VERSION ""

NS_ :

BS_:

BU_: EBOOST_HS CGM_HS BSM_HS HCP_B_HS AVM_HS PFAF_HS LVMPC_HS DCDC_HS TRCM_HS AMP_HS VICM2_HS FICM_HS ARS_HS MCP_B_HS MCP_A_HS ICCM_OBD_HS SAS_HS ACCM_HS VLBS_HS EBCM_OBD_HS HCP_T_HS EDI_HS HPCC_HS VITM_OBD_HS VICM_HS HCP_HS APPS_HS ICCM_HS EOCM_F_HS GPCM_HS VCM_HS HMIM_HS VES_HS Dummy_HS MCP_C_HS ONSTAR_HS EPS_HS TestTool_HS MCP_HS BCP_HS ALC_HS AHL_AFL_HS SADS_HS EPB_HS FCM_HS TCCM_HS RDCM_HS PTO_HS EBCM_HS ACC_HS BCM_HS TCM_HS ECM_HS

BO_ 2034 CCP_Data_Transmission_Object_HS: 8 PTO_HS
 SG_ DgnInf : 7|64@0+ (1,0) [0|1.84467440737096E+019] ""  TestTool_HS

BO_ 2032 CCP_Command_Receive_Object_HS: 8 TestTool_HS
 SG_ DgnInf : 7|64@0+ (1,0) [0|1.84467440737096E+019] ""  FCM_HS,PTO_HS

BO_ 563 Performance_Mode_Cust_Setings_HS: 5 EBCM_HS
 SG_ SPMCA_SusPrfMd6Avl : 32|1@0+ (1,0) [0|1] ""  BCM_HS
 SG_ SPMCA_SusPrfMd5Avl : 33|1@0+ (1,0) [0|1] ""  BCM_HS
 SG_ SPMCA_SusPrfMd4Avl : 34|1@0+ (1,0) [0|1] ""  BCM_HS
 SG_ SPMCA_SusPrfMd3Avl : 35|1@0+ (1,0) [0|1] ""  BCM_HS
 SG_ SPMCA_SusPrfMd2Avl : 36|1@0+ (1,0) [0|1] ""  BCM_HS
 SG_ SPMCA_SusPrfMd1Avl : 37|1@0+ (1,0) [0|1] ""  BCM_HS
 SG_ SPMCA_StrPrfMd6Avl : 24|1@0+ (1,0) [0|1] ""  BCM_HS
 SG_ SPMCA_StrPrfMd5Avl : 25|1@0+ (1,0) [0|1] ""  BCM_HS
 SG_ SPMCA_StrPrfMd4Avl : 26|1@0+ (1,0) [0|1] ""  BCM_HS
 SG_ SPMCA_StrPrfMd3Avl : 27|1@0+ (1,0) [0|1] ""  BCM_HS
 SG_ SPMCA_StrPrfMd2Avl : 28|1@0+ (1,0) [0|1] ""  BCM_HS
 SG_ SPMCA_StrPrfMd1Avl : 29|1@0+ (1,0) [0|1] ""  BCM_HS
 SG_ SPMCA_SndPrfMd6Avl : 16|1@0+ (1,0) [0|1] ""  BCM_HS
 SG_ SPMCA_SndPrfMd5Avl : 17|1@0+ (1,0) [0|1] ""  BCM_HS
 SG_ SPMCA_SndPrfMd4Avl : 18|1@0+ (1,0) [0|1] ""  BCM_HS
 SG_ SPMCA_SndPrfMd3Avl : 19|1@0+ (1,0) [0|1] ""  BCM_HS
 SG_ SPMCA_SndPrfMd2Avl : 20|1@0+ (1,0) [0|1] ""  BCM_HS
 SG_ SPMCA_SndPrfMd1Avl : 21|1@0+ (1,0) [0|1] ""  BCM_HS
 SG_ DPMCA_DispPrfMd6Avl : 8|1@0+ (1,0) [0|1] ""  BCM_HS
 SG_ DPMCA_DispPrfMd5Avl : 9|1@0+ (1,0) [0|1] ""  BCM_HS
 SG_ DPMCA_DispPrfMd4Avl : 10|1@0+ (1,0) [0|1] ""  BCM_HS
 SG_ DPMCA_DispPrfMd3Avl : 11|1@0+ (1,0) [0|1] ""  BCM_HS
 SG_ DPMCA_DispPrfMd2Avl : 12|1@0+ (1,0) [0|1] ""  BCM_HS
 SG_ DPMCA_DispPrfMd1Avl : 13|1@0+ (1,0) [0|1] ""  BCM_HS
 SG_ DPMCA_DrvlPrfMd6Avl : 0|1@0+ (1,0) [0|1] ""  BCM_HS
 SG_ DPMCA_DrvlPrfMd5Avl : 1|1@0+ (1,0) [0|1] ""  BCM_HS
 SG_ DPMCA_DrvlPrfMd4Avl : 2|1@0+ (1,0) [0|1] ""  BCM_HS
 SG_ DPMCA_DrvlPrfMd3Avl : 3|1@0+ (1,0) [0|1] ""  BCM_HS
 SG_ DPMCA_DrvlPrfMd2Avl : 4|1@0+ (1,0) [0|1] ""  BCM_HS
 SG_ DPMCA_DrvlPrfMd1Avl : 5|1@0+ (1,0) [0|1] ""  BCM_HS

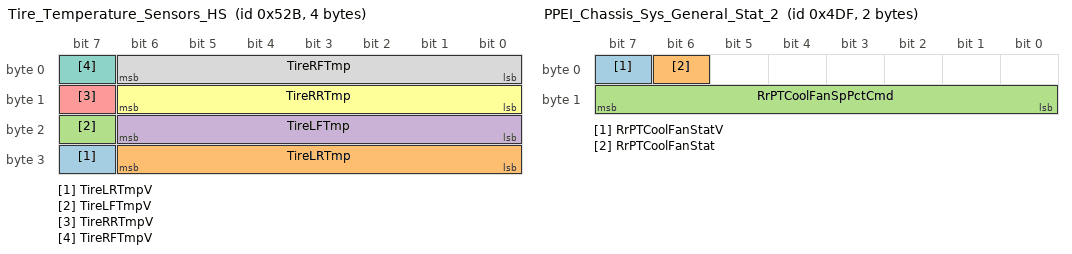
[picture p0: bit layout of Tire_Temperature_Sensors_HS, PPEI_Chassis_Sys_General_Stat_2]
BO_ 1323 Tire_Temperature_Sensors_HS: 4 BCM_HS
 SG_ TireLRTmpV : 31|1@0+ (1,0) [0|1] ""  CGM_HS,LVMPC_HS,EDI_HS,EBCM_OBD_HS,EBCM_HS,ICCM_OBD_HS,ICCM_HS,RDCM_HS
 SG_ TireLRTmp : 30|7@0+ (1,-20) [-20|107] "deg C"  CGM_HS,LVMPC_HS,EDI_HS,EBCM_OBD_HS,EBCM_HS,ICCM_OBD_HS,ICCM_HS,RDCM_HS
 SG_ TireLFTmpV : 23|1@0+ (1,0) [0|1] ""  CGM_HS,LVMPC_HS,EDI_HS,EBCM_OBD_HS,EBCM_HS,ICCM_OBD_HS,ICCM_HS,RDCM_HS
 SG_ TireLFTmp : 22|7@0+ (1,-20) [-20|107] "deg C"  CGM_HS,LVMPC_HS,EDI_HS,EBCM_OBD_HS,EBCM_HS,ICCM_OBD_HS,ICCM_HS,RDCM_HS
 SG_ TireRRTmpV : 15|1@0+ (1,0) [0|1] ""  CGM_HS,LVMPC_HS,EDI_HS,EBCM_OBD_HS,EBCM_HS,ICCM_OBD_HS,ICCM_HS,RDCM_HS
 SG_ TireRRTmp : 14|7@0+ (1,-20) [-20|107] "deg C"  CGM_HS,LVMPC_HS,EDI_HS,EBCM_OBD_HS,EBCM_HS,ICCM_OBD_HS,ICCM_HS,RDCM_HS
 SG_ TireRFTmpV : 7|1@0+ (1,0) [0|1] ""  CGM_HS,LVMPC_HS,EDI_HS,EBCM_OBD_HS,EBCM_HS,ICCM_OBD_HS,ICCM_HS,RDCM_HS
 SG_ TireRFTmp : 6|7@0+ (1,-20) [-20|107] "deg C"  CGM_HS,LVMPC_HS,EDI_HS,EBCM_OBD_HS,EBCM_HS,ICCM_OBD_HS,ICCM_HS,RDCM_HS

BO_ 1247 PPEI_Chassis_Sys_General_Stat_2: 2 ICCM_HS
 SG_ RrPTCoolFanStatV : 7|1@0+ (1,0) [0|1] ""  TCM_HS
 SG_ RrPTCoolFanStat : 6|1@0+ (1,0) [0|1] ""  TCM_HS
 SG_ RrPTCoolFanSpPctCmd : 15|8@0+ (0.392157,0) [0|100.000035] "%"  TCM_HS

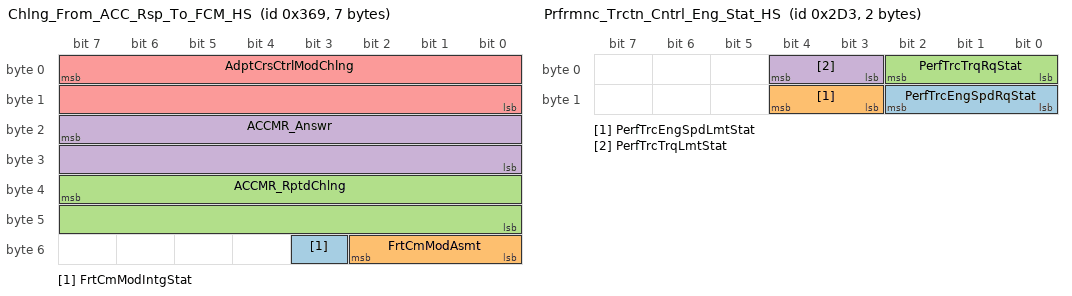
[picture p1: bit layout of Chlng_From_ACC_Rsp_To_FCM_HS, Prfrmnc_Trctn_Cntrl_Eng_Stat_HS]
BO_ 873 Chlng_From_ACC_Rsp_To_FCM_HS: 7 ACC_HS
 SG_ FrtCmModIntgStat : 51|1@0+ (1,0) [0|1] ""  FCM_HS
 SG_ FrtCmModAsmt : 50|3@0+ (1,0) [0|7] ""  FCM_HS
 SG_ ACCMR_RptdChlng : 39|16@0+ (1,0) [0|65535] ""  FCM_HS
 SG_ ACCMR_Answr : 23|16@0+ (1,0) [0|65535] ""  FCM_HS
 SG_ AdptCrsCtrlModChlng : 7|16@0+ (1,0) [0|65535] ""  FCM_HS

BO_ 306 Exhst_Heat_Recvry_Mngmnt_HS: 1 VICM2_HS
 SG_ ClntCrcFlwRtEst : 7|8@0+ (0.392157,0) [0|100.000035] "%"  BCM_HS

BO_ 723 Prfrmnc_Trctn_Cntrl_Eng_Stat_HS: 2 ECM_HS
 SG_ PerfTrcEngSpdRqStat : 10|3@0+ (1,0) [0|7] ""  EBCM_OBD_HS,EBCM_HS
 SG_ PerfTrcEngSpdLmtStat : 12|2@0+ (1,0) [0|3] ""  EBCM_OBD_HS,EBCM_HS
 SG_ PerfTrcTrqRqStat : 2|3@0+ (1,0) [0|7] ""  EBCM_OBD_HS,EBCM_HS
 SG_ PerfTrcTrqLmtStat : 4|2@0+ (1,0) [0|3] ""  EBCM_OBD_HS,EBCM_HS

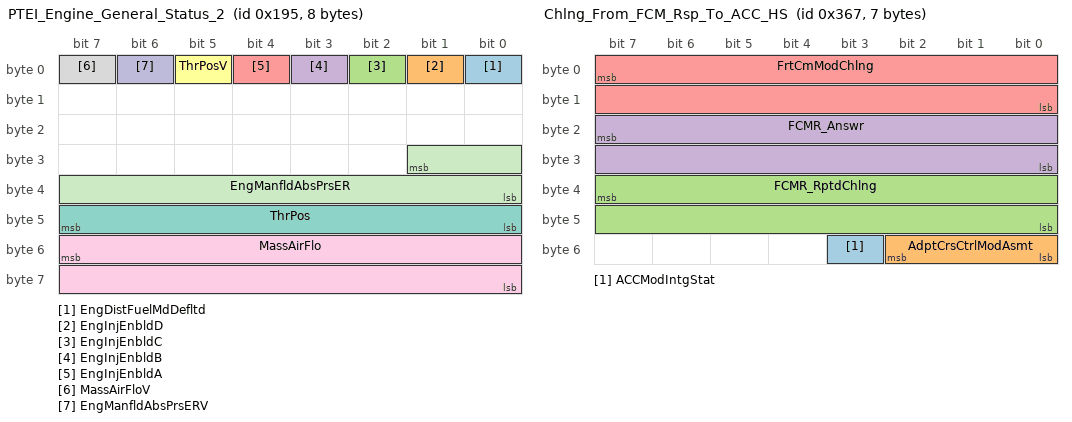
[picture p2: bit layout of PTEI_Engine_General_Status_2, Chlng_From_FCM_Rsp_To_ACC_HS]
BO_ 405 PTEI_Engine_General_Status_2: 8 ECM_HS
 SG_ EngDistFuelMdDefltd : 0|1@0+ (1,0) [0|1] ""  FICM_HS
 SG_ EngInjEnbldD : 1|1@0+ (1,0) [0|1] ""  FICM_HS
 SG_ EngInjEnbldC : 2|1@0+ (1,0) [0|1] ""  FICM_HS
 SG_ EngInjEnbldB : 3|1@0+ (1,0) [0|1] ""  FICM_HS
 SG_ EngInjEnbldA : 4|1@0+ (1,0) [0|1] ""  FICM_HS
 SG_ ThrPosV : 5|1@0+ (1,0) [0|1] ""  FICM_HS
 SG_ ThrPos : 47|8@0+ (0.392157,0) [0|100.000035] "%"  FICM_HS
 SG_ MassAirFloV : 7|1@0+ (1,0) [0|1] ""  VCM_HS,FICM_HS
 SG_ MassAirFlo : 55|16@0+ (0.01,0) [0|655.35] "grams/s"  VCM_HS,FICM_HS
 SG_ EngManfldAbsPrsERV : 6|1@0+ (1,0) [0|1] ""  FICM_HS
 SG_ EngManfldAbsPrsER : 25|10@0+ (0.5,0) [0|511.5] "kPa"  FICM_HS

BO_ 419 PTEI_Engine_Common_Use_1: 1 ECM_HS
 SG_ EngRunng : 7|1@0+ (1,0) [0|1] ""  HCP_B_HS,HCP_T_HS,BCM_HS,DCDC_HS,TCCM_HS,EBCM_OBD_HS,EBCM_HS,MCP_C_HS,MCP_B_HS,MCP_A_HS,FICM_HS,TCM_HS,HCP_HS,BCP_HS

BO_ 289 ADASIS_RawData_Multiplexed_HS: 8 HMIM_HS
 SG_ ARDM_RawData : 4|61@0+ (1,0) [0|2.30584300921369E+018] ""  Dummy_HS
 SG_ ARDM_MsgType : 7|3@0+ (1,0) [0|7] ""  Dummy_HS

BO_ 871 Chlng_From_FCM_Rsp_To_ACC_HS: 7 FCM_HS
 SG_ ACCModIntgStat : 51|1@0+ (1,0) [0|1] ""  ACC_HS
 SG_ AdptCrsCtrlModAsmt : 50|3@0+ (1,0) [0|7] ""  ACC_HS
 SG_ FCMR_RptdChlng : 39|16@0+ (1,0) [0|65535] ""  ACC_HS
 SG_ FCMR_Answr : 23|16@0+ (1,0) [0|65535] ""  ACC_HS
 SG_ FrtCmModChlng : 7|16@0+ (1,0) [0|65535] ""  ACC_HS

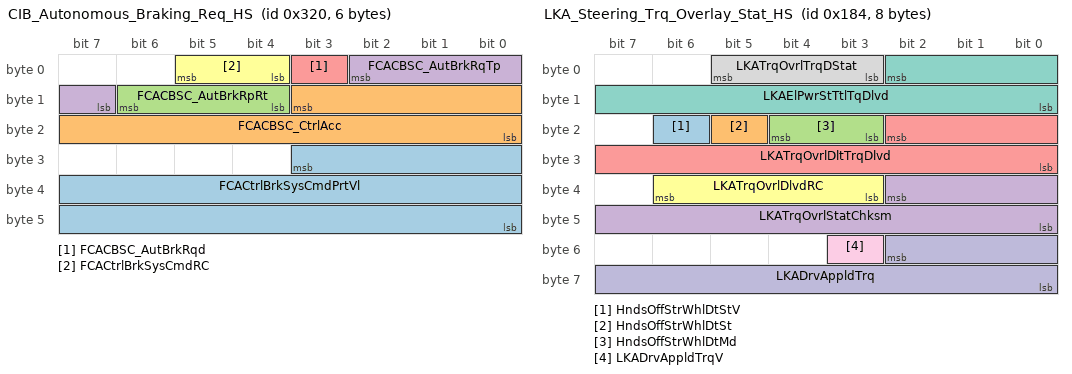
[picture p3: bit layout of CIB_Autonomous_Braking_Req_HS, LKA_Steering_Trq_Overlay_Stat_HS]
BO_ 800 CIB_Autonomous_Braking_Req_HS: 6 FCM_HS
 SG_ FCACtrlBrkSysCmdPrtVl : 27|20@0+ (1,0) [0|1048575] ""  EBCM_OBD_HS,EBCM_HS
 SG_ FCACBSC_CtrlAcc : 11|12@0- (0.01,0) [-20.48|20.47] "m/s^2"  EBCM_OBD_HS,EBCM_HS
 SG_ FCACBSC_AutBrkRpRt : 14|3@0+ (1,0) [0|7] ""  EBCM_OBD_HS,EBCM_HS
 SG_ FCACBSC_AutBrkRqTp : 2|4@0+ (1,0) [0|15] ""  EBCM_OBD_HS,EBCM_HS
 SG_ FCACBSC_AutBrkRqd : 3|1@0+ (1,0) [0|1] ""  EBCM_OBD_HS,EBCM_HS
 SG_ FCACtrlBrkSysCmdRC : 5|2@0+ (1,0) [0|3] ""  EBCM_OBD_HS,EBCM_HS

BO_ 388 LKA_Steering_Trq_Overlay_Stat_HS: 8 EPS_HS
 SG_ HndsOffStrWhlDtStV : 22|1@0+ (1,0) [0|1] ""  CGM_HS,EOCM_F_HS,FCM_HS
 SG_ HndsOffStrWhlDtSt : 21|1@0+ (1,0) [0|1] ""  CGM_HS,EOCM_F_HS,FCM_HS
 SG_ HndsOffStrWhlDtMd : 20|2@0+ (1,0) [0|3] ""  CGM_HS,EOCM_F_HS,FCM_HS
 SG_ LKATrqOvrlStatChksm : 34|11@0+ (1,0) [0|2047] ""  CGM_HS,EOCM_F_HS,FCM_HS
 SG_ LKATrqOvrlDltTrqDlvd : 18|11@0- (0.01,0) [-10.24|10.23] "Nm"  CGM_HS,EOCM_F_HS,FCM_HS
 SG_ LKATrqOvrlDlvdRC : 38|4@0+ (1,0) [0|15] ""  CGM_HS,EOCM_F_HS,FCM_HS
 SG_ LKAElPwrStTtlTqDlvd : 2|11@0- (0.01,0) [-10.24|10.23] "Nm"  CGM_HS,EOCM_F_HS,FCM_HS
 SG_ LKATrqOvrlTrqDStat : 5|3@0+ (1,0) [0|7] ""  CGM_HS,EOCM_F_HS,FCM_HS
 SG_ LKADrvAppldTrqV : 51|1@0+ (1,0) [0|1] ""  CGM_HS,EOCM_F_HS,FCM_HS
 SG_ LKADrvAppldTrq : 50|11@0- (0.01,0) [-10.24|10.23] "Nm"  CGM_HS,EOCM_F_HS,FCM_HS

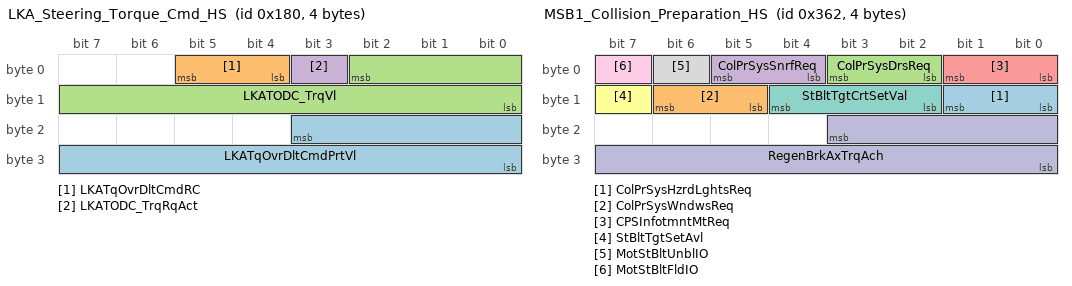
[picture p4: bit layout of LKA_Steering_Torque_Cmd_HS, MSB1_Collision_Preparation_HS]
BO_ 384 LKA_Steering_Torque_Cmd_HS: 4 FCM_HS
 SG_ LKATqOvrDltCmdPrtVl : 19|12@0+ (1,0) [0|4095] ""  EPS_HS
 SG_ LKATqOvrDltCmdRC : 5|2@0+ (1,0) [0|3] ""  EPS_HS
 SG_ LKATODC_TrqVl : 2|11@0- (0.01,0) [-10.24|10.23] "Nm"  BCM_HS,EPS_HS
 SG_ LKATODC_TrqRqAct : 3|1@0+ (1,0) [0|1] ""  BCM_HS,EPS_HS

BO_ 866 MSB1_Collision_Preparation_HS: 4 EBCM_HS
 SG_ ColPrSysHzrdLghtsReq : 9|2@0+ (1,0) [0|3] ""  BCM_HS
 SG_ ColPrSysWndwsReq : 14|2@0+ (1,0) [0|3] ""  BCM_HS
 SG_ ColPrSysDrsReq : 3|2@0+ (1,0) [0|3] ""  BCM_HS
 SG_ ColPrSysSnrfReq : 5|2@0+ (1,0) [0|3] ""  BCM_HS
 SG_ CPSInfotmntMtReq : 1|2@0+ (1,0) [0|3] ""  BCM_HS
 SG_ StBltTgtSetAvl : 15|1@0+ (1,0) [0|1] ""  BCM_HS
 SG_ StBltTgtCrtSetVal : 12|3@0+ (1,0) [0|7] ""  BCM_HS
 SG_ MotStBltUnblIO : 6|1@0+ (1,0) [0|1] ""  BCM_HS
 SG_ MotStBltFldIO : 7|1@0+ (1,0) [0|1] ""  BCM_HS
 SG_ RegenBrkAxTrqAch : 19|12@0+ (2,0) [0|8190] "Nm"  BSM_HS,VICM_HS

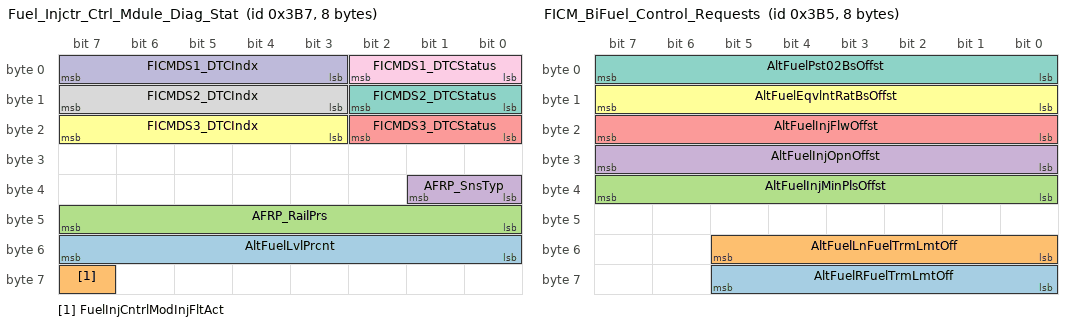
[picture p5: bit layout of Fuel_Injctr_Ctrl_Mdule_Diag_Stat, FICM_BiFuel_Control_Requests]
BO_ 951 Fuel_Injctr_Ctrl_Mdule_Diag_Stat: 8 FICM_HS
 SG_ AltFuelLvlPrcnt : 55|8@0+ (0.392157,0) [0|100.000035] "%"  ECM_HS
 SG_ FuelInjCntrlModInjFltAct : 63|1@0+ (1,0) [0|1] ""  ECM_HS
 SG_ AFRP_RailPrs : 47|8@0+ (3,0) [0|765] "kPa"  ECM_HS
 SG_ AFRP_SnsTyp : 33|2@0+ (1,0) [0|3] ""  ECM_HS
 SG_ FICMDS3_DTCStatus : 18|3@0+ (1,0) [0|7] ""  ECM_HS
 SG_ FICMDS3_DTCIndx : 23|5@0+ (1,0) [0|31] ""  ECM_HS
 SG_ FICMDS2_DTCStatus : 10|3@0+ (1,0) [0|7] ""  ECM_HS
 SG_ FICMDS2_DTCIndx : 15|5@0+ (1,0) [0|31] ""  ECM_HS
 SG_ FICMDS1_DTCStatus : 2|3@0+ (1,0) [0|7] ""  ECM_HS
 SG_ FICMDS1_DTCIndx : 7|5@0+ (1,0) [0|31] ""  ECM_HS

BO_ 949 FICM_BiFuel_Control_Requests: 8 FICM_HS
 SG_ AltFuelRFuelTrmLmtOff : 61|6@0- (0.01,0) [-0.32|0.31] ""  ECM_HS
 SG_ AltFuelLnFuelTrmLmtOff : 53|6@0- (0.01,0) [-0.32|0.31] ""  ECM_HS
 SG_ AltFuelInjMinPlsOffst : 39|8@0- (0.0313725,0) [-4.01568|3.9843075] "grams/s"  ECM_HS
 SG_ AltFuelInjOpnOffst : 31|8@0- (0.0313725,0) [-4.01568|3.9843075] "grams/s"  ECM_HS
 SG_ AltFuelInjFlwOffst : 23|8@0- (0.0313725,0) [-4.01568|3.9843075] "grams/s"  ECM_HS
 SG_ AltFuelEqvlntRatBsOffst : 15|8@0- (0.000392157,0) [-0.050196096|0.049803939] ""  ECM_HS
 SG_ AltFuelPst02BsOffst : 7|8@0- (4,0) [-512|508] "mVolts"  ECM_HS

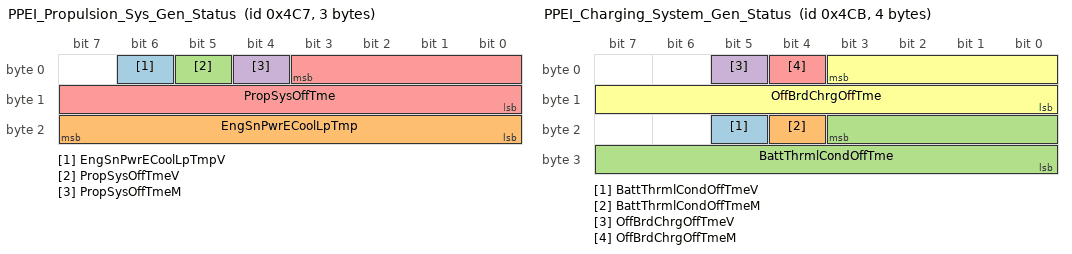
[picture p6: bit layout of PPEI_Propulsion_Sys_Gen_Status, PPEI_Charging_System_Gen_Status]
BO_ 1223 PPEI_Propulsion_Sys_Gen_Status: 3 ECM_HS
 SG_ EngSnPwrECoolLpTmpV : 6|1@0+ (1,0) [0|1] ""  BSM_HS,VICM_HS
 SG_ EngSnPwrECoolLpTmp : 23|8@0+ (1,-40) [-40|215] "deg C"  BSM_HS,VICM_HS
 SG_ PropSysOffTmeV : 5|1@0+ (1,0) [0|1] ""  HCP_B_HS,HCP_T_HS,VICM2_HS,EBCM_OBD_HS,EBCM_HS,MCP_C_HS,TCM_HS,HCP_HS,BCP_HS,MCP_B_HS,MCP_A_HS,BSM_HS,VICM_HS
 SG_ PropSysOffTmeM : 4|1@0+ (1,0) [0|1] ""  HCP_B_HS,BSM_HS,HCP_T_HS,VICM2_HS,EBCM_OBD_HS,EBCM_HS,MCP_C_HS,TCM_HS,HCP_HS,BCP_HS,MCP_B_HS,MCP_A_HS,VICM_HS
 SG_ PropSysOffTme : 3|12@0+ (0.5,0) [0|2047.5] "min"  HCP_B_HS,BSM_HS,HCP_T_HS,VICM2_HS,EBCM_OBD_HS,EBCM_HS,MCP_C_HS,TCM_HS,HCP_HS,BCP_HS,MCP_B_HS,MCP_A_HS,VICM_HS

BO_ 1227 PPEI_Charging_System_Gen_Status: 4 VICM_HS
 SG_ BattThrmlCondOffTmeV : 21|1@0+ (1,0) [0|1] ""  HCP_T_HS,MCP_C_HS,TCM_HS,HCP_HS,MCP_B_HS,MCP_A_HS,ECM_HS
 SG_ BattThrmlCondOffTmeM : 20|1@0+ (1,0) [0|1] ""  HCP_T_HS,MCP_C_HS,TCM_HS,HCP_HS,MCP_B_HS,MCP_A_HS,ECM_HS
 SG_ BattThrmlCondOffTme : 19|12@0+ (0.5,0) [0|2047.5] "min"  HCP_T_HS,MCP_C_HS,TCM_HS,HCP_HS,MCP_B_HS,MCP_A_HS,ECM_HS
 SG_ OffBrdChrgOffTmeV : 5|1@0+ (1,0) [0|1] ""  HCP_T_HS,MCP_C_HS,TCM_HS,HCP_HS,MCP_B_HS,MCP_A_HS,ECM_HS
 SG_ OffBrdChrgOffTmeM : 4|1@0+ (1,0) [0|1] ""  HCP_T_HS,MCP_C_HS,TCM_HS,HCP_HS,MCP_B_HS,MCP_A_HS,ECM_HS
 SG_ OffBrdChrgOffTme : 3|12@0+ (0.5,0) [0|2047.5] "min"  HCP_T_HS,MCP_C_HS,TCM_HS,HCP_HS,MCP_B_HS,MCP_A_HS,ECM_HS

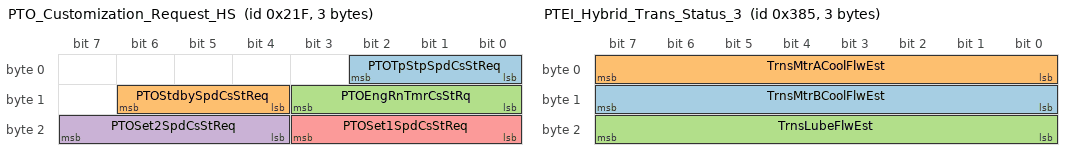
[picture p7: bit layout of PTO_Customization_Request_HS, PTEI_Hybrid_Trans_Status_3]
BO_ 543 PTO_Customization_Request_HS: 3 BCM_HS
 SG_ PTOTpStpSpdCsStReq : 2|3@0+ (1,0) [0|7] ""  PTO_HS
 SG_ PTOStdbySpdCsStReq : 14|3@0+ (1,0) [0|7] ""  PTO_HS
 SG_ PTOEngRnTmrCsStRq : 11|4@0+ (1,0) [0|15] ""  PTO_HS
 SG_ PTOSet2SpdCsStReq : 23|4@0+ (1,0) [0|15] ""  PTO_HS
 SG_ PTOSet1SpdCsStReq : 19|4@0+ (1,0) [0|15] ""  PTO_HS

BO_ 544 PTO_Status_HS: 5 PTO_HS
 SG_ PTOMobModTrnsInGrIO : 31|1@0+ (1,0) [0|1] ""  BCM_HS
 SG_ PTOManTransInGrIO : 21|1@0+ (1,0) [0|1] ""  BCM_HS
 SG_ PTOServIndOn : 20|1@0+ (1,0) [0|1] ""  BCM_HS
 SG_ PTOEngUpnBrkRelIO : 23|1@0+ (1,0) [0|1] ""  BCM_HS
 SG_ PTOAccelUpnBrkRelIO : 22|1@0+ (1,0) [0|1] ""  BCM_HS
 SG_ PTOAudExtAlertReq : 19|1@0+ (1,0) [0|1] ""  BCM_HS
 SG_ PTOTransInGearIO : 13|1@0+ (1,0) [0|1] ""  BCM_HS
 SG_ PTOTpStpSpdCsStAvl : 10|1@0+ (1,0) [0|1] ""  BCM_HS
 SG_ PTOTpStSpdCsCrStVal : 26|3@0+ (1,0) [0|7] ""  BCM_HS
 SG_ PTOStdbySpdCsStAvl : 12|1@0+ (1,0) [0|1] ""  BCM_HS
 SG_ PTOStdbSpdCsCrStVal : 18|3@0+ (1,0) [0|7] ""  BCM_HS
 SG_ PTOSetPrkBrkIO : 14|1@0+ (1,0) [0|1] ""  BCM_HS
 SG_ PTOSet2SpdCsStAvl : 9|1@0+ (1,0) [0|1] ""  BCM_HS
 SG_ PTOSet2SpdCsCrStVal : 39|4@0+ (1,0) [0|15] ""  BCM_HS
 SG_ PTOSet1SpdCsStAvl : 8|1@0+ (1,0) [0|1] ""  BCM_HS
 SG_ PTOSet1SpdCsCrStVal : 35|4@0+ (1,0) [0|15] ""  BCM_HS
 SG_ PTORelCltPedIO : 15|1@0+ (1,0) [0|1] ""  BCM_HS
 SG_ PTORelBrkPedIO : 0|1@0+ (1,0) [0|1] ""  BCM_HS
 SG_ PTORelAccPedIO : 1|1@0+ (1,0) [0|1] ""  BCM_HS
 SG_ PTORedEngSpdIO : 2|1@0+ (1,0) [0|1] ""  BCM_HS
 SG_ PTOPrsRelCltPedIO : 3|1@0+ (1,0) [0|1] ""  BCM_HS
 SG_ PTOPrsRelBrkPedIO : 4|1@0+ (1,0) [0|1] ""  BCM_HS
 SG_ PTOEngRnTmrCsStAvl : 11|1@0+ (1,0) [0|1] ""  BCM_HS
 SG_ PTOEnRnTmCsCrStVal : 30|4@0+ (1,0) [0|15] ""  BCM_HS
 SG_ PTOEngmntStatInd : 6|2@0+ (1,0) [0|3] ""  BCM_HS
 SG_ PTODisengCrsCntlIO : 7|1@0+ (1,0) [0|1] ""  BCM_HS

BO_ 901 PTEI_Hybrid_Trans_Status_3: 3 TCM_HS
 SG_ TrnsMtrBCoolFlwEst : 15|8@0+ (0.05,0) [0|12.75] "l/min"  HCP_HS
 SG_ TrnsMtrACoolFlwEst : 7|8@0+ (0.05,0) [0|12.75] "l/min"  HCP_HS
 SG_ TrnsLubeFlwEst : 23|8@0+ (0.0625,0) [0|15.9375] "l/min"  HCP_HS

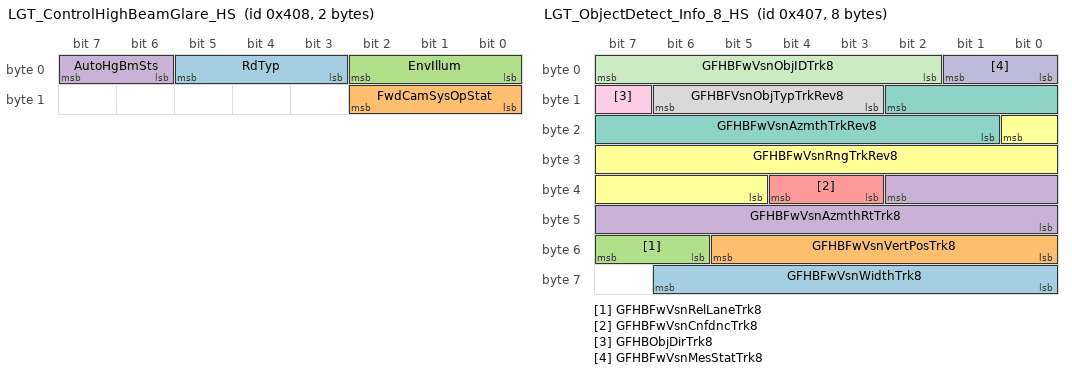
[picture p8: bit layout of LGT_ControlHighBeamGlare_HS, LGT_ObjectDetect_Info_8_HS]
BO_ 1032 LGT_ControlHighBeamGlare_HS: 2 FCM_HS
 SG_ RdTyp : 5|3@0+ (1,0) [0|7] ""  AHL_AFL_HS
 SG_ FwdCamSysOpStat : 10|3@0+ (1,0) [0|7] ""  AHL_AFL_HS
 SG_ EnvIllum : 2|3@0+ (1,0) [0|7] ""  AHL_AFL_HS
 SG_ AutoHgBmSts : 7|2@0+ (1,0) [0|3] ""  AHL_AFL_HS

BO_ 1031 LGT_ObjectDetect_Info_8_HS: 8 EOCM_F_HS
 SG_ GFHBFwVsnWidthTrk8 : 62|7@0+ (0.1,0) [0|12.7] "deg"  AHL_AFL_HS
 SG_ GFHBFwVsnVertPosTrk8 : 53|6@0+ (0.25,-3) [-3|12.75] "deg"  AHL_AFL_HS
 SG_ GFHBFwVsnRelLaneTrk8 : 55|2@0+ (1,0) [0|3] ""  AHL_AFL_HS
 SG_ GFHBFwVsnAzmthRtTrk8 : 34|11@0- (0.125,0) [-128|127.875] "deg/s"  AHL_AFL_HS
 SG_ GFHBFwVsnCnfdncTrk8 : 36|2@0+ (1,0) [0|3] ""  AHL_AFL_HS
 SG_ GFHBFwVsnRngTrkRev8 : 16|12@0+ (0.2,0) [0|819] "m"  AHL_AFL_HS
 SG_ GFHBFwVsnAzmthTrkRev8 : 10|10@0- (0.05,0) [-25.6|25.55] "deg"  AHL_AFL_HS
 SG_ GFHBFVsnObjTypTrkRev8 : 14|4@0+ (1,0) [0|15] ""  AHL_AFL_HS
 SG_ GFHBObjDirTrk8 : 15|1@0+ (1,0) [0|1] ""  AHL_AFL_HS
 SG_ GFHBFwVsnMesStatTrk8 : 1|2@0+ (1,0) [0|3] ""  AHL_AFL_HS
 SG_ GFHBFwVsnObjIDTrk8 : 7|6@0+ (1,0) [0|63] ""  AHL_AFL_HS

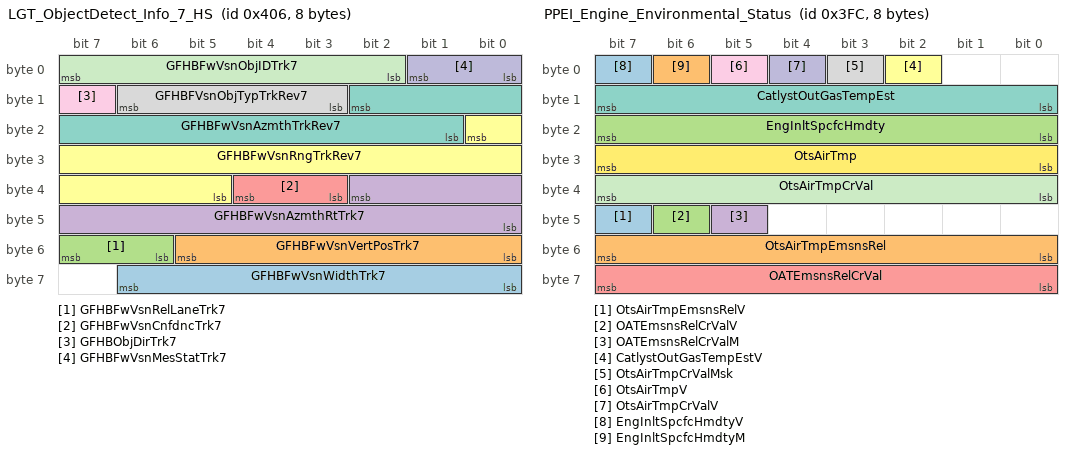
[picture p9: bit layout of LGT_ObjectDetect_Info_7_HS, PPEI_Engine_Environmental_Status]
BO_ 1030 LGT_ObjectDetect_Info_7_HS: 8 EOCM_F_HS
 SG_ GFHBFwVsnWidthTrk7 : 62|7@0+ (0.1,0) [0|12.7] "deg"  AHL_AFL_HS
 SG_ GFHBFwVsnVertPosTrk7 : 53|6@0+ (0.25,-3) [-3|12.75] "deg"  AHL_AFL_HS
 SG_ GFHBFwVsnRelLaneTrk7 : 55|2@0+ (1,0) [0|3] ""  AHL_AFL_HS
 SG_ GFHBFwVsnAzmthRtTrk7 : 34|11@0- (0.125,0) [-128|127.875] "deg/s"  AHL_AFL_HS
 SG_ GFHBFwVsnCnfdncTrk7 : 36|2@0+ (1,0) [0|3] ""  AHL_AFL_HS
 SG_ GFHBFwVsnRngTrkRev7 : 16|12@0+ (0.2,0) [0|819] "m"  AHL_AFL_HS
 SG_ GFHBFwVsnAzmthTrkRev7 : 10|10@0- (0.05,0) [-25.6|25.55] "deg"  AHL_AFL_HS
 SG_ GFHBFVsnObjTypTrkRev7 : 14|4@0+ (1,0) [0|15] ""  AHL_AFL_HS
 SG_ GFHBObjDirTrk7 : 15|1@0+ (1,0) [0|1] ""  AHL_AFL_HS
 SG_ GFHBFwVsnMesStatTrk7 : 1|2@0+ (1,0) [0|3] ""  AHL_AFL_HS
 SG_ GFHBFwVsnObjIDTrk7 : 7|6@0+ (1,0) [0|63] ""  AHL_AFL_HS

BO_ 479 PPEI_Propulsion_Gen_Stat_1_HS: 4 HCP_HS
 SG_ EngAutoStpNotProb : 2|1@0+ (1,0) [0|1] ""  CGM_HS,TCM_HS,ECM_HS,BCM_HS
 SG_ EASSI_UnsdRsrvd2 : 8|1@0+ (1,0) [0|1] ""  CGM_HS,TCM_HS,ECM_HS,BCM_HS,EBCM_OBD_HS,EBCM_HS
 SG_ EASSI_StlDetd : 10|1@0+ (1,0) [0|1] ""  CGM_HS,TCM_HS,ECM_HS,BCM_HS,EBCM_OBD_HS,EBCM_HS
 SG_ EASSI_TrqDetd : 11|1@0+ (1,0) [0|1] ""  CGM_HS,TCM_HS,ECM_HS,BCM_HS,EBCM_OBD_HS,EBCM_HS
 SG_ EASSI_FuelReqOn : 12|1@0+ (1,0) [0|1] ""  CGM_HS,TCM_HS,ECM_HS,BCM_HS,EBCM_OBD_HS,EBCM_HS
 SG_ EASSI_StrtTyp : 15|3@0+ (1,0) [0|7] ""  CGM_HS,TCM_HS,ECM_HS,BCM_HS,EBCM_OBD_HS,EBCM_HS
 SG_ EASSI_StrtStpSt : 1|2@0+ (1,0) [0|3] ""  CGM_HS,TCM_HS,ECM_HS,BCM_HS,EBCM_OBD_HS,EBCM_HS
 SG_ EASSI_TorqDetdIndet : 9|1@0+ (1,0) [0|1] ""  CGM_HS,TCM_HS,ECM_HS,BCM_HS,EBCM_OBD_HS,EBCM_HS
 SG_ ASIRI_Indication08 : 16|1@0+ (1,0) [0|1] ""  CGM_HS,BCM_HS
 SG_ ASIRI_Indication07 : 17|1@0+ (1,0) [0|1] ""  CGM_HS,BCM_HS
 SG_ ASIRI_Indication06 : 18|1@0+ (1,0) [0|1] ""  CGM_HS,BCM_HS
 SG_ ASIRI_Indication05 : 19|1@0+ (1,0) [0|1] ""  CGM_HS,BCM_HS
 SG_ ASIRI_Indication04 : 20|1@0+ (1,0) [0|1] ""  CGM_HS,BCM_HS
 SG_ ASIRI_Indication03 : 21|1@0+ (1,0) [0|1] ""  CGM_HS,BCM_HS
 SG_ ASIRI_Indication02 : 22|1@0+ (1,0) [0|1] ""  CGM_HS,BCM_HS
 SG_ ASIRI_Indication01 : 23|1@0+ (1,0) [0|1] ""  CGM_HS,BCM_HS
 SG_ PTWrmgWtToShftIO : 5|1@0+ (1,0) [0|1] ""  CGM_HS,BCM_HS
 SG_ PrplsnSysAtv : 7|1@0+ (1,0) [0|1] ""  EBOOST_HS,CGM_HS,HCP_T_HS,EPB_HS,TCM_HS,ECM_HS,TCCM_HS,BSM_HS,VICM_HS,ICCM_OBD_HS,ICCM_HS,EBCM_OBD_HS,EBCM_HS,VICM2_HS,VITM_OBD_HS
 SG_ PTShftLvrLckRqd : 6|1@0+ (1,0) [0|1] ""  CGM_HS,BCM_HS

BO_ 211 PPEI_Hybrid_General_Status_3_HS: 2 HCP_HS
 SG_ ActAxleTrqV : 7|1@0+ (1,0) [0|1] ""  CGM_HS,HCP_T_HS,FCM_HS,SADS_HS,ICCM_OBD_HS,ICCM_HS,TCM_HS,ECM_HS,EPS_HS,EBCM_OBD_HS,EBCM_HS,BCP_HS,BSM_HS,VICM_HS,TCCM_HS,ACC_HS
 SG_ ActAxleTrq : 6|15@0+ (2,-22534) [-22534|43000] "Nm"  CGM_HS,HCP_T_HS,FCM_HS,SADS_HS,ICCM_OBD_HS,ICCM_HS,EBCM_OBD_HS,EBCM_HS,TCM_HS,ECM_HS,BCP_HS,EPS_HS,TCCM_HS,BSM_HS,VICM_HS,ACC_HS

BO_ 1020 PPEI_Engine_Environmental_Status: 8 ECM_HS
 SG_ OtsAirTmpEmsnsRelV : 47|1@0+ (1,0) [0|1] ""  CGM_HS,BSM_HS,VICM_HS,HCP_B_HS
 SG_ OtsAirTmpEmsnsRel : 55|8@0+ (0.5,-40) [-40|87.5] "deg C"  CGM_HS,BSM_HS,VICM_HS,HCP_B_HS
 SG_ OATEmsnsRelCrValV : 46|1@0+ (1,0) [0|1] ""  CGM_HS,BSM_HS,VICM_HS,HCP_B_HS
 SG_ OATEmsnsRelCrValM : 45|1@0+ (1,0) [0|1] ""  CGM_HS,BSM_HS,VICM_HS,HCP_B_HS
 SG_ OATEmsnsRelCrVal : 63|8@0+ (0.5,-40) [-40|87.5] "deg C"  CGM_HS,BSM_HS,VICM_HS,HCP_B_HS
 SG_ CatlystOutGasTempEstV : 2|1@0+ (1,0) [0|1] ""  CGM_HS,BSM_HS,VICM_HS
 SG_ CatlystOutGasTempEst : 15|8@0+ (5,-40) [-40|1235] "deg C"  CGM_HS,BSM_HS,VICM_HS
 SG_ OtsAirTmpCrValMsk : 3|1@0+ (1,0) [0|1] ""  TCM_HS,CGM_HS,EPB_HS,BSM_HS,VICM_HS,BCM_HS
 SG_ OtsAirTmpV : 5|1@0+ (1,0) [0|1] ""  CGM_HS,EPB_HS,BSM_HS,VICM_HS,PFAF_HS,BCM_HS
 SG_ OtsAirTmpCrValV : 4|1@0+ (1,0) [0|1] ""  TCM_HS,CGM_HS,EPB_HS,BSM_HS,VICM_HS,BCM_HS
 SG_ OtsAirTmpCrVal : 39|8@0+ (0.5,-40) [-40|87.5] "deg C"  TCM_HS,CGM_HS,EPB_HS,BSM_HS,VICM_HS,BCM_HS
 SG_ OtsAirTmp : 31|8@0+ (0.5,-40) [-40|87.5] "deg C"  CGM_HS,EPB_HS,BSM_HS,VICM_HS,PFAF_HS,BCM_HS
 SG_ EngInltSpcfcHmdtyV : 7|1@0+ (1,0) [0|1] ""  CGM_HS,BSM_HS,VICM_HS,BCM_HS,EBCM_OBD_HS,EBCM_HS
 SG_ EngInltSpcfcHmdtyM : 6|1@0+ (1,0) [0|1] ""  CGM_HS,BSM_HS,VICM_HS,BCM_HS,EBCM_OBD_HS,EBCM_HS
 SG_ EngInltSpcfcHmdty : 23|8@0+ (0.0196078,0) [0|4.999989] "% water"  CGM_HS,BSM_HS,VICM_HS,BCM_HS,EBCM_OBD_HS,EBCM_HS

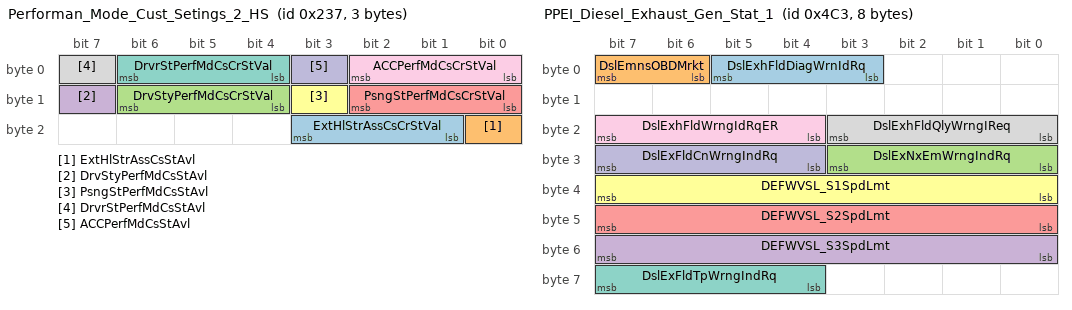
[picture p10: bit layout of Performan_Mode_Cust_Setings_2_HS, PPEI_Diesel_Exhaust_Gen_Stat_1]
BO_ 567 Performan_Mode_Cust_Setings_2_HS: 3 EBCM_HS
 SG_ ExtHlStrAssCsCrStVal : 19|3@0+ (1,0) [0|7] ""  BCM_HS
 SG_ ExtHlStrAssCsStAvl : 16|1@0+ (1,0) [0|1] ""  BCM_HS
 SG_ DrvStyPerfMdCsCrStVal : 14|3@0+ (1,0) [0|7] ""  BCM_HS
 SG_ DrvStyPerfMdCsStAvl : 15|1@0+ (1,0) [0|1] ""  BCM_HS
 SG_ PsngStPerfMdCsCrStVal : 10|3@0+ (1,0) [0|7] ""  BCM_HS
 SG_ PsngStPerfMdCsStAvl : 11|1@0+ (1,0) [0|1] ""  BCM_HS
 SG_ DrvrStPerfMdCsCrStVal : 6|3@0+ (1,0) [0|7] ""  BCM_HS
 SG_ DrvrStPerfMdCsStAvl : 7|1@0+ (1,0) [0|1] ""  BCM_HS
 SG_ ACCPerfMdCsCrStVal : 2|3@0+ (1,0) [0|7] ""  BCM_HS
 SG_ ACCPerfMdCsStAvl : 3|1@0+ (1,0) [0|1] ""  BCM_HS

BO_ 1219 PPEI_Diesel_Exhaust_Gen_Stat_1: 8 ECM_HS
 SG_ DslExhFldDiagWrnIdRq : 5|3@0+ (1,0) [0|7] ""  CGM_HS,BCM_HS
 SG_ DslEmnsOBDMrkt : 7|2@0+ (1,0) [0|3] ""  CGM_HS,BCM_HS
 SG_ DslExNxEmWrngIndRq : 27|4@0+ (1,0) [0|15] ""  CGM_HS,BCM_HS
 SG_ DEFWVSL_S3SpdLmt : 55|8@0+ (1,0) [0|255] "km / h"  CGM_HS,BCM_HS
 SG_ DEFWVSL_S2SpdLmt : 47|8@0+ (1,0) [0|255] "km / h"  CGM_HS,BCM_HS
 SG_ DEFWVSL_S1SpdLmt : 39|8@0+ (1,0) [0|255] "km / h"  CGM_HS,BCM_HS
 SG_ DslExFldTpWrngIndRq : 63|4@0+ (1,0) [0|15] ""  CGM_HS,BCM_HS
 SG_ DslExhFldQlyWrngIReq : 19|4@0+ (1,0) [0|15] ""  CGM_HS,BCM_HS
 SG_ DslExhFldWrngIdRqER : 23|4@0+ (1,0) [0|15] ""  CGM_HS,BCM_HS,ONSTAR_HS
 SG_ DslExFldCnWrngIndRq : 31|4@0+ (1,0) [0|15] ""  CGM_HS,BCM_HS

BO_ 372 Active_Rear_Steer_Fail_Indctn_HS: 1 ARS_HS
 SG_ ARSFlrIO : 0|1@0+ (1,0) [0|1] ""  BCM_HS

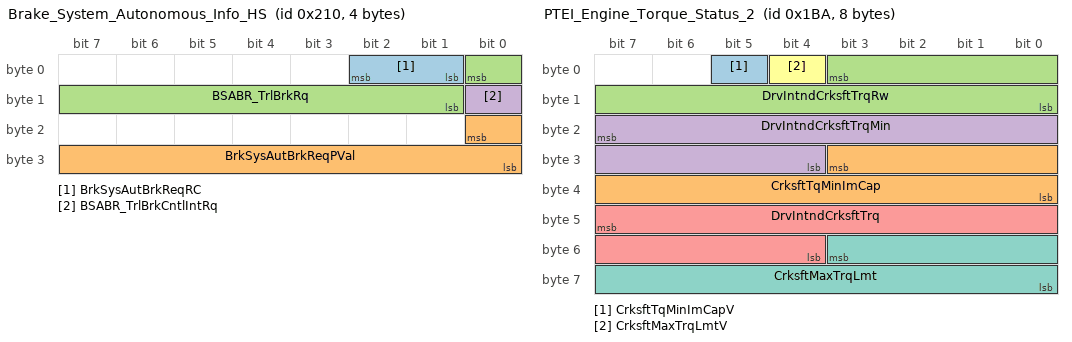
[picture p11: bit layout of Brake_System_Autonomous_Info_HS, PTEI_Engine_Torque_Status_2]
BO_ 528 Brake_System_Autonomous_Info_HS: 4 EBCM_HS
 SG_ BrkSysAutBrkReqRC : 2|2@0+ (1,0) [0|3] ""  ICCM_OBD_HS,ICCM_HS
 SG_ BrkSysAutBrkReqPVal : 16|9@0+ (1,0) [0|511] ""  ICCM_OBD_HS,ICCM_HS
 SG_ BSABR_TrlBrkRq : 0|8@0+ (0.392157,0) [0|100.000035] "%"  ICCM_OBD_HS,ICCM_HS
 SG_ BSABR_TrlBrkCntlIntRq : 8|1@0+ (1,0) [0|1] ""  ICCM_OBD_HS,ICCM_HS

BO_ 442 PTEI_Engine_Torque_Status_2: 8 ECM_HS
 SG_ CrksftTqMinImCapV : 5|1@0+ (1,0) [0|1] ""  TCM_HS
 SG_ CrksftTqMinImCap : 27|12@0+ (0.5,-848) [-848|1199.5] "Nm"  TCM_HS
 SG_ DrvIntndCrksftTrqRw : 3|12@0+ (0.5,-848) [-848|1199.5] "Nm"  TCM_HS
 SG_ DrvIntndCrksftTrqMin : 23|12@0+ (0.5,-848) [-848|1199.5] "Nm"  TCM_HS
 SG_ DrvIntndCrksftTrq : 47|12@0+ (0.5,-848) [-848|1199.5] "Nm"  TCM_HS
 SG_ CrksftMaxTrqLmtV : 4|1@0+ (1,0) [0|1] ""  TCM_HS
 SG_ CrksftMaxTrqLmt : 51|12@0+ (0.5,-848) [-848|1199.5] "Nm"  TCM_HS

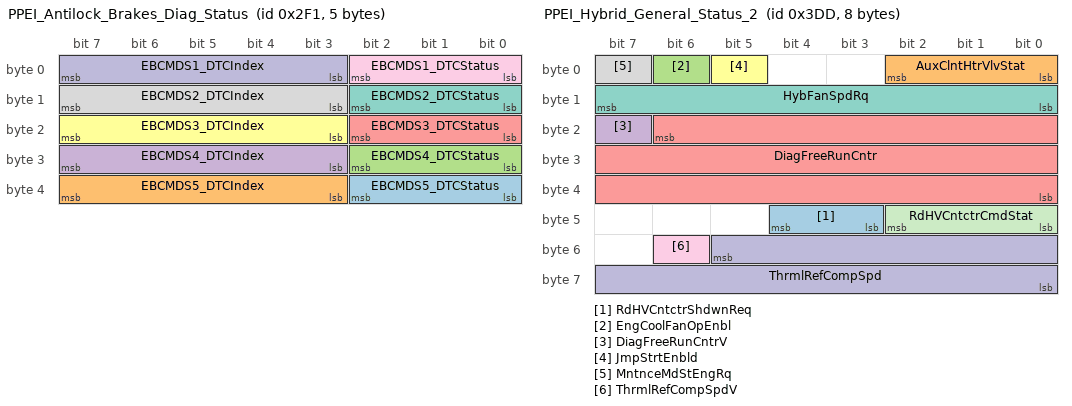
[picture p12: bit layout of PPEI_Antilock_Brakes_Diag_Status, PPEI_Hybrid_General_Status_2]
BO_ 753 PPEI_Antilock_Brakes_Diag_Status: 5 EBCM_HS
 SG_ EBCMDS5_DTCStatus : 34|3@0+ (1,0) [0|7] ""  ECM_HS
 SG_ EBCMDS5_DTCIndex : 39|5@0+ (1,0) [0|31] ""  ECM_HS
 SG_ EBCMDS4_DTCStatus : 26|3@0+ (1,0) [0|7] ""  ECM_HS
 SG_ EBCMDS4_DTCIndex : 31|5@0+ (1,0) [0|31] ""  ECM_HS
 SG_ EBCMDS3_DTCStatus : 18|3@0+ (1,0) [0|7] ""  ECM_HS
 SG_ EBCMDS3_DTCIndex : 23|5@0+ (1,0) [0|31] ""  ECM_HS
 SG_ EBCMDS2_DTCStatus : 10|3@0+ (1,0) [0|7] ""  ECM_HS
 SG_ EBCMDS2_DTCIndex : 15|5@0+ (1,0) [0|31] ""  ECM_HS
 SG_ EBCMDS1_DTCStatus : 2|3@0+ (1,0) [0|7] ""  ECM_HS
 SG_ EBCMDS1_DTCIndex : 7|5@0+ (1,0) [0|31] ""  ECM_HS

BO_ 989 PPEI_Hybrid_General_Status_2: 8 VICM_HS
 SG_ RdHVCntctrShdwnReq : 44|2@0+ (1,0) [0|3] ""  HCP_T_HS,HCP_HS,HCP_B_HS
 SG_ AuxClntHtrVlvStat : 2|3@0+ (1,0) [0|7] ""  ECM_HS
 SG_ EngCoolFanOpEnbl : 6|1@0+ (1,0) [0|1] ""  ECM_HS
 SG_ DiagFreeRunCntrV : 23|1@0+ (1,0) [0|1] ""  ECM_HS
 SG_ DiagFreeRunCntr : 22|23@0+ (1,0) [0|8388607] "min"  ECM_HS
 SG_ JmpStrtEnbld : 5|1@0+ (1,0) [0|1] ""  HCP_B_HS
 SG_ HybFanSpdRq : 15|8@0+ (0.392157,0) [0|100.000035] "%"  ECM_HS
 SG_ MntnceMdStEngRq : 7|1@0+ (1,0) [0|1] ""  ECM_HS
 SG_ ThrmlRefCompSpdV : 54|1@0+ (1,0) [0|1] ""  ECM_HS
 SG_ ThrmlRefCompSpd : 53|14@0+ (1,0) [0|16383] "rpm"  ECM_HS
 SG_ RdHVCntctrCmdStat : 42|3@0+ (1,0) [0|7] ""  HCP_T_HS,HCP_HS,HCP_B_HS

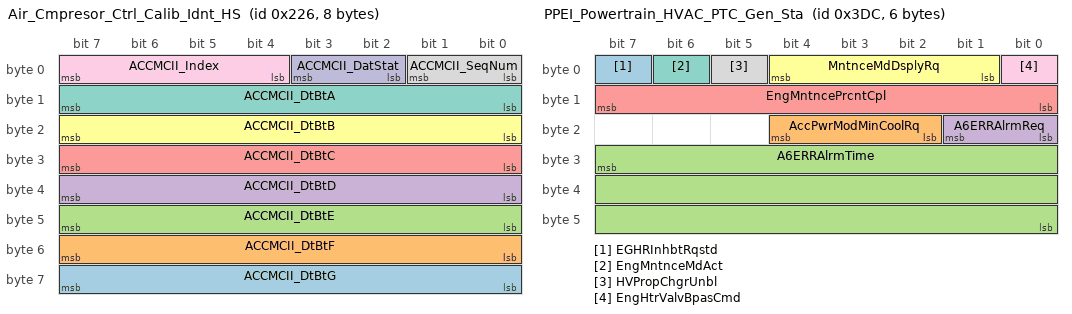
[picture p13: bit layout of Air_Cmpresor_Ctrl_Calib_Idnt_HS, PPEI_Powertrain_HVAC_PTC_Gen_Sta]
BO_ 550 Air_Cmpresor_Ctrl_Calib_Idnt_HS: 8 ACCM_HS
 SG_ ACCMCII_DtBtG : 63|8@0+ (1,0) [0|0] ""  BSM_HS,VICM_HS
 SG_ ACCMCII_DtBtF : 55|8@0+ (1,0) [0|0] ""  BSM_HS,VICM_HS
 SG_ ACCMCII_DtBtE : 47|8@0+ (1,0) [0|0] ""  BSM_HS,VICM_HS
 SG_ ACCMCII_DtBtD : 39|8@0+ (1,0) [0|0] ""  BSM_HS,VICM_HS
 SG_ ACCMCII_DtBtC : 31|8@0+ (1,0) [0|0] ""  BSM_HS,VICM_HS
 SG_ ACCMCII_DtBtB : 23|8@0+ (1,0) [0|0] ""  BSM_HS,VICM_HS
 SG_ ACCMCII_DtBtA : 15|8@0+ (1,0) [0|0] ""  BSM_HS,VICM_HS
 SG_ ACCMCII_SeqNum : 1|2@0+ (1,0) [0|3] ""  BSM_HS,VICM_HS
 SG_ ACCMCII_Index : 7|4@0+ (1,0) [0|15] ""  BSM_HS,VICM_HS
 SG_ ACCMCII_DatStat : 3|2@0+ (1,0) [0|3] ""  BSM_HS,VICM_HS

BO_ 988 PPEI_Powertrain_HVAC_PTC_Gen_Sta: 6 ECM_HS
 SG_ EGHRInhbtRqstd : 7|1@0+ (1,0) [0|1] ""  BSM_HS
 SG_ AccPwrModMinCoolRq : 20|3@0+ (1,0) [0|7] ""  BSM_HS,VICM_HS
 SG_ A6ERRAlrmTime : 31|24@0+ (1,0) [0|16777215] "min"  BSM_HS,VICM_HS
 SG_ A6ERRAlrmReq : 17|2@0+ (1,0) [0|3] ""  BSM_HS,VICM_HS
 SG_ EngMntncePrcntCpl : 15|8@0+ (0.392157,0) [0|100.000035] "%"  VICM_HS
 SG_ MntnceMdDsplyRq : 4|4@0+ (1,0) [0|15] ""  VICM_HS
 SG_ EngMntnceMdAct : 6|1@0+ (1,0) [0|1] ""  VICM_HS
 SG_ HVPropChgrUnbl : 5|1@0+ (1,0) [0|1] ""  HCP_T_HS,HCP_HS,BSM_HS,VICM_HS
 SG_ EngHtrValvBpasCmd : 0|1@0+ (1,0) [0|1] ""  VICM_HS

BO_TX_BU_ 2034 : FCM_HS,PTO_HS;
BO_TX_BU_ 563 : EBCM_OBD_HS,EBCM_HS;
BO_TX_BU_ 1247 : ICCM_OBD_HS,ICCM_HS;
BO_TX_BU_ 800 : CGM_HS,FCM_HS;
BO_TX_BU_ 384 : CGM_HS,EOCM_F_HS,FCM_HS;
BO_TX_BU_ 866 : EBCM_OBD_HS,EBCM_HS;
BO_TX_BU_ 951 : VCM_HS,FICM_HS;
BO_TX_BU_ 1227 : BSM_HS,VICM_HS;
BO_TX_BU_ 1032 : EOCM_F_HS,FCM_HS;
BO_TX_BU_ 1031 : FCM_HS,EOCM_F_HS;
BO_TX_BU_ 1030 : FCM_HS,EOCM_F_HS;
BO_TX_BU_ 479 : HCP_T_HS,HCP_B_HS,BCP_HS,ECM_HS,HCP_HS;
BO_TX_BU_ 211 : HCP_T_HS,HCP_HS,ECM_HS;
BO_TX_BU_ 567 : EBCM_OBD_HS,EBCM_HS;
BO_TX_BU_ 372 : ARS_HS,EBCM_OBD_HS,EBCM_HS;
BO_TX_BU_ 528 : EBCM_OBD_HS,EBCM_HS;
BO_TX_BU_ 753 : EBCM_OBD_HS,EBCM_HS;
BO_TX_BU_ 989 : BSM_HS,VICM_HS;
CM_ SG_ 949 AltFuelEqvlntRatBsOffst "Units = Equivalence Ratio";
CM_ SG_ 544 PTORelBrkPedIO "Power Take Off Release Brake Pedal To Engage Indication On";
BA_DEF_ SG_  "VNSigSLHS_VNReq" ENUM  "No","Yes";
BA_DEF_ SG_  "VNSigSLHSSharedDiagnostic" ENUM  "No","Yes";
BA_DEF_ SG_  "SignalType" STRING ;
BA_DEF_ SG_  "PacketOrder" INT 0 65535;
BA_DEF_ SG_  "SignalLongName" STRING ;
BA_DEF_ SG_  "GenSigStartValue" INT 0 65535;
BA_DEF_ SG_  "VNSigAllNodes" ENUM  "No","Yes";
BA_DEF_ SG_  "GenSigDeltaValue" INT 0 0;
BA_DEF_ SG_  "GenSigSendType" ENUM  "not used","not used","not used","not used","not used","not used","not used","NoSigSendType","not used","not used","OnAnyChange","OnChangeIfActive","OnDelta";
BA_DEF_ SG_  "GenSigSendOnInit" ENUM  "Not Initialized","Application","Handler";
BA_DEF_ BO_  "AppGenMsgCycleTime" INT 0 0;
BA_DEF_ BO_  "TpTxIndex" INT 0 99;
BA_DEF_ BO_  "GenMsgILSupport" ENUM  "No","Yes";
BA_DEF_ BO_  "TpApplType" STRING ;
BA_DEF_ BO_  "Prio" INT 0 7;
BA_DEF_ BO_  "MessageSubnet" ENUM  "LS","MS","HS","CE","PE","HV","FO","S1","HE","LE","HE2";
BA_DEF_ BO_  "DiagState" ENUM  "No","Yes";
BA_DEF_ BO_  "GenMsgStartDelayTime" INT 0 100000;
BA_DEF_ BO_  "GenMsgDelayTime" INT 0 100000;
BA_DEF_ BO_  "GenMsgCycleTime" INT 0 100000;
BA_DEF_ BO_  "GenMsgSendType" ENUM  "cyclicX","spontanX","cyclicIfActiveX","spontanWithDelay","cyclicAndSpontanX","cyclicAndSpontanWithDelay","spontanWithRepitition","cyclicIfActiveAndSpontanWD";
BA_DEF_ BO_  "DiagResponse" ENUM  "No","Yes";
BA_DEF_ BO_  "DiagRequest" ENUM  "No","Yes";
BA_DEF_ BO_  "NmMessage" ENUM  "No","Yes";
BA_DEF_REL_ BU_SG_REL_  "GenSigSuprvRespComment" STRING ;
BA_DEF_REL_ BU_SG_REL_  "GenSigVBitResp" ENUM  "No","Yes";
BA_DEF_REL_ BU_SG_REL_  "GenSigVBitRespComment" STRING ;
BA_DEF_REL_ BU_SG_REL_  "GenSigVDAFailComment" STRING ;
BA_DEF_REL_ BU_SG_REL_  "GenSigVDAFailResp" ENUM  "No","Yes";
BA_DEF_REL_ BU_SG_REL_  "GenSigRxStartValue" STRING ;
BA_DEF_REL_ BU_SG_REL_  "GenSigSuprvRespSubValue" INT 0 65535;
BA_DEF_REL_ BU_SG_REL_  "GenSigSuprvResp" ENUM  "None","Notify App","Substitute Default";
BA_DEF_REL_ BU_SG_REL_  "GenSigTimeoutMsg" HEX -2147483648 268435455;
BA_DEF_REL_ BU_SG_REL_  "GenSigTimeoutTime" INT 0 15000;
BA_DEF_DEF_  "VNSigSLHS_VNReq" "No";
BA_DEF_DEF_  "VNSigSLHSSharedDiagnostic" "No";
BA_DEF_DEF_  "SignalType" "";
BA_DEF_DEF_  "PacketOrder" 0;
BA_DEF_DEF_  "SignalLongName" "";
BA_DEF_DEF_  "GenSigStartValue" 0;
BA_DEF_DEF_  "VNSigAllNodes" "No";
BA_DEF_DEF_  "GenSigDeltaValue" 0;
BA_DEF_DEF_  "GenSigSendType" "NoSigSendType";
BA_DEF_DEF_  "GenSigSendOnInit" "Not Initialized";
BA_DEF_DEF_  "AppGenMsgCycleTime" 0;
BA_DEF_DEF_  "TpTxIndex" 0;
BA_DEF_DEF_  "GenMsgILSupport" "Yes";
BA_DEF_DEF_  "TpApplType" "";
BA_DEF_DEF_  "Prio" 4;
BA_DEF_DEF_  "MessageSubnet" "FO";
BA_DEF_DEF_  "DiagState" "No";
BA_DEF_DEF_  "GenMsgStartDelayTime" 0;
BA_DEF_DEF_  "GenMsgDelayTime" 0;
BA_DEF_DEF_  "GenMsgCycleTime" 0;
BA_DEF_DEF_  "GenMsgSendType" "spontanX";
BA_DEF_DEF_  "DiagResponse" "No";
BA_DEF_DEF_  "DiagRequest" "No";
BA_DEF_DEF_  "NmMessage" "No";
BA_DEF_DEF_REL_ "GenSigSuprvRespComment" "";
BA_DEF_DEF_REL_ "GenSigVBitResp" "No";
BA_DEF_DEF_REL_ "GenSigVBitRespComment" "";
BA_DEF_DEF_REL_ "GenSigVDAFailComment" "";
BA_DEF_DEF_REL_ "GenSigVDAFailResp" "No";
BA_DEF_DEF_REL_ "GenSigRxStartValue" "";
BA_DEF_DEF_REL_ "GenSigSuprvRespSubValue" 0;
BA_DEF_DEF_REL_ "GenSigSuprvResp" "None";
BA_DEF_DEF_REL_ "GenSigTimeoutMsg" 0;
BA_DEF_DEF_REL_ "GenSigTimeoutTime" 0;
BA_ "Prio" BO_ 2034 0;
BA_ "MessageSubnet" BO_ 2034 2;
BA_ "DiagResponse" BO_ 2034 1;
BA_ "Prio" BO_ 2032 0;
BA_ "MessageSubnet" BO_ 2032 2;
BA_ "DiagRequest" BO_ 2032 1;
BA_ "Prio" BO_ 563 0;
BA_ "MessageSubnet" BO_ 563 2;
BA_ "GenMsgCycleTime" BO_ 563 2000;
BA_ "GenMsgSendType" BO_ 563 0;
BA_ "Prio" BO_ 1323 0;
BA_ "MessageSubnet" BO_ 1323 2;
BA_ "GenMsgStartDelayTime" BO_ 1323 50;
BA_ "GenMsgCycleTime" BO_ 1323 1000;
BA_ "GenMsgSendType" BO_ 1323 0;
BA_ "Prio" BO_ 1247 0;
BA_ "MessageSubnet" BO_ 1247 2;
BA_ "GenMsgCycleTime" BO_ 1247 500;
BA_ "GenMsgSendType" BO_ 1247 0;
BA_ "Prio" BO_ 873 0;
BA_ "MessageSubnet" BO_ 873 2;
BA_ "GenMsgCycleTime" BO_ 873 100;
BA_ "GenMsgSendType" BO_ 873 0;
BA_ "Prio" BO_ 306 0;
BA_ "MessageSubnet" BO_ 306 2;
BA_ "GenMsgCycleTime" BO_ 306 100;
BA_ "GenMsgSendType" BO_ 306 0;
BA_ "Prio" BO_ 723 0;
BA_ "MessageSubnet" BO_ 723 2;
BA_ "GenMsgCycleTime" BO_ 723 50;
BA_ "GenMsgSendType" BO_ 723 0;
BA_ "Prio" BO_ 405 0;
BA_ "MessageSubnet" BO_ 405 2;
BA_ "GenMsgCycleTime" BO_ 405 12;
BA_ "GenMsgSendType" BO_ 405 0;
BA_ "Prio" BO_ 419 0;
BA_ "MessageSubnet" BO_ 419 2;
BA_ "GenMsgCycleTime" BO_ 419 25;
BA_ "GenMsgSendType" BO_ 419 0;
BA_ "Prio" BO_ 289 0;
BA_ "MessageSubnet" BO_ 289 2;
BA_ "GenMsgCycleTime" BO_ 289 20;
BA_ "GenMsgSendType" BO_ 289 0;
BA_ "Prio" BO_ 871 0;
BA_ "MessageSubnet" BO_ 871 2;
BA_ "GenMsgCycleTime" BO_ 871 100;
BA_ "GenMsgSendType" BO_ 871 0;
BA_ "Prio" BO_ 800 0;
BA_ "MessageSubnet" BO_ 800 2;
BA_ "GenMsgDelayTime" BO_ 800 10;
BA_ "GenMsgCycleTime" BO_ 800 100;
BA_ "GenMsgSendType" BO_ 800 0;
BA_ "Prio" BO_ 388 0;
BA_ "MessageSubnet" BO_ 388 2;
BA_ "GenMsgCycleTime" BO_ 388 100;
BA_ "GenMsgSendType" BO_ 388 0;
BA_ "Prio" BO_ 384 0;
BA_ "MessageSubnet" BO_ 384 2;
BA_ "GenMsgDelayTime" BO_ 384 10;
BA_ "GenMsgCycleTime" BO_ 384 100;
BA_ "GenMsgSendType" BO_ 384 0;
BA_ "Prio" BO_ 866 0;
BA_ "MessageSubnet" BO_ 866 2;
BA_ "GenMsgCycleTime" BO_ 866 50;
BA_ "GenMsgSendType" BO_ 866 0;
BA_ "Prio" BO_ 951 0;
BA_ "MessageSubnet" BO_ 951 2;
BA_ "GenMsgCycleTime" BO_ 951 100;
BA_ "GenMsgSendType" BO_ 951 0;
BA_ "Prio" BO_ 949 0;
BA_ "MessageSubnet" BO_ 949 2;
BA_ "GenMsgCycleTime" BO_ 949 100;
BA_ "GenMsgSendType" BO_ 949 0;
BA_ "Prio" BO_ 1223 0;
BA_ "MessageSubnet" BO_ 1223 2;
BA_ "GenMsgCycleTime" BO_ 1223 500;
BA_ "GenMsgSendType" BO_ 1223 0;
BA_ "Prio" BO_ 1227 0;
BA_ "MessageSubnet" BO_ 1227 2;
BA_ "GenMsgCycleTime" BO_ 1227 500;
BA_ "GenMsgSendType" BO_ 1227 0;
BA_ "Prio" BO_ 543 0;
BA_ "MessageSubnet" BO_ 543 2;
BA_ "GenMsgStartDelayTime" BO_ 543 110;
BA_ "GenMsgCycleTime" BO_ 543 100;
BA_ "GenMsgSendType" BO_ 543 0;
BA_ "Prio" BO_ 544 0;
BA_ "MessageSubnet" BO_ 544 2;
BA_ "GenMsgCycleTime" BO_ 544 250;
BA_ "GenMsgSendType" BO_ 544 0;
BA_ "Prio" BO_ 901 0;
BA_ "MessageSubnet" BO_ 901 2;
BA_ "GenMsgCycleTime" BO_ 901 100;
BA_ "GenMsgSendType" BO_ 901 0;
BA_ "Prio" BO_ 1032 0;
BA_ "MessageSubnet" BO_ 1032 2;
BA_ "GenMsgCycleTime" BO_ 1032 100;
BA_ "GenMsgSendType" BO_ 1032 0;
BA_ "Prio" BO_ 1031 0;
BA_ "MessageSubnet" BO_ 1031 2;
BA_ "GenMsgCycleTime" BO_ 1031 100;
BA_ "GenMsgSendType" BO_ 1031 0;
BA_ "Prio" BO_ 1030 0;
BA_ "MessageSubnet" BO_ 1030 2;
BA_ "GenMsgCycleTime" BO_ 1030 100;
BA_ "GenMsgSendType" BO_ 1030 0;
BA_ "Prio" BO_ 479 0;
BA_ "MessageSubnet" BO_ 479 2;
BA_ "GenMsgCycleTime" BO_ 479 25;
BA_ "GenMsgSendType" BO_ 479 0;
BA_ "Prio" BO_ 211 0;
BA_ "MessageSubnet" BO_ 211 2;
BA_ "GenMsgCycleTime" BO_ 211 12;
BA_ "GenMsgSendType" BO_ 211 0;
BA_ "Prio" BO_ 1020 0;
BA_ "MessageSubnet" BO_ 1020 2;
BA_ "GenMsgCycleTime" BO_ 1020 250;
BA_ "GenMsgSendType" BO_ 1020 0;
BA_ "Prio" BO_ 567 0;
BA_ "MessageSubnet" BO_ 567 2;
BA_ "GenMsgCycleTime" BO_ 567 250;
BA_ "GenMsgSendType" BO_ 567 0;
BA_ "Prio" BO_ 1219 0;
BA_ "MessageSubnet" BO_ 1219 2;
BA_ "GenMsgCycleTime" BO_ 1219 1000;
BA_ "GenMsgSendType" BO_ 1219 0;
BA_ "Prio" BO_ 372 0;
BA_ "MessageSubnet" BO_ 372 2;
BA_ "GenMsgCycleTime" BO_ 372 100;
BA_ "GenMsgSendType" BO_ 372 0;
BA_ "Prio" BO_ 528 0;
BA_ "MessageSubnet" BO_ 528 2;
BA_ "GenMsgCycleTime" BO_ 528 50;
BA_ "GenMsgSendType" BO_ 528 0;
BA_ "Prio" BO_ 442 0;
BA_ "MessageSubnet" BO_ 442 2;
BA_ "GenMsgCycleTime" BO_ 442 25;
BA_ "GenMsgSendType" BO_ 442 0;
BA_ "Prio" BO_ 753 0;
BA_ "MessageSubnet" BO_ 753 2;
BA_ "GenMsgCycleTime" BO_ 753 100;
BA_ "GenMsgSendType" BO_ 753 0;
BA_ "Prio" BO_ 989 0;
BA_ "MessageSubnet" BO_ 989 2;
BA_ "GenMsgCycleTime" BO_ 989 100;
BA_ "GenMsgSendType" BO_ 989 0;
BA_ "Prio" BO_ 550 0;
BA_ "MessageSubnet" BO_ 550 2;
BA_ "GenMsgCycleTime" BO_ 550 500;
BA_ "GenMsgSendType" BO_ 550 0;
BA_ "Prio" BO_ 988 0;
BA_ "MessageSubnet" BO_ 988 2;
BA_ "GenMsgCycleTime" BO_ 988 100;
BA_ "GenMsgSendType" BO_ 988 0;
BA_ "VNSigSLHSSharedDiagnostic" SG_ 2034 DgnInf 1;
BA_ "SignalType" SG_ 2034 DgnInf "UNM";
BA_ "SignalLongName" SG_ 2034 DgnInf "Diagnostic Information";
BA_ "VNSigAllNodes" SG_ 2034 DgnInf 1;
BA_ "VNSigSLHSSharedDiagnostic" SG_ 2032 DgnInf 1;
BA_ "SignalType" SG_ 2032 DgnInf "UNM";
BA_ "SignalLongName" SG_ 2032 DgnInf "Diagnostic Information";
BA_ "VNSigAllNodes" SG_ 2032 DgnInf 1;
BA_ "SignalType" SG_ 563 SPMCA_SusPrfMd6Avl "BLN";
BA_ "PacketOrder" SG_ 563 SPMCA_SusPrfMd6Avl 6;
BA_ "SignalLongName" SG_ 563 SPMCA_SusPrfMd6Avl "Suspension Performance Mode Customization Available : Suspension Performance Mode 6 Available";
BA_ "VNSigAllNodes" SG_ 563 SPMCA_SusPrfMd6Avl 1;
BA_ "SignalType" SG_ 563 SPMCA_SusPrfMd5Avl "BLN";
BA_ "PacketOrder" SG_ 563 SPMCA_SusPrfMd5Avl 5;
BA_ "SignalLongName" SG_ 563 SPMCA_SusPrfMd5Avl "Suspension Performance Mode Customization Available : Suspension Performance Mode 5 Available";
BA_ "VNSigAllNodes" SG_ 563 SPMCA_SusPrfMd5Avl 1;
BA_ "SignalType" SG_ 563 SPMCA_SusPrfMd4Avl "BLN";
BA_ "PacketOrder" SG_ 563 SPMCA_SusPrfMd4Avl 4;
BA_ "SignalLongName" SG_ 563 SPMCA_SusPrfMd4Avl "Suspension Performance Mode Customization Available : Suspension Performance Mode 4 Available";
BA_ "VNSigAllNodes" SG_ 563 SPMCA_SusPrfMd4Avl 1;
BA_ "SignalType" SG_ 563 SPMCA_SusPrfMd3Avl "BLN";
BA_ "PacketOrder" SG_ 563 SPMCA_SusPrfMd3Avl 3;
BA_ "SignalLongName" SG_ 563 SPMCA_SusPrfMd3Avl "Suspension Performance Mode Customization Available : Suspension Performance Mode 3 Available";
BA_ "VNSigAllNodes" SG_ 563 SPMCA_SusPrfMd3Avl 1;
BA_ "SignalType" SG_ 563 SPMCA_SusPrfMd2Avl "BLN";
BA_ "PacketOrder" SG_ 563 SPMCA_SusPrfMd2Avl 2;
BA_ "SignalLongName" SG_ 563 SPMCA_SusPrfMd2Avl "Suspension Performance Mode Customization Available : Suspension Performance Mode 2 Available";
BA_ "VNSigAllNodes" SG_ 563 SPMCA_SusPrfMd2Avl 1;
BA_ "SignalType" SG_ 563 SPMCA_SusPrfMd1Avl "BLN";
BA_ "PacketOrder" SG_ 563 SPMCA_SusPrfMd1Avl 1;
BA_ "SignalLongName" SG_ 563 SPMCA_SusPrfMd1Avl "Suspension Performance Mode Customization Available : Suspension Performance Mode 1 Available";
BA_ "VNSigAllNodes" SG_ 563 SPMCA_SusPrfMd1Avl 1;
BA_ "SignalType" SG_ 563 SPMCA_StrPrfMd6Avl "BLN";
BA_ "PacketOrder" SG_ 563 SPMCA_StrPrfMd6Avl 6;
BA_ "SignalLongName" SG_ 563 SPMCA_StrPrfMd6Avl "Steering Performance Mode Customization Available : Steering Performance Mode 6 Available";
BA_ "VNSigAllNodes" SG_ 563 SPMCA_StrPrfMd6Avl 1;
BA_ "SignalType" SG_ 563 SPMCA_StrPrfMd5Avl "BLN";
BA_ "PacketOrder" SG_ 563 SPMCA_StrPrfMd5Avl 5;
BA_ "SignalLongName" SG_ 563 SPMCA_StrPrfMd5Avl "Steering Performance Mode Customization Available : Steering Performance Mode 5 Available";
BA_ "VNSigAllNodes" SG_ 563 SPMCA_StrPrfMd5Avl 1;
BA_ "SignalType" SG_ 563 SPMCA_StrPrfMd4Avl "BLN";
BA_ "PacketOrder" SG_ 563 SPMCA_StrPrfMd4Avl 4;
BA_ "SignalLongName" SG_ 563 SPMCA_StrPrfMd4Avl "Steering Performance Mode Customization Available : Steering Performance Mode 4 Available";
BA_ "VNSigAllNodes" SG_ 563 SPMCA_StrPrfMd4Avl 1;
BA_ "SignalType" SG_ 563 SPMCA_StrPrfMd3Avl "BLN";
BA_ "PacketOrder" SG_ 563 SPMCA_StrPrfMd3Avl 3;
BA_ "SignalLongName" SG_ 563 SPMCA_StrPrfMd3Avl "Steering Performance Mode Customization Available : Steering Performance Mode 3 Available";
BA_ "VNSigAllNodes" SG_ 563 SPMCA_StrPrfMd3Avl 1;
BA_ "SignalType" SG_ 563 SPMCA_StrPrfMd2Avl "BLN";
BA_ "PacketOrder" SG_ 563 SPMCA_StrPrfMd2Avl 2;
BA_ "SignalLongName" SG_ 563 SPMCA_StrPrfMd2Avl "Steering Performance Mode Customization Available : Steering Performance Mode 2 Available";
BA_ "VNSigAllNodes" SG_ 563 SPMCA_StrPrfMd2Avl 1;
BA_ "SignalType" SG_ 563 SPMCA_StrPrfMd1Avl "BLN";
BA_ "PacketOrder" SG_ 563 SPMCA_StrPrfMd1Avl 1;
BA_ "SignalLongName" SG_ 563 SPMCA_StrPrfMd1Avl "Steering Performance Mode Customization Available : Steering Performance Mode 1 Available";
BA_ "VNSigAllNodes" SG_ 563 SPMCA_StrPrfMd1Avl 1;
BA_ "SignalType" SG_ 563 SPMCA_SndPrfMd6Avl "BLN";
BA_ "PacketOrder" SG_ 563 SPMCA_SndPrfMd6Avl 6;
BA_ "SignalLongName" SG_ 563 SPMCA_SndPrfMd6Avl "Sound Performance Mode Customization Available : Sound Performance Mode 6 Available";
BA_ "VNSigAllNodes" SG_ 563 SPMCA_SndPrfMd6Avl 1;
BA_ "SignalType" SG_ 563 SPMCA_SndPrfMd5Avl "BLN";
BA_ "PacketOrder" SG_ 563 SPMCA_SndPrfMd5Avl 5;
BA_ "SignalLongName" SG_ 563 SPMCA_SndPrfMd5Avl "Sound Performance Mode Customization Available : Sound Performance Mode 5 Available";
BA_ "VNSigAllNodes" SG_ 563 SPMCA_SndPrfMd5Avl 1;
BA_ "SignalType" SG_ 563 SPMCA_SndPrfMd4Avl "BLN";
BA_ "PacketOrder" SG_ 563 SPMCA_SndPrfMd4Avl 4;
BA_ "SignalLongName" SG_ 563 SPMCA_SndPrfMd4Avl "Sound Performance Mode Customization Available : Sound Performance Mode 4 Available";
BA_ "VNSigAllNodes" SG_ 563 SPMCA_SndPrfMd4Avl 1;
BA_ "SignalType" SG_ 563 SPMCA_SndPrfMd3Avl "BLN";
BA_ "PacketOrder" SG_ 563 SPMCA_SndPrfMd3Avl 3;
BA_ "SignalLongName" SG_ 563 SPMCA_SndPrfMd3Avl "Sound Performance Mode Customization Available : Sound Performance Mode 3 Available";
BA_ "VNSigAllNodes" SG_ 563 SPMCA_SndPrfMd3Avl 1;
BA_ "SignalType" SG_ 563 SPMCA_SndPrfMd2Avl "BLN";
BA_ "PacketOrder" SG_ 563 SPMCA_SndPrfMd2Avl 2;
BA_ "SignalLongName" SG_ 563 SPMCA_SndPrfMd2Avl "Sound Performance Mode Customization Available : Sound Performance Mode 2 Available";
BA_ "VNSigAllNodes" SG_ 563 SPMCA_SndPrfMd2Avl 1;
BA_ "SignalType" SG_ 563 SPMCA_SndPrfMd1Avl "BLN";
BA_ "PacketOrder" SG_ 563 SPMCA_SndPrfMd1Avl 1;
BA_ "SignalLongName" SG_ 563 SPMCA_SndPrfMd1Avl "Sound Performance Mode Customization Available : Sound Performance Mode 1 Available";
BA_ "VNSigAllNodes" SG_ 563 SPMCA_SndPrfMd1Avl 1;
BA_ "SignalType" SG_ 563 DPMCA_DispPrfMd6Avl "BLN";
BA_ "PacketOrder" SG_ 563 DPMCA_DispPrfMd6Avl 6;
BA_ "SignalLongName" SG_ 563 DPMCA_DispPrfMd6Avl "Display Performance Mode Customization Available : Display Performance Mode 6 Available";
BA_ "VNSigAllNodes" SG_ 563 DPMCA_DispPrfMd6Avl 1;
BA_ "SignalType" SG_ 563 DPMCA_DispPrfMd5Avl "BLN";
BA_ "PacketOrder" SG_ 563 DPMCA_DispPrfMd5Avl 5;
BA_ "SignalLongName" SG_ 563 DPMCA_DispPrfMd5Avl "Display Performance Mode Customization Available : Display Performance Mode 5 Available";
BA_ "VNSigAllNodes" SG_ 563 DPMCA_DispPrfMd5Avl 1;
BA_ "SignalType" SG_ 563 DPMCA_DispPrfMd4Avl "BLN";
BA_ "PacketOrder" SG_ 563 DPMCA_DispPrfMd4Avl 4;
BA_ "SignalLongName" SG_ 563 DPMCA_DispPrfMd4Avl "Display Performance Mode Customization Available : Display Performance Mode 4 Available";
BA_ "VNSigAllNodes" SG_ 563 DPMCA_DispPrfMd4Avl 1;
BA_ "SignalType" SG_ 563 DPMCA_DispPrfMd3Avl "BLN";
BA_ "PacketOrder" SG_ 563 DPMCA_DispPrfMd3Avl 3;
BA_ "SignalLongName" SG_ 563 DPMCA_DispPrfMd3Avl "Display Performance Mode Customization Available : Display Performance Mode 3 Available";
BA_ "VNSigAllNodes" SG_ 563 DPMCA_DispPrfMd3Avl 1;
BA_ "SignalType" SG_ 563 DPMCA_DispPrfMd2Avl "BLN";
BA_ "PacketOrder" SG_ 563 DPMCA_DispPrfMd2Avl 2;
BA_ "SignalLongName" SG_ 563 DPMCA_DispPrfMd2Avl "Display Performance Mode Customization Available : Display Performance Mode 2 Available";
BA_ "VNSigAllNodes" SG_ 563 DPMCA_DispPrfMd2Avl 1;
BA_ "SignalType" SG_ 563 DPMCA_DispPrfMd1Avl "BLN";
BA_ "PacketOrder" SG_ 563 DPMCA_DispPrfMd1Avl 1;
BA_ "SignalLongName" SG_ 563 DPMCA_DispPrfMd1Avl "Display Performance Mode Customization Available : Display Performance Mode 1 Available";
BA_ "VNSigAllNodes" SG_ 563 DPMCA_DispPrfMd1Avl 1;
BA_ "SignalType" SG_ 563 DPMCA_DrvlPrfMd6Avl "BLN";
BA_ "PacketOrder" SG_ 563 DPMCA_DrvlPrfMd6Avl 6;
BA_ "SignalLongName" SG_ 563 DPMCA_DrvlPrfMd6Avl "Driveline Performance Mode Customization Available : Driveline Performance Mode 6 Available";
BA_ "VNSigAllNodes" SG_ 563 DPMCA_DrvlPrfMd6Avl 1;
BA_ "SignalType" SG_ 563 DPMCA_DrvlPrfMd5Avl "BLN";
BA_ "PacketOrder" SG_ 563 DPMCA_DrvlPrfMd5Avl 5;
BA_ "SignalLongName" SG_ 563 DPMCA_DrvlPrfMd5Avl "Driveline Performance Mode Customization Available : Driveline Performance Mode 5 Available";
BA_ "VNSigAllNodes" SG_ 563 DPMCA_DrvlPrfMd5Avl 1;
BA_ "SignalType" SG_ 563 DPMCA_DrvlPrfMd4Avl "BLN";
BA_ "PacketOrder" SG_ 563 DPMCA_DrvlPrfMd4Avl 4;
BA_ "SignalLongName" SG_ 563 DPMCA_DrvlPrfMd4Avl "Driveline Performance Mode Customization Available : Driveline Performance Mode 4 Available";
BA_ "VNSigAllNodes" SG_ 563 DPMCA_DrvlPrfMd4Avl 1;
BA_ "SignalType" SG_ 563 DPMCA_DrvlPrfMd3Avl "BLN";
BA_ "PacketOrder" SG_ 563 DPMCA_DrvlPrfMd3Avl 3;
BA_ "SignalLongName" SG_ 563 DPMCA_DrvlPrfMd3Avl "Driveline Performance Mode Customization Available : Driveline Performance Mode 3 Available";
BA_ "VNSigAllNodes" SG_ 563 DPMCA_DrvlPrfMd3Avl 1;
BA_ "SignalType" SG_ 563 DPMCA_DrvlPrfMd2Avl "BLN";
BA_ "PacketOrder" SG_ 563 DPMCA_DrvlPrfMd2Avl 2;
BA_ "SignalLongName" SG_ 563 DPMCA_DrvlPrfMd2Avl "Driveline Performance Mode Customization Available : Driveline Performance Mode 2 Available";
BA_ "VNSigAllNodes" SG_ 563 DPMCA_DrvlPrfMd2Avl 1;
BA_ "SignalType" SG_ 563 DPMCA_DrvlPrfMd1Avl "BLN";
BA_ "PacketOrder" SG_ 563 DPMCA_DrvlPrfMd1Avl 1;
BA_ "SignalLongName" SG_ 563 DPMCA_DrvlPrfMd1Avl "Driveline Performance Mode Customization Available : Driveline Performance Mode 1 Available";
BA_ "VNSigAllNodes" SG_ 563 DPMCA_DrvlPrfMd1Avl 1;
BA_ "SignalType" SG_ 1323 TireLRTmpV "ENM";
BA_ "SignalLongName" SG_ 1323 TireLRTmpV "Tire Left Rear Temperature Validity";
BA_ "VNSigAllNodes" SG_ 1323 TireLRTmpV 1;
BA_ "SignalType" SG_ 1323 TireLRTmp "UNM";
BA_ "SignalLongName" SG_ 1323 TireLRTmp "Tire Left Rear Temperature";
BA_ "VNSigAllNodes" SG_ 1323 TireLRTmp 1;
BA_ "SignalType" SG_ 1323 TireLFTmpV "ENM";
BA_ "SignalLongName" SG_ 1323 TireLFTmpV "Tire Left Front Temperature Validity";
BA_ "VNSigAllNodes" SG_ 1323 TireLFTmpV 1;
BA_ "SignalType" SG_ 1323 TireLFTmp "UNM";
BA_ "SignalLongName" SG_ 1323 TireLFTmp "Tire Left Front Temperature";
BA_ "VNSigAllNodes" SG_ 1323 TireLFTmp 1;
BA_ "SignalType" SG_ 1323 TireRRTmpV "ENM";
BA_ "SignalLongName" SG_ 1323 TireRRTmpV "Tire Right Rear Temperature Validity";
BA_ "VNSigAllNodes" SG_ 1323 TireRRTmpV 1;
BA_ "SignalType" SG_ 1323 TireRRTmp "UNM";
BA_ "SignalLongName" SG_ 1323 TireRRTmp "Tire Right Rear Temperature";
BA_ "VNSigAllNodes" SG_ 1323 TireRRTmp 1;
BA_ "SignalType" SG_ 1323 TireRFTmpV "ENM";
BA_ "SignalLongName" SG_ 1323 TireRFTmpV "Tire Right Front Temperature Validity";
BA_ "VNSigAllNodes" SG_ 1323 TireRFTmpV 1;
BA_ "SignalType" SG_ 1323 TireRFTmp "UNM";
BA_ "SignalLongName" SG_ 1323 TireRFTmp "Tire Right Front Temperature";
BA_ "VNSigAllNodes" SG_ 1323 TireRFTmp 1;
BA_ "SignalType" SG_ 1247 RrPTCoolFanStatV "ENM";
BA_ "SignalLongName" SG_ 1247 RrPTCoolFanStatV "Rear Powertrain Cooling Fan Status Validity";
BA_ "VNSigAllNodes" SG_ 1247 RrPTCoolFanStatV 1;
BA_ "SignalType" SG_ 1247 RrPTCoolFanStat "ENM";
BA_ "SignalLongName" SG_ 1247 RrPTCoolFanStat "Rear Powertrain Cooling Fan Status";
BA_ "VNSigAllNodes" SG_ 1247 RrPTCoolFanStat 1;
BA_ "SignalType" SG_ 1247 RrPTCoolFanSpPctCmd "UNM";
BA_ "SignalLongName" SG_ 1247 RrPTCoolFanSpPctCmd "Rear Powertrain Cooling Fan Speed Percent Commanded";
BA_ "VNSigAllNodes" SG_ 1247 RrPTCoolFanSpPctCmd 1;
BA_ "SignalType" SG_ 873 FrtCmModIntgStat "ENM";
BA_ "SignalLongName" SG_ 873 FrtCmModIntgStat "Front Camera Module Integrity Status";
BA_ "VNSigAllNodes" SG_ 873 FrtCmModIntgStat 1;
BA_ "SignalType" SG_ 873 FrtCmModAsmt "ENM";
BA_ "SignalLongName" SG_ 873 FrtCmModAsmt "Front Camera Module Assessment";
BA_ "VNSigAllNodes" SG_ 873 FrtCmModAsmt 1;
BA_ "SignalType" SG_ 873 ACCMR_RptdChlng "UNM";
BA_ "PacketOrder" SG_ 873 ACCMR_RptdChlng 2;
BA_ "SignalLongName" SG_ 873 ACCMR_RptdChlng "Adaptive Cruise Control Module Response : Repeated Challenge";
BA_ "VNSigAllNodes" SG_ 873 ACCMR_RptdChlng 1;
BA_ "SignalType" SG_ 873 ACCMR_Answr "UNM";
BA_ "PacketOrder" SG_ 873 ACCMR_Answr 1;
BA_ "SignalLongName" SG_ 873 ACCMR_Answr "Adaptive Cruise Control Module Response : Answer";
BA_ "VNSigAllNodes" SG_ 873 ACCMR_Answr 1;
BA_ "SignalType" SG_ 873 AdptCrsCtrlModChlng "UNM";
BA_ "SignalLongName" SG_ 873 AdptCrsCtrlModChlng "Adaptive Cruise Control Module Challenge";
BA_ "VNSigAllNodes" SG_ 873 AdptCrsCtrlModChlng 1;
BA_ "SignalType" SG_ 306 ClntCrcFlwRtEst "UNM";
BA_ "SignalLongName" SG_ 306 ClntCrcFlwRtEst "Coolant Circulation Flow Rate Estimated";
BA_ "VNSigAllNodes" SG_ 306 ClntCrcFlwRtEst 1;
BA_ "SignalType" SG_ 723 PerfTrcEngSpdRqStat "ENM";
BA_ "SignalLongName" SG_ 723 PerfTrcEngSpdRqStat "Performance Traction Engine Speed Request Status";
BA_ "VNSigAllNodes" SG_ 723 PerfTrcEngSpdRqStat 1;
BA_ "SignalType" SG_ 723 PerfTrcEngSpdLmtStat "ENM";
BA_ "SignalLongName" SG_ 723 PerfTrcEngSpdLmtStat "Performance Traction Engine Speed Limiting Status";
BA_ "VNSigAllNodes" SG_ 723 PerfTrcEngSpdLmtStat 1;
BA_ "SignalType" SG_ 723 PerfTrcTrqRqStat "ENM";
BA_ "SignalLongName" SG_ 723 PerfTrcTrqRqStat "Performance Traction Torque Request Status";
BA_ "VNSigAllNodes" SG_ 723 PerfTrcTrqRqStat 1;
BA_ "SignalType" SG_ 723 PerfTrcTrqLmtStat "ENM";
BA_ "SignalLongName" SG_ 723 PerfTrcTrqLmtStat "Performance Traction Torque Limiting Status";
BA_ "VNSigAllNodes" SG_ 723 PerfTrcTrqLmtStat 1;
BA_ "SignalType" SG_ 405 EngDistFuelMdDefltd "BLN";
BA_ "SignalLongName" SG_ 405 EngDistFuelMdDefltd "Engine Distributed Fuel Mode Defaulted";
BA_ "VNSigAllNodes" SG_ 405 EngDistFuelMdDefltd 1;
BA_ "SignalType" SG_ 405 EngInjEnbldD "BLN";
BA_ "SignalLongName" SG_ 405 EngInjEnbldD "Engine Injector Enabled D";
BA_ "VNSigAllNodes" SG_ 405 EngInjEnbldD 1;
BA_ "SignalType" SG_ 405 EngInjEnbldC "BLN";
BA_ "SignalLongName" SG_ 405 EngInjEnbldC "Engine Injector Enabled C";
BA_ "VNSigAllNodes" SG_ 405 EngInjEnbldC 1;
BA_ "SignalType" SG_ 405 EngInjEnbldB "BLN";
BA_ "SignalLongName" SG_ 405 EngInjEnbldB "Engine Injector Enabled B";
BA_ "VNSigAllNodes" SG_ 405 EngInjEnbldB 1;
BA_ "SignalType" SG_ 405 EngInjEnbldA "BLN";
BA_ "SignalLongName" SG_ 405 EngInjEnbldA "Engine Injector Enabled A";
BA_ "VNSigAllNodes" SG_ 405 EngInjEnbldA 1;
BA_ "SignalType" SG_ 405 ThrPosV "ENM";
BA_ "SignalLongName" SG_ 405 ThrPosV "Throttle Position Validity";
BA_ "VNSigAllNodes" SG_ 405 ThrPosV 1;
BA_ "SignalType" SG_ 405 ThrPos "UNM";
BA_ "SignalLongName" SG_ 405 ThrPos "Throttle Position";
BA_ "VNSigAllNodes" SG_ 405 ThrPos 1;
BA_ "SignalType" SG_ 405 MassAirFloV "ENM";
BA_ "SignalLongName" SG_ 405 MassAirFloV "Mass Air Flow Validity";
BA_ "VNSigAllNodes" SG_ 405 MassAirFloV 1;
BA_ "SignalType" SG_ 405 MassAirFlo "UNM";
BA_ "SignalLongName" SG_ 405 MassAirFlo "Mass Air Flow";
BA_ "VNSigAllNodes" SG_ 405 MassAirFlo 1;
BA_ "SignalType" SG_ 405 EngManfldAbsPrsERV "ENM";
BA_ "SignalLongName" SG_ 405 EngManfldAbsPrsERV "Engine Manifold Absolute Pressure Extended Range Validity";
BA_ "VNSigAllNodes" SG_ 405 EngManfldAbsPrsERV 1;
BA_ "SignalType" SG_ 405 EngManfldAbsPrsER "UNM";
BA_ "SignalLongName" SG_ 405 EngManfldAbsPrsER "Engine Manifold Absolute Pressure Extended Range";
BA_ "VNSigAllNodes" SG_ 405 EngManfldAbsPrsER 1;
BA_ "SignalType" SG_ 419 EngRunng "BLN";
BA_ "SignalLongName" SG_ 419 EngRunng "Engine Running";
BA_ "VNSigAllNodes" SG_ 419 EngRunng 1;
BA_ "SignalType" SG_ 289 ARDM_RawData "UNM";
BA_ "PacketOrder" SG_ 289 ARDM_RawData 2;
BA_ "SignalLongName" SG_ 289 ARDM_RawData "ADASIS Raw Data Multiplexed : Raw Data";
BA_ "VNSigAllNodes" SG_ 289 ARDM_RawData 1;
BA_ "SignalType" SG_ 289 ARDM_MsgType "ENM";
BA_ "PacketOrder" SG_ 289 ARDM_MsgType 1;
BA_ "SignalLongName" SG_ 289 ARDM_MsgType "ADASIS Raw Data Multiplexed : Message Type";
BA_ "VNSigAllNodes" SG_ 289 ARDM_MsgType 1;
BA_ "SignalType" SG_ 871 ACCModIntgStat "ENM";
BA_ "SignalLongName" SG_ 871 ACCModIntgStat "Adaptive Cruise Control Module Integrity Status";
BA_ "VNSigAllNodes" SG_ 871 ACCModIntgStat 1;
BA_ "SignalType" SG_ 871 AdptCrsCtrlModAsmt "ENM";
BA_ "SignalLongName" SG_ 871 AdptCrsCtrlModAsmt "Adaptive Cruise Control Module Assessment";
BA_ "VNSigAllNodes" SG_ 871 AdptCrsCtrlModAsmt 1;
BA_ "SignalType" SG_ 871 FCMR_RptdChlng "UNM";
BA_ "PacketOrder" SG_ 871 FCMR_RptdChlng 2;
BA_ "SignalLongName" SG_ 871 FCMR_RptdChlng "Front Camera Module Response : Repeated Challenge";
BA_ "VNSigAllNodes" SG_ 871 FCMR_RptdChlng 1;
BA_ "SignalType" SG_ 871 FCMR_Answr "UNM";
BA_ "PacketOrder" SG_ 871 FCMR_Answr 1;
BA_ "SignalLongName" SG_ 871 FCMR_Answr "Front Camera Module Response : Answer";
BA_ "VNSigAllNodes" SG_ 871 FCMR_Answr 1;
BA_ "SignalType" SG_ 871 FrtCmModChlng "UNM";
BA_ "SignalLongName" SG_ 871 FrtCmModChlng "Front Camera Module Challenge";
BA_ "VNSigAllNodes" SG_ 871 FrtCmModChlng 1;
BA_ "GenSigDeltaValue" SG_ 800 FCACtrlBrkSysCmdPrtVl 1;
BA_ "GenSigSendType" SG_ 800 FCACtrlBrkSysCmdPrtVl 12;
BA_ "SignalType" SG_ 800 FCACtrlBrkSysCmdPrtVl "UNM";
BA_ "SignalLongName" SG_ 800 FCACtrlBrkSysCmdPrtVl "Forward Collision Alert Control Brake System Command Protection Value";
BA_ "VNSigAllNodes" SG_ 800 FCACtrlBrkSysCmdPrtVl 1;
BA_ "GenSigDeltaValue" SG_ 800 FCACBSC_CtrlAcc 1;
BA_ "GenSigSendType" SG_ 800 FCACBSC_CtrlAcc 12;
BA_ "SignalType" SG_ 800 FCACBSC_CtrlAcc "SNM";
BA_ "PacketOrder" SG_ 800 FCACBSC_CtrlAcc 4;
BA_ "SignalLongName" SG_ 800 FCACBSC_CtrlAcc "Forward Collision Alert Control Brake System Command : Control Acceleration";
BA_ "VNSigAllNodes" SG_ 800 FCACBSC_CtrlAcc 1;
BA_ "GenSigSendType" SG_ 800 FCACBSC_AutBrkRpRt 10;
BA_ "SignalType" SG_ 800 FCACBSC_AutBrkRpRt "ENM";
BA_ "PacketOrder" SG_ 800 FCACBSC_AutBrkRpRt 3;
BA_ "SignalLongName" SG_ 800 FCACBSC_AutBrkRpRt "Forward Collision Alert Control Brake System Command : Automatic Braking Ramp Rate";
BA_ "VNSigAllNodes" SG_ 800 FCACBSC_AutBrkRpRt 1;
BA_ "GenSigSendType" SG_ 800 FCACBSC_AutBrkRqTp 10;
BA_ "SignalType" SG_ 800 FCACBSC_AutBrkRqTp "ENM";
BA_ "PacketOrder" SG_ 800 FCACBSC_AutBrkRqTp 2;
BA_ "SignalLongName" SG_ 800 FCACBSC_AutBrkRqTp "Forward Collision Alert Control Brake System Command : Automatic Braking Request Type";
BA_ "VNSigAllNodes" SG_ 800 FCACBSC_AutBrkRqTp 1;
BA_ "GenSigSendType" SG_ 800 FCACBSC_AutBrkRqd 10;
BA_ "SignalType" SG_ 800 FCACBSC_AutBrkRqd "BLN";
BA_ "PacketOrder" SG_ 800 FCACBSC_AutBrkRqd 1;
BA_ "SignalLongName" SG_ 800 FCACBSC_AutBrkRqd "Forward Collision Alert Control Brake System Command : Automatic Braking Requested";
BA_ "VNSigAllNodes" SG_ 800 FCACBSC_AutBrkRqd 1;
BA_ "GenSigDeltaValue" SG_ 800 FCACtrlBrkSysCmdRC 1;
BA_ "GenSigSendType" SG_ 800 FCACtrlBrkSysCmdRC 12;
BA_ "SignalType" SG_ 800 FCACtrlBrkSysCmdRC "UNM";
BA_ "SignalLongName" SG_ 800 FCACtrlBrkSysCmdRC "Forward Collision Alert Control Brake System Command Rolling Count";
BA_ "VNSigAllNodes" SG_ 800 FCACtrlBrkSysCmdRC 1;
BA_ "SignalType" SG_ 388 HndsOffStrWhlDtStV "ENM";
BA_ "SignalLongName" SG_ 388 HndsOffStrWhlDtStV "Hands Off Steering Wheel Detection State Validity";
BA_ "VNSigAllNodes" SG_ 388 HndsOffStrWhlDtStV 1;
BA_ "SignalType" SG_ 388 HndsOffStrWhlDtSt "ENM";
BA_ "SignalLongName" SG_ 388 HndsOffStrWhlDtSt "Hands Off Steering Wheel Detection State";
BA_ "VNSigAllNodes" SG_ 388 HndsOffStrWhlDtSt 1;
BA_ "SignalType" SG_ 388 HndsOffStrWhlDtMd "ENM";
BA_ "SignalLongName" SG_ 388 HndsOffStrWhlDtMd "Hands Off Steering Wheel Detection Mode";
BA_ "VNSigAllNodes" SG_ 388 HndsOffStrWhlDtMd 1;
BA_ "SignalType" SG_ 388 LKATrqOvrlStatChksm "UNM";
BA_ "SignalLongName" SG_ 388 LKATrqOvrlStatChksm "Lane Keeping Assist Torque Overlay Status Checksum";
BA_ "VNSigAllNodes" SG_ 388 LKATrqOvrlStatChksm 1;
BA_ "SignalType" SG_ 388 LKATrqOvrlDltTrqDlvd "SNM";
BA_ "SignalLongName" SG_ 388 LKATrqOvrlDltTrqDlvd "Lane Keeping Assist Torque Overlay Delta Torque Delivered";
BA_ "VNSigAllNodes" SG_ 388 LKATrqOvrlDltTrqDlvd 1;
BA_ "SignalType" SG_ 388 LKATrqOvrlDlvdRC "UNM";
BA_ "SignalLongName" SG_ 388 LKATrqOvrlDlvdRC "Lane Keeping Assist Torque Overlay Delivered Rolling Count";
BA_ "VNSigAllNodes" SG_ 388 LKATrqOvrlDlvdRC 1;
BA_ "SignalType" SG_ 388 LKAElPwrStTtlTqDlvd "SNM";
BA_ "SignalLongName" SG_ 388 LKAElPwrStTtlTqDlvd "Lane Keeping Assist Electrical Power Steering Total Torque Delivered";
BA_ "VNSigAllNodes" SG_ 388 LKAElPwrStTtlTqDlvd 1;
BA_ "SignalType" SG_ 388 LKATrqOvrlTrqDStat "ENM";
BA_ "SignalLongName" SG_ 388 LKATrqOvrlTrqDStat "Lane Keeping Assist Torque Overlay Torque Delivered Status";
BA_ "VNSigAllNodes" SG_ 388 LKATrqOvrlTrqDStat 1;
BA_ "SignalType" SG_ 388 LKADrvAppldTrqV "ENM";
BA_ "SignalLongName" SG_ 388 LKADrvAppldTrqV "Lane Keeping Assist Driver Applied Torque Validity";
BA_ "VNSigAllNodes" SG_ 388 LKADrvAppldTrqV 1;
BA_ "SignalType" SG_ 388 LKADrvAppldTrq "SNM";
BA_ "SignalLongName" SG_ 388 LKADrvAppldTrq "Lane Keeping Assist Driver Applied Torque";
BA_ "VNSigAllNodes" SG_ 388 LKADrvAppldTrq 1;
BA_ "GenSigDeltaValue" SG_ 384 LKATqOvrDltCmdPrtVl 1;
BA_ "GenSigSendType" SG_ 384 LKATqOvrDltCmdPrtVl 12;
BA_ "SignalType" SG_ 384 LKATqOvrDltCmdPrtVl "UNM";
BA_ "SignalLongName" SG_ 384 LKATqOvrDltCmdPrtVl "Lane Keeping Assist Torque Overlay Delta Command Protection Value";
BA_ "VNSigAllNodes" SG_ 384 LKATqOvrDltCmdPrtVl 1;
BA_ "GenSigDeltaValue" SG_ 384 LKATqOvrDltCmdRC 1;
BA_ "GenSigSendType" SG_ 384 LKATqOvrDltCmdRC 12;
BA_ "SignalType" SG_ 384 LKATqOvrDltCmdRC "UNM";
BA_ "SignalLongName" SG_ 384 LKATqOvrDltCmdRC "Lane Keeping Assist Torque Overlay Delta Command Rolling Count";
BA_ "VNSigAllNodes" SG_ 384 LKATqOvrDltCmdRC 1;
BA_ "GenSigDeltaValue" SG_ 384 LKATODC_TrqVl 1;
BA_ "GenSigSendType" SG_ 384 LKATODC_TrqVl 12;
BA_ "SignalType" SG_ 384 LKATODC_TrqVl "SNM";
BA_ "PacketOrder" SG_ 384 LKATODC_TrqVl 2;
BA_ "SignalLongName" SG_ 384 LKATODC_TrqVl "Lane Keeping Assist Torque Overlay Delta Command : Torque Value";
BA_ "VNSigAllNodes" SG_ 384 LKATODC_TrqVl 1;
BA_ "GenSigSendType" SG_ 384 LKATODC_TrqRqAct 10;
BA_ "SignalType" SG_ 384 LKATODC_TrqRqAct "BLN";
BA_ "PacketOrder" SG_ 384 LKATODC_TrqRqAct 1;
BA_ "SignalLongName" SG_ 384 LKATODC_TrqRqAct "Lane Keeping Assist Torque Overlay Delta Command : Torque Request Active";
BA_ "VNSigAllNodes" SG_ 384 LKATODC_TrqRqAct 1;
BA_ "SignalType" SG_ 866 ColPrSysHzrdLghtsReq "ENM";
BA_ "SignalLongName" SG_ 866 ColPrSysHzrdLghtsReq "Collision Preparation System Hazard Lights Request";
BA_ "VNSigAllNodes" SG_ 866 ColPrSysHzrdLghtsReq 1;
BA_ "SignalType" SG_ 866 ColPrSysWndwsReq "ENM";
BA_ "SignalLongName" SG_ 866 ColPrSysWndwsReq "Collision Preparation System Windows Request";
BA_ "VNSigAllNodes" SG_ 866 ColPrSysWndwsReq 1;
BA_ "SignalType" SG_ 866 ColPrSysDrsReq "ENM";
BA_ "SignalLongName" SG_ 866 ColPrSysDrsReq "Collision Preparation System Doors Request";
BA_ "VNSigAllNodes" SG_ 866 ColPrSysDrsReq 1;
BA_ "SignalType" SG_ 866 ColPrSysSnrfReq "ENM";
BA_ "SignalLongName" SG_ 866 ColPrSysSnrfReq "Collision Preparation System Sunroof Request";
BA_ "VNSigAllNodes" SG_ 866 ColPrSysSnrfReq 1;
BA_ "SignalType" SG_ 866 CPSInfotmntMtReq "ENM";
BA_ "SignalLongName" SG_ 866 CPSInfotmntMtReq "Collision Preparation System Infotainment Mute Request";
BA_ "VNSigAllNodes" SG_ 866 CPSInfotmntMtReq 1;
BA_ "SignalType" SG_ 866 StBltTgtSetAvl "BLN";
BA_ "SignalLongName" SG_ 866 StBltTgtSetAvl "Seat Belt Tightening Settings Available";
BA_ "VNSigAllNodes" SG_ 866 StBltTgtSetAvl 1;
BA_ "SignalType" SG_ 866 StBltTgtCrtSetVal "ENM";
BA_ "SignalLongName" SG_ 866 StBltTgtCrtSetVal "Seat Belt Tightening Current Setting Value";
BA_ "VNSigAllNodes" SG_ 866 StBltTgtCrtSetVal 1;
BA_ "SignalType" SG_ 866 MotStBltUnblIO "BLN";
BA_ "SignalLongName" SG_ 866 MotStBltUnblIO "Motorized Seat Belt Unavailable Indication On";
BA_ "VNSigAllNodes" SG_ 866 MotStBltUnblIO 1;
BA_ "SignalType" SG_ 866 MotStBltFldIO "BLN";
BA_ "SignalLongName" SG_ 866 MotStBltFldIO "Motorized Seat Belt Failed Indication On";
BA_ "VNSigAllNodes" SG_ 866 MotStBltFldIO 1;
BA_ "SignalType" SG_ 866 RegenBrkAxTrqAch "UNM";
BA_ "SignalLongName" SG_ 866 RegenBrkAxTrqAch "Regenerative Braking Axle Torque Achieved";
BA_ "VNSigAllNodes" SG_ 866 RegenBrkAxTrqAch 1;
BA_ "SignalType" SG_ 951 AltFuelLvlPrcnt "UNM";
BA_ "SignalLongName" SG_ 951 AltFuelLvlPrcnt "Alternative Fuel Level Percent";
BA_ "VNSigAllNodes" SG_ 951 AltFuelLvlPrcnt 1;
BA_ "SignalType" SG_ 951 FuelInjCntrlModInjFltAct "BLN";
BA_ "SignalLongName" SG_ 951 FuelInjCntrlModInjFltAct "Fuel Injector Control Module Injection Fault Active";
BA_ "VNSigAllNodes" SG_ 951 FuelInjCntrlModInjFltAct 1;
BA_ "SignalType" SG_ 951 AFRP_RailPrs "UNM";
BA_ "PacketOrder" SG_ 951 AFRP_RailPrs 2;
BA_ "SignalLongName" SG_ 951 AFRP_RailPrs "Alternative Fuel Rail Pressure : Rail Pressure";
BA_ "VNSigAllNodes" SG_ 951 AFRP_RailPrs 1;
BA_ "SignalType" SG_ 951 AFRP_SnsTyp "ENM";
BA_ "PacketOrder" SG_ 951 AFRP_SnsTyp 1;
BA_ "SignalLongName" SG_ 951 AFRP_SnsTyp "Alternative Fuel Rail Pressure : Sensor Type";
BA_ "VNSigAllNodes" SG_ 951 AFRP_SnsTyp 1;
BA_ "SignalType" SG_ 951 FICMDS3_DTCStatus "ENM";
BA_ "PacketOrder" SG_ 951 FICMDS3_DTCStatus 2;
BA_ "SignalLongName" SG_ 951 FICMDS3_DTCStatus "Fuel Injector Control Module Diagnostic Status 3 : Diagnostic Trouble Code Status";
BA_ "VNSigAllNodes" SG_ 951 FICMDS3_DTCStatus 1;
BA_ "SignalType" SG_ 951 FICMDS3_DTCIndx "UNM";
BA_ "PacketOrder" SG_ 951 FICMDS3_DTCIndx 1;
BA_ "SignalLongName" SG_ 951 FICMDS3_DTCIndx "Fuel Injector Control Module Diagnostic Status 3 : Diagnostic Trouble Code Index";
BA_ "VNSigAllNodes" SG_ 951 FICMDS3_DTCIndx 1;
BA_ "SignalType" SG_ 951 FICMDS2_DTCStatus "ENM";
BA_ "PacketOrder" SG_ 951 FICMDS2_DTCStatus 2;
BA_ "SignalLongName" SG_ 951 FICMDS2_DTCStatus "Fuel Injector Control Module Diagnostic Status 2 : Diagnostic Trouble Code Status";
BA_ "VNSigAllNodes" SG_ 951 FICMDS2_DTCStatus 1;
BA_ "SignalType" SG_ 951 FICMDS2_DTCIndx "UNM";
BA_ "PacketOrder" SG_ 951 FICMDS2_DTCIndx 1;
BA_ "SignalLongName" SG_ 951 FICMDS2_DTCIndx "Fuel Injector Control Module Diagnostic Status 2 : Diagnostic Trouble Code Index";
BA_ "VNSigAllNodes" SG_ 951 FICMDS2_DTCIndx 1;
BA_ "SignalType" SG_ 951 FICMDS1_DTCStatus "ENM";
BA_ "PacketOrder" SG_ 951 FICMDS1_DTCStatus 2;
BA_ "SignalLongName" SG_ 951 FICMDS1_DTCStatus "Fuel Injector Control Module Diagnostic Status 1 : Diagnostic Trouble Code Status";
BA_ "VNSigAllNodes" SG_ 951 FICMDS1_DTCStatus 1;
BA_ "SignalType" SG_ 951 FICMDS1_DTCIndx "UNM";
BA_ "PacketOrder" SG_ 951 FICMDS1_DTCIndx 1;
BA_ "SignalLongName" SG_ 951 FICMDS1_DTCIndx "Fuel Injector Control Module Diagnostic Status 1 : Diagnostic Trouble Code Index";
BA_ "VNSigAllNodes" SG_ 951 FICMDS1_DTCIndx 1;
BA_ "SignalType" SG_ 949 AltFuelRFuelTrmLmtOff "SNM";
BA_ "SignalLongName" SG_ 949 AltFuelRFuelTrmLmtOff "Alternative Fuel Rich Fuel Trim Limit Offset";
BA_ "VNSigAllNodes" SG_ 949 AltFuelRFuelTrmLmtOff 1;
BA_ "SignalType" SG_ 949 AltFuelLnFuelTrmLmtOff "SNM";
BA_ "SignalLongName" SG_ 949 AltFuelLnFuelTrmLmtOff "Alternative Fuel Lean Fuel Trim Limit Offset";
BA_ "VNSigAllNodes" SG_ 949 AltFuelLnFuelTrmLmtOff 1;
BA_ "SignalType" SG_ 949 AltFuelInjMinPlsOffst "SNM";
BA_ "SignalLongName" SG_ 949 AltFuelInjMinPlsOffst "Alternative Fuel Injector Min Pulse Offset";
BA_ "VNSigAllNodes" SG_ 949 AltFuelInjMinPlsOffst 1;
BA_ "SignalType" SG_ 949 AltFuelInjOpnOffst "SNM";
BA_ "SignalLongName" SG_ 949 AltFuelInjOpnOffst "Alternative Fuel Injector Opening Offset";
BA_ "VNSigAllNodes" SG_ 949 AltFuelInjOpnOffst 1;
BA_ "SignalType" SG_ 949 AltFuelInjFlwOffst "SNM";
BA_ "SignalLongName" SG_ 949 AltFuelInjFlwOffst "Alternative Fuel Injector Flow Offset";
BA_ "VNSigAllNodes" SG_ 949 AltFuelInjFlwOffst 1;
BA_ "SignalType" SG_ 949 AltFuelEqvlntRatBsOffst "SNM";
BA_ "SignalLongName" SG_ 949 AltFuelEqvlntRatBsOffst "Alternative Fuel Equivalence Ratio Bias Offset";
BA_ "VNSigAllNodes" SG_ 949 AltFuelEqvlntRatBsOffst 1;
BA_ "SignalType" SG_ 949 AltFuelPst02BsOffst "SNM";
BA_ "SignalLongName" SG_ 949 AltFuelPst02BsOffst "Alternative Fuel Post O2 Bias Offset";
BA_ "VNSigAllNodes" SG_ 949 AltFuelPst02BsOffst 1;
BA_ "SignalType" SG_ 1223 EngSnPwrECoolLpTmpV "ENM";
BA_ "SignalLongName" SG_ 1223 EngSnPwrECoolLpTmpV "Engine Sensed Power Electronics Cooling Loop Temperature Validity";
BA_ "VNSigAllNodes" SG_ 1223 EngSnPwrECoolLpTmpV 1;
BA_ "SignalType" SG_ 1223 EngSnPwrECoolLpTmp "UNM";
BA_ "SignalLongName" SG_ 1223 EngSnPwrECoolLpTmp "Engine Sensed Power Electronics Cooling Loop Temperature";
BA_ "VNSigAllNodes" SG_ 1223 EngSnPwrECoolLpTmp 1;
BA_ "SignalType" SG_ 1223 PropSysOffTmeV "ENM";
BA_ "SignalLongName" SG_ 1223 PropSysOffTmeV "Propulsion System Off Time Validity";
BA_ "VNSigAllNodes" SG_ 1223 PropSysOffTmeV 1;
BA_ "SignalType" SG_ 1223 PropSysOffTmeM "ENM";
BA_ "SignalLongName" SG_ 1223 PropSysOffTmeM "Propulsion System Off Time Mask";
BA_ "VNSigAllNodes" SG_ 1223 PropSysOffTmeM 1;
BA_ "SignalType" SG_ 1223 PropSysOffTme "UNM";
BA_ "SignalLongName" SG_ 1223 PropSysOffTme "Propulsion System Off Time";
BA_ "VNSigAllNodes" SG_ 1223 PropSysOffTme 1;
BA_ "SignalType" SG_ 1227 BattThrmlCondOffTmeV "ENM";
BA_ "SignalLongName" SG_ 1227 BattThrmlCondOffTmeV "Battery Thermal Conditioning Off Time Validity";
BA_ "VNSigAllNodes" SG_ 1227 BattThrmlCondOffTmeV 1;
BA_ "SignalType" SG_ 1227 BattThrmlCondOffTmeM "ENM";
BA_ "SignalLongName" SG_ 1227 BattThrmlCondOffTmeM "Battery Thermal Conditioning Off Time Mask";
BA_ "VNSigAllNodes" SG_ 1227 BattThrmlCondOffTmeM 1;
BA_ "SignalType" SG_ 1227 BattThrmlCondOffTme "UNM";
BA_ "SignalLongName" SG_ 1227 BattThrmlCondOffTme "Battery Thermal Conditioning Off Time";
BA_ "VNSigAllNodes" SG_ 1227 BattThrmlCondOffTme 1;
BA_ "SignalType" SG_ 1227 OffBrdChrgOffTmeV "ENM";
BA_ "SignalLongName" SG_ 1227 OffBrdChrgOffTmeV "Off Board Charging Off Time Validity";
BA_ "VNSigAllNodes" SG_ 1227 OffBrdChrgOffTmeV 1;
BA_ "SignalType" SG_ 1227 OffBrdChrgOffTmeM "ENM";
BA_ "SignalLongName" SG_ 1227 OffBrdChrgOffTmeM "Off Board Charging Off Time Mask";
BA_ "VNSigAllNodes" SG_ 1227 OffBrdChrgOffTmeM 1;
BA_ "SignalType" SG_ 1227 OffBrdChrgOffTme "UNM";
BA_ "SignalLongName" SG_ 1227 OffBrdChrgOffTme "Off Board Charging Off Time";
BA_ "VNSigAllNodes" SG_ 1227 OffBrdChrgOffTme 1;
BA_ "SignalType" SG_ 543 PTOTpStpSpdCsStReq "ENM";
BA_ "SignalLongName" SG_ 543 PTOTpStpSpdCsStReq "Power Take Off Tap Step Speed Customization Setting Request";
BA_ "VNSigAllNodes" SG_ 543 PTOTpStpSpdCsStReq 1;
BA_ "SignalType" SG_ 543 PTOStdbySpdCsStReq "ENM";
BA_ "SignalLongName" SG_ 543 PTOStdbySpdCsStReq "Power Take Off Standby Speed Customization Setting Request";
BA_ "VNSigAllNodes" SG_ 543 PTOStdbySpdCsStReq 1;
BA_ "SignalType" SG_ 543 PTOEngRnTmrCsStRq "ENM";
BA_ "SignalLongName" SG_ 543 PTOEngRnTmrCsStRq "Power Take Off Engine Run Timer Customization Setting Request";
BA_ "VNSigAllNodes" SG_ 543 PTOEngRnTmrCsStRq 1;
BA_ "SignalType" SG_ 543 PTOSet2SpdCsStReq "ENM";
BA_ "SignalLongName" SG_ 543 PTOSet2SpdCsStReq "Power Take Off Set 2 Speed Customization Setting Request";
BA_ "VNSigAllNodes" SG_ 543 PTOSet2SpdCsStReq 1;
BA_ "SignalType" SG_ 543 PTOSet1SpdCsStReq "ENM";
BA_ "SignalLongName" SG_ 543 PTOSet1SpdCsStReq "Power Take Off Set 1 Speed Customization Setting Request";
BA_ "VNSigAllNodes" SG_ 543 PTOSet1SpdCsStReq 1;
BA_ "SignalType" SG_ 544 PTOMobModTrnsInGrIO "BLN";
BA_ "SignalLongName" SG_ 544 PTOMobModTrnsInGrIO "Power Take Off Mobile Mode Transmission In Gear Indication On";
BA_ "VNSigAllNodes" SG_ 544 PTOMobModTrnsInGrIO 1;
BA_ "SignalType" SG_ 544 PTOManTransInGrIO "BLN";
BA_ "SignalLongName" SG_ 544 PTOManTransInGrIO "Power Take Off Manual Transmission In Gear Indication On";
BA_ "VNSigAllNodes" SG_ 544 PTOManTransInGrIO 1;
BA_ "SignalType" SG_ 544 PTOServIndOn "BLN";
BA_ "SignalLongName" SG_ 544 PTOServIndOn "Power Take Off Service Indication On";
BA_ "VNSigAllNodes" SG_ 544 PTOServIndOn 1;
BA_ "SignalType" SG_ 544 PTOEngUpnBrkRelIO "BLN";
BA_ "SignalLongName" SG_ 544 PTOEngUpnBrkRelIO "Power Take Off Engage Upon Brake Release Indication On";
BA_ "VNSigAllNodes" SG_ 544 PTOEngUpnBrkRelIO 1;
BA_ "SignalType" SG_ 544 PTOAccelUpnBrkRelIO "BLN";
BA_ "SignalLongName" SG_ 544 PTOAccelUpnBrkRelIO "Power Take Off Acceleration Upon Brake Release Indication On";
BA_ "VNSigAllNodes" SG_ 544 PTOAccelUpnBrkRelIO 1;
BA_ "SignalType" SG_ 544 PTOAudExtAlertReq "BLN";
BA_ "SignalLongName" SG_ 544 PTOAudExtAlertReq "Power Take Off Audible External Alert Request";
BA_ "VNSigAllNodes" SG_ 544 PTOAudExtAlertReq 1;
BA_ "SignalType" SG_ 544 PTOTransInGearIO "BLN";
BA_ "SignalLongName" SG_ 544 PTOTransInGearIO "Power Take Off Transmission In Gear Indication On";
BA_ "VNSigAllNodes" SG_ 544 PTOTransInGearIO 1;
BA_ "SignalType" SG_ 544 PTOTpStpSpdCsStAvl "BLN";
BA_ "SignalLongName" SG_ 544 PTOTpStpSpdCsStAvl "Power Take Off Tap Step Speed Customization Setting Available";
BA_ "VNSigAllNodes" SG_ 544 PTOTpStpSpdCsStAvl 1;
BA_ "SignalType" SG_ 544 PTOTpStSpdCsCrStVal "ENM";
BA_ "SignalLongName" SG_ 544 PTOTpStSpdCsCrStVal "Power Take Off Tap Step Speed Customization Current Setting Value";
BA_ "VNSigAllNodes" SG_ 544 PTOTpStSpdCsCrStVal 1;
BA_ "SignalType" SG_ 544 PTOStdbySpdCsStAvl "BLN";
BA_ "SignalLongName" SG_ 544 PTOStdbySpdCsStAvl "Power Take Off Standby Speed Customization Setting Available";
BA_ "VNSigAllNodes" SG_ 544 PTOStdbySpdCsStAvl 1;
BA_ "SignalType" SG_ 544 PTOStdbSpdCsCrStVal "ENM";
BA_ "SignalLongName" SG_ 544 PTOStdbSpdCsCrStVal "Power Take Off Standby Speed Customization Current Setting Value";
BA_ "VNSigAllNodes" SG_ 544 PTOStdbSpdCsCrStVal 1;
BA_ "SignalType" SG_ 544 PTOSetPrkBrkIO "BLN";
BA_ "SignalLongName" SG_ 544 PTOSetPrkBrkIO "Power Take Off Set Park Brake Indication On";
BA_ "VNSigAllNodes" SG_ 544 PTOSetPrkBrkIO 1;
BA_ "SignalType" SG_ 544 PTOSet2SpdCsStAvl "BLN";
BA_ "SignalLongName" SG_ 544 PTOSet2SpdCsStAvl "Power Take Off Set 2 Speed Customization Setting Available";
BA_ "VNSigAllNodes" SG_ 544 PTOSet2SpdCsStAvl 1;
BA_ "SignalType" SG_ 544 PTOSet2SpdCsCrStVal "ENM";
BA_ "SignalLongName" SG_ 544 PTOSet2SpdCsCrStVal "Power Take Off Set 2 Speed Customization Current Setting Value";
BA_ "VNSigAllNodes" SG_ 544 PTOSet2SpdCsCrStVal 1;
BA_ "SignalType" SG_ 544 PTOSet1SpdCsStAvl "BLN";
BA_ "SignalLongName" SG_ 544 PTOSet1SpdCsStAvl "Power Take Off Set 1 Speed Customization Setting Available";
BA_ "VNSigAllNodes" SG_ 544 PTOSet1SpdCsStAvl 1;
BA_ "SignalType" SG_ 544 PTOSet1SpdCsCrStVal "ENM";
BA_ "SignalLongName" SG_ 544 PTOSet1SpdCsCrStVal "Power Take Off Set 1 Speed Customization Current Setting Value";
BA_ "VNSigAllNodes" SG_ 544 PTOSet1SpdCsCrStVal 1;
BA_ "SignalType" SG_ 544 PTORelCltPedIO "BLN";
BA_ "SignalLongName" SG_ 544 PTORelCltPedIO "Power Take Off Release Clutch Pedal Indication On";
BA_ "VNSigAllNodes" SG_ 544 PTORelCltPedIO 1;
BA_ "SignalType" SG_ 544 PTORelBrkPedIO "BLN";
BA_ "SignalLongName" SG_ 544 PTORelBrkPedIO "Power Take Off Release Brake Pedal Indication On";
BA_ "VNSigAllNodes" SG_ 544 PTORelBrkPedIO 1;
BA_ "SignalType" SG_ 544 PTORelAccPedIO "BLN";
BA_ "SignalLongName" SG_ 544 PTORelAccPedIO "Power Take Off Release Accelerator Pedal Indication On";
BA_ "VNSigAllNodes" SG_ 544 PTORelAccPedIO 1;
BA_ "SignalType" SG_ 544 PTORedEngSpdIO "BLN";
BA_ "SignalLongName" SG_ 544 PTORedEngSpdIO "Power Take Off Reduce Engine Speed Indication On";
BA_ "VNSigAllNodes" SG_ 544 PTORedEngSpdIO 1;
BA_ "SignalType" SG_ 544 PTOPrsRelCltPedIO "BLN";
BA_ "SignalLongName" SG_ 544 PTOPrsRelCltPedIO "Power Take Off Press and Release Clutch Pedal Indication On";
BA_ "VNSigAllNodes" SG_ 544 PTOPrsRelCltPedIO 1;
BA_ "SignalType" SG_ 544 PTOPrsRelBrkPedIO "BLN";
BA_ "SignalLongName" SG_ 544 PTOPrsRelBrkPedIO "Power Take Off Press and Release Brake Pedal Indication On";
BA_ "VNSigAllNodes" SG_ 544 PTOPrsRelBrkPedIO 1;
BA_ "SignalType" SG_ 544 PTOEngRnTmrCsStAvl "BLN";
BA_ "SignalLongName" SG_ 544 PTOEngRnTmrCsStAvl "Power Take Off Engine Run Timer Customization Setting Available";
BA_ "VNSigAllNodes" SG_ 544 PTOEngRnTmrCsStAvl 1;
BA_ "SignalType" SG_ 544 PTOEnRnTmCsCrStVal "ENM";
BA_ "SignalLongName" SG_ 544 PTOEnRnTmCsCrStVal "Power Take Off Engine Run Timer Customization Current Setting Value";
BA_ "VNSigAllNodes" SG_ 544 PTOEnRnTmCsCrStVal 1;
BA_ "SignalType" SG_ 544 PTOEngmntStatInd "ENM";
BA_ "SignalLongName" SG_ 544 PTOEngmntStatInd "Power Take Off Engagement Status Indication";
BA_ "VNSigAllNodes" SG_ 544 PTOEngmntStatInd 1;
BA_ "SignalType" SG_ 544 PTODisengCrsCntlIO "BLN";
BA_ "SignalLongName" SG_ 544 PTODisengCrsCntlIO "Power Take Off Disengage Cruise Control Indication On";
BA_ "VNSigAllNodes" SG_ 544 PTODisengCrsCntlIO 1;
BA_ "SignalType" SG_ 901 TrnsMtrBCoolFlwEst "UNM";
BA_ "SignalLongName" SG_ 901 TrnsMtrBCoolFlwEst "Transmission Motor B Cooling Flow Estimated";
BA_ "VNSigAllNodes" SG_ 901 TrnsMtrBCoolFlwEst 1;
BA_ "SignalType" SG_ 901 TrnsMtrACoolFlwEst "UNM";
BA_ "SignalLongName" SG_ 901 TrnsMtrACoolFlwEst "Transmission Motor A Cooling Flow Estimated";
BA_ "VNSigAllNodes" SG_ 901 TrnsMtrACoolFlwEst 1;
BA_ "SignalType" SG_ 901 TrnsLubeFlwEst "UNM";
BA_ "SignalLongName" SG_ 901 TrnsLubeFlwEst "Transmission Lube Flow Estimated";
BA_ "VNSigAllNodes" SG_ 901 TrnsLubeFlwEst 1;
BA_ "SignalType" SG_ 1032 RdTyp "ENM";
BA_ "SignalLongName" SG_ 1032 RdTyp "Road Type";
BA_ "VNSigAllNodes" SG_ 1032 RdTyp 1;
BA_ "SignalType" SG_ 1032 FwdCamSysOpStat "ENM";
BA_ "SignalLongName" SG_ 1032 FwdCamSysOpStat "Forward Camera System Operating Status";
BA_ "VNSigAllNodes" SG_ 1032 FwdCamSysOpStat 1;
BA_ "SignalType" SG_ 1032 EnvIllum "ENM";
BA_ "SignalLongName" SG_ 1032 EnvIllum "Environment Illumination";
BA_ "VNSigAllNodes" SG_ 1032 EnvIllum 1;
BA_ "SignalType" SG_ 1032 AutoHgBmSts "ENM";
BA_ "SignalLongName" SG_ 1032 AutoHgBmSts "Automatic High Beam Status";
BA_ "VNSigAllNodes" SG_ 1032 AutoHgBmSts 1;
BA_ "SignalType" SG_ 1031 GFHBFwVsnWidthTrk8 "UNM";
BA_ "SignalLongName" SG_ 1031 GFHBFwVsnWidthTrk8 "GFHB Forward Vision Width Track 8";
BA_ "VNSigAllNodes" SG_ 1031 GFHBFwVsnWidthTrk8 1;
BA_ "SignalType" SG_ 1031 GFHBFwVsnVertPosTrk8 "UNM";
BA_ "SignalLongName" SG_ 1031 GFHBFwVsnVertPosTrk8 "GFHB Forward Vision Vertical Position Track 8";
BA_ "VNSigAllNodes" SG_ 1031 GFHBFwVsnVertPosTrk8 1;
BA_ "SignalType" SG_ 1031 GFHBFwVsnRelLaneTrk8 "ENM";
BA_ "SignalLongName" SG_ 1031 GFHBFwVsnRelLaneTrk8 "GFHB Forward Vision Relative Lane Track 8";
BA_ "VNSigAllNodes" SG_ 1031 GFHBFwVsnRelLaneTrk8 1;
BA_ "SignalType" SG_ 1031 GFHBFwVsnAzmthRtTrk8 "SNM";
BA_ "SignalLongName" SG_ 1031 GFHBFwVsnAzmthRtTrk8 "GFHB Forward Vision Azimuth Rate Track 8";
BA_ "VNSigAllNodes" SG_ 1031 GFHBFwVsnAzmthRtTrk8 1;
BA_ "SignalType" SG_ 1031 GFHBFwVsnCnfdncTrk8 "ENM";
BA_ "SignalLongName" SG_ 1031 GFHBFwVsnCnfdncTrk8 "GFHB Forward Vision Confidence Track 8";
BA_ "VNSigAllNodes" SG_ 1031 GFHBFwVsnCnfdncTrk8 1;
BA_ "SignalType" SG_ 1031 GFHBFwVsnRngTrkRev8 "UNM";
BA_ "SignalLongName" SG_ 1031 GFHBFwVsnRngTrkRev8 "GFHB Forward Vision Range Track Revised 8";
BA_ "VNSigAllNodes" SG_ 1031 GFHBFwVsnRngTrkRev8 1;
BA_ "SignalType" SG_ 1031 GFHBFwVsnAzmthTrkRev8 "SNM";
BA_ "SignalLongName" SG_ 1031 GFHBFwVsnAzmthTrkRev8 "GFHB Forward Vision Azimuth Track Revised 8";
BA_ "VNSigAllNodes" SG_ 1031 GFHBFwVsnAzmthTrkRev8 1;
BA_ "SignalType" SG_ 1031 GFHBFVsnObjTypTrkRev8 "ENM";
BA_ "SignalLongName" SG_ 1031 GFHBFVsnObjTypTrkRev8 "GFHB Forward Vision Object Type Track Revised 8";
BA_ "VNSigAllNodes" SG_ 1031 GFHBFVsnObjTypTrkRev8 1;
BA_ "SignalType" SG_ 1031 GFHBObjDirTrk8 "ENM";
BA_ "SignalLongName" SG_ 1031 GFHBObjDirTrk8 "GFHB Object Direction Track 8";
BA_ "VNSigAllNodes" SG_ 1031 GFHBObjDirTrk8 1;
BA_ "SignalType" SG_ 1031 GFHBFwVsnMesStatTrk8 "ENM";
BA_ "SignalLongName" SG_ 1031 GFHBFwVsnMesStatTrk8 "GFHB Forward Vision Measurement Status Track 8";
BA_ "VNSigAllNodes" SG_ 1031 GFHBFwVsnMesStatTrk8 1;
BA_ "SignalType" SG_ 1031 GFHBFwVsnObjIDTrk8 "UNM";
BA_ "SignalLongName" SG_ 1031 GFHBFwVsnObjIDTrk8 "GFHB Forward Vision Object ID Track 8";
BA_ "VNSigAllNodes" SG_ 1031 GFHBFwVsnObjIDTrk8 1;
BA_ "SignalType" SG_ 1030 GFHBFwVsnWidthTrk7 "UNM";
BA_ "SignalLongName" SG_ 1030 GFHBFwVsnWidthTrk7 "GFHB Forward Vision Width Track 7";
BA_ "VNSigAllNodes" SG_ 1030 GFHBFwVsnWidthTrk7 1;
BA_ "SignalType" SG_ 1030 GFHBFwVsnVertPosTrk7 "UNM";
BA_ "SignalLongName" SG_ 1030 GFHBFwVsnVertPosTrk7 "GFHB Forward Vision Vertical Position Track 7";
BA_ "VNSigAllNodes" SG_ 1030 GFHBFwVsnVertPosTrk7 1;
BA_ "SignalType" SG_ 1030 GFHBFwVsnRelLaneTrk7 "ENM";
BA_ "SignalLongName" SG_ 1030 GFHBFwVsnRelLaneTrk7 "GFHB Forward Vision Relative Lane Track 7";
BA_ "VNSigAllNodes" SG_ 1030 GFHBFwVsnRelLaneTrk7 1;
BA_ "SignalType" SG_ 1030 GFHBFwVsnAzmthRtTrk7 "SNM";
BA_ "SignalLongName" SG_ 1030 GFHBFwVsnAzmthRtTrk7 "GFHB Forward Vision Azimuth Rate Track 7";
BA_ "VNSigAllNodes" SG_ 1030 GFHBFwVsnAzmthRtTrk7 1;
BA_ "SignalType" SG_ 1030 GFHBFwVsnCnfdncTrk7 "ENM";
BA_ "SignalLongName" SG_ 1030 GFHBFwVsnCnfdncTrk7 "GFHB Forward Vision Confidence Track 7";
BA_ "VNSigAllNodes" SG_ 1030 GFHBFwVsnCnfdncTrk7 1;
BA_ "SignalType" SG_ 1030 GFHBFwVsnRngTrkRev7 "UNM";
BA_ "SignalLongName" SG_ 1030 GFHBFwVsnRngTrkRev7 "GFHB Forward Vision Range Track Revised 7";
BA_ "VNSigAllNodes" SG_ 1030 GFHBFwVsnRngTrkRev7 1;
BA_ "SignalType" SG_ 1030 GFHBFwVsnAzmthTrkRev7 "SNM";
BA_ "SignalLongName" SG_ 1030 GFHBFwVsnAzmthTrkRev7 "GFHB Forward Vision Azimuth Track Revised 7";
BA_ "VNSigAllNodes" SG_ 1030 GFHBFwVsnAzmthTrkRev7 1;
BA_ "SignalType" SG_ 1030 GFHBFVsnObjTypTrkRev7 "ENM";
BA_ "SignalLongName" SG_ 1030 GFHBFVsnObjTypTrkRev7 "GFHB Forward Vision Object Type Track Revised 7";
BA_ "VNSigAllNodes" SG_ 1030 GFHBFVsnObjTypTrkRev7 1;
BA_ "SignalType" SG_ 1030 GFHBObjDirTrk7 "ENM";
BA_ "SignalLongName" SG_ 1030 GFHBObjDirTrk7 "GFHB Object Direction Track 7";
BA_ "VNSigAllNodes" SG_ 1030 GFHBObjDirTrk7 1;
BA_ "SignalType" SG_ 1030 GFHBFwVsnMesStatTrk7 "ENM";
BA_ "SignalLongName" SG_ 1030 GFHBFwVsnMesStatTrk7 "GFHB Forward Vision Measurement Status Track 7";
BA_ "VNSigAllNodes" SG_ 1030 GFHBFwVsnMesStatTrk7 1;
BA_ "SignalType" SG_ 1030 GFHBFwVsnObjIDTrk7 "UNM";
BA_ "SignalLongName" SG_ 1030 GFHBFwVsnObjIDTrk7 "GFHB Forward Vision Object ID Track 7";
BA_ "VNSigAllNodes" SG_ 1030 GFHBFwVsnObjIDTrk7 1;
BA_ "SignalType" SG_ 479 EngAutoStpNotProb "BLN";
BA_ "SignalLongName" SG_ 479 EngAutoStpNotProb "Engine Auto Stop Not Probable";
BA_ "VNSigAllNodes" SG_ 479 EngAutoStpNotProb 1;
BA_ "SignalType" SG_ 479 EASSI_UnsdRsrvd2 "BLN";
BA_ "PacketOrder" SG_ 479 EASSI_UnsdRsrvd2 7;
BA_ "SignalLongName" SG_ 479 EASSI_UnsdRsrvd2 "Engine Auto Start Stop Information : Unused and Reserved 2";
BA_ "VNSigAllNodes" SG_ 479 EASSI_UnsdRsrvd2 1;
BA_ "SignalType" SG_ 479 EASSI_StlDetd "BLN";
BA_ "PacketOrder" SG_ 479 EASSI_StlDetd 5;
BA_ "SignalLongName" SG_ 479 EASSI_StlDetd "Engine Auto Start Stop Information : Stall Detected";
BA_ "VNSigAllNodes" SG_ 479 EASSI_StlDetd 1;
BA_ "SignalType" SG_ 479 EASSI_TrqDetd "BLN";
BA_ "PacketOrder" SG_ 479 EASSI_TrqDetd 4;
BA_ "SignalLongName" SG_ 479 EASSI_TrqDetd "Engine Auto Start Stop Information : Torque Detected";
BA_ "VNSigAllNodes" SG_ 479 EASSI_TrqDetd 1;
BA_ "SignalType" SG_ 479 EASSI_FuelReqOn "BLN";
BA_ "PacketOrder" SG_ 479 EASSI_FuelReqOn 3;
BA_ "SignalLongName" SG_ 479 EASSI_FuelReqOn "Engine Auto Start Stop Information : Fuel Requested On";
BA_ "VNSigAllNodes" SG_ 479 EASSI_FuelReqOn 1;
BA_ "SignalType" SG_ 479 EASSI_StrtTyp "ENM";
BA_ "PacketOrder" SG_ 479 EASSI_StrtTyp 2;
BA_ "SignalLongName" SG_ 479 EASSI_StrtTyp "Engine Auto Start Stop Information : Start Type";
BA_ "VNSigAllNodes" SG_ 479 EASSI_StrtTyp 1;
BA_ "SignalType" SG_ 479 EASSI_StrtStpSt "ENM";
BA_ "PacketOrder" SG_ 479 EASSI_StrtStpSt 1;
BA_ "SignalLongName" SG_ 479 EASSI_StrtStpSt "Engine Auto Start Stop Information : Start Stop State";
BA_ "VNSigAllNodes" SG_ 479 EASSI_StrtStpSt 1;
BA_ "SignalType" SG_ 479 EASSI_TorqDetdIndet "BLN";
BA_ "PacketOrder" SG_ 479 EASSI_TorqDetdIndet 6;
BA_ "SignalLongName" SG_ 479 EASSI_TorqDetdIndet "Engine Auto Start Stop Information : Torque Detected Indeterminate";
BA_ "VNSigAllNodes" SG_ 479 EASSI_TorqDetdIndet 1;
BA_ "SignalType" SG_ 479 ASIRI_Indication08 "BLN";
BA_ "PacketOrder" SG_ 479 ASIRI_Indication08 8;
BA_ "SignalLongName" SG_ 479 ASIRI_Indication08 "Auto Stop Inhibit Reason Indication : Indication 8";
BA_ "VNSigAllNodes" SG_ 479 ASIRI_Indication08 1;
BA_ "SignalType" SG_ 479 ASIRI_Indication07 "BLN";
BA_ "PacketOrder" SG_ 479 ASIRI_Indication07 7;
BA_ "SignalLongName" SG_ 479 ASIRI_Indication07 "Auto Stop Inhibit Reason Indication : Indication 7";
BA_ "VNSigAllNodes" SG_ 479 ASIRI_Indication07 1;
BA_ "SignalType" SG_ 479 ASIRI_Indication06 "BLN";
BA_ "PacketOrder" SG_ 479 ASIRI_Indication06 6;
BA_ "SignalLongName" SG_ 479 ASIRI_Indication06 "Auto Stop Inhibit Reason Indication : Indication 6";
BA_ "VNSigAllNodes" SG_ 479 ASIRI_Indication06 1;
BA_ "SignalType" SG_ 479 ASIRI_Indication05 "BLN";
BA_ "PacketOrder" SG_ 479 ASIRI_Indication05 5;
BA_ "SignalLongName" SG_ 479 ASIRI_Indication05 "Auto Stop Inhibit Reason Indication : Indication 5";
BA_ "VNSigAllNodes" SG_ 479 ASIRI_Indication05 1;
BA_ "SignalType" SG_ 479 ASIRI_Indication04 "BLN";
BA_ "PacketOrder" SG_ 479 ASIRI_Indication04 4;
BA_ "SignalLongName" SG_ 479 ASIRI_Indication04 "Auto Stop Inhibit Reason Indication : Indication 4";
BA_ "VNSigAllNodes" SG_ 479 ASIRI_Indication04 1;
BA_ "SignalType" SG_ 479 ASIRI_Indication03 "BLN";
BA_ "PacketOrder" SG_ 479 ASIRI_Indication03 3;
BA_ "SignalLongName" SG_ 479 ASIRI_Indication03 "Auto Stop Inhibit Reason Indication : Indication 3";
BA_ "VNSigAllNodes" SG_ 479 ASIRI_Indication03 1;
BA_ "SignalType" SG_ 479 ASIRI_Indication02 "BLN";
BA_ "PacketOrder" SG_ 479 ASIRI_Indication02 2;
BA_ "SignalLongName" SG_ 479 ASIRI_Indication02 "Auto Stop Inhibit Reason Indication : Indication 2";
BA_ "VNSigAllNodes" SG_ 479 ASIRI_Indication02 1;
BA_ "SignalType" SG_ 479 ASIRI_Indication01 "BLN";
BA_ "PacketOrder" SG_ 479 ASIRI_Indication01 1;
BA_ "SignalLongName" SG_ 479 ASIRI_Indication01 "Auto Stop Inhibit Reason Indication : Indication 1";
BA_ "VNSigAllNodes" SG_ 479 ASIRI_Indication01 1;
BA_ "SignalType" SG_ 479 PTWrmgWtToShftIO "BLN";
BA_ "SignalLongName" SG_ 479 PTWrmgWtToShftIO "Powertrain Warming Wait To Shift Indication On";
BA_ "VNSigAllNodes" SG_ 479 PTWrmgWtToShftIO 1;
BA_ "SignalType" SG_ 479 PrplsnSysAtv "BLN";
BA_ "SignalLongName" SG_ 479 PrplsnSysAtv "Propulsion System Active";
BA_ "VNSigAllNodes" SG_ 479 PrplsnSysAtv 1;
BA_ "SignalType" SG_ 479 PTShftLvrLckRqd "BLN";
BA_ "SignalLongName" SG_ 479 PTShftLvrLckRqd "Powertrain Shift Lever Lock Requested";
BA_ "VNSigAllNodes" SG_ 479 PTShftLvrLckRqd 1;
BA_ "SignalType" SG_ 211 ActAxleTrqV "ENM";
BA_ "SignalLongName" SG_ 211 ActAxleTrqV "Actual Axle Torque Validity";
BA_ "VNSigAllNodes" SG_ 211 ActAxleTrqV 1;
BA_ "SignalType" SG_ 211 ActAxleTrq "UNM";
BA_ "SignalLongName" SG_ 211 ActAxleTrq "Actual Axle Torque";
BA_ "VNSigAllNodes" SG_ 211 ActAxleTrq 1;
BA_ "SignalType" SG_ 1020 OtsAirTmpEmsnsRelV "ENM";
BA_ "SignalLongName" SG_ 1020 OtsAirTmpEmsnsRelV "Outside Air Temperature Emissions Related Validity";
BA_ "VNSigAllNodes" SG_ 1020 OtsAirTmpEmsnsRelV 1;
BA_ "SignalType" SG_ 1020 OtsAirTmpEmsnsRel "UNM";
BA_ "SignalLongName" SG_ 1020 OtsAirTmpEmsnsRel "Outside Air Temperature Emissions Related";
BA_ "VNSigAllNodes" SG_ 1020 OtsAirTmpEmsnsRel 1;
BA_ "SignalType" SG_ 1020 OATEmsnsRelCrValV "ENM";
BA_ "SignalLongName" SG_ 1020 OATEmsnsRelCrValV "Outside Air Temperature Emissions Related Corrected Value Validity";
BA_ "VNSigAllNodes" SG_ 1020 OATEmsnsRelCrValV 1;
BA_ "SignalType" SG_ 1020 OATEmsnsRelCrValM "ENM";
BA_ "SignalLongName" SG_ 1020 OATEmsnsRelCrValM "Outside Air Temperature Emissions Related Corrected Value Mask";
BA_ "VNSigAllNodes" SG_ 1020 OATEmsnsRelCrValM 1;
BA_ "SignalType" SG_ 1020 OATEmsnsRelCrVal "UNM";
BA_ "SignalLongName" SG_ 1020 OATEmsnsRelCrVal "Outside Air Temperature Emissions Related Corrected Value";
BA_ "VNSigAllNodes" SG_ 1020 OATEmsnsRelCrVal 1;
BA_ "SignalType" SG_ 1020 CatlystOutGasTempEstV "ENM";
BA_ "SignalLongName" SG_ 1020 CatlystOutGasTempEstV "Catalyst Outlet Gas Temperature Estimate Validity";
BA_ "VNSigAllNodes" SG_ 1020 CatlystOutGasTempEstV 1;
BA_ "SignalType" SG_ 1020 CatlystOutGasTempEst "UNM";
BA_ "SignalLongName" SG_ 1020 CatlystOutGasTempEst "Catalyst Outlet Gas Temperature Estimate";
BA_ "VNSigAllNodes" SG_ 1020 CatlystOutGasTempEst 1;
BA_ "SignalType" SG_ 1020 OtsAirTmpCrValMsk "ENM";
BA_ "SignalLongName" SG_ 1020 OtsAirTmpCrValMsk "Outside Air Temperature Corrected Value Mask";
BA_ "VNSigAllNodes" SG_ 1020 OtsAirTmpCrValMsk 1;
BA_ "SignalType" SG_ 1020 OtsAirTmpV "ENM";
BA_ "SignalLongName" SG_ 1020 OtsAirTmpV "Outside Air Temperature Validity";
BA_ "VNSigAllNodes" SG_ 1020 OtsAirTmpV 1;
BA_ "SignalType" SG_ 1020 OtsAirTmpCrValV "ENM";
BA_ "SignalLongName" SG_ 1020 OtsAirTmpCrValV "Outside Air Temperature Corrected Value Validity";
BA_ "VNSigAllNodes" SG_ 1020 OtsAirTmpCrValV 1;
BA_ "SignalType" SG_ 1020 OtsAirTmpCrVal "UNM";
BA_ "SignalLongName" SG_ 1020 OtsAirTmpCrVal "Outside Air Temperature Corrected Value";
BA_ "VNSigAllNodes" SG_ 1020 OtsAirTmpCrVal 1;
BA_ "SignalType" SG_ 1020 OtsAirTmp "UNM";
BA_ "SignalLongName" SG_ 1020 OtsAirTmp "Outside Air Temperature";
BA_ "VNSigAllNodes" SG_ 1020 OtsAirTmp 1;
BA_ "SignalType" SG_ 1020 EngInltSpcfcHmdtyV "ENM";
BA_ "SignalLongName" SG_ 1020 EngInltSpcfcHmdtyV "Engine Inlet Specific Humidity Validity";
BA_ "VNSigAllNodes" SG_ 1020 EngInltSpcfcHmdtyV 1;
BA_ "SignalType" SG_ 1020 EngInltSpcfcHmdtyM "ENM";
BA_ "SignalLongName" SG_ 1020 EngInltSpcfcHmdtyM "Engine Inlet Specific Humidity Mask";
BA_ "VNSigAllNodes" SG_ 1020 EngInltSpcfcHmdtyM 1;
BA_ "SignalType" SG_ 1020 EngInltSpcfcHmdty "UNM";
BA_ "SignalLongName" SG_ 1020 EngInltSpcfcHmdty "Engine Inlet Specific Humidity";
BA_ "VNSigAllNodes" SG_ 1020 EngInltSpcfcHmdty 1;
BA_ "SignalType" SG_ 567 ExtHlStrAssCsCrStVal "ENM";
BA_ "SignalLongName" SG_ 567 ExtHlStrAssCsCrStVal "Extended Hill Start Assist Customization Current Setting Value";
BA_ "VNSigAllNodes" SG_ 567 ExtHlStrAssCsCrStVal 1;
BA_ "SignalType" SG_ 567 ExtHlStrAssCsStAvl "BLN";
BA_ "SignalLongName" SG_ 567 ExtHlStrAssCsStAvl "Extended Hill Start Assist Customization Setting Available";
BA_ "VNSigAllNodes" SG_ 567 ExtHlStrAssCsStAvl 1;
BA_ "SignalType" SG_ 567 DrvStyPerfMdCsCrStVal "ENM";
BA_ "SignalLongName" SG_ 567 DrvStyPerfMdCsCrStVal "Driving Style Performance Mode Customization Current Setting Value";
BA_ "VNSigAllNodes" SG_ 567 DrvStyPerfMdCsCrStVal 1;
BA_ "SignalType" SG_ 567 DrvStyPerfMdCsStAvl "BLN";
BA_ "SignalLongName" SG_ 567 DrvStyPerfMdCsStAvl "Driving Style Performance Mode Customization Setting Available";
BA_ "VNSigAllNodes" SG_ 567 DrvStyPerfMdCsStAvl 1;
BA_ "SignalType" SG_ 567 PsngStPerfMdCsCrStVal "ENM";
BA_ "SignalLongName" SG_ 567 PsngStPerfMdCsCrStVal "Passenger Seat Performance Mode Customization Current Setting Value";
BA_ "VNSigAllNodes" SG_ 567 PsngStPerfMdCsCrStVal 1;
BA_ "SignalType" SG_ 567 PsngStPerfMdCsStAvl "BLN";
BA_ "SignalLongName" SG_ 567 PsngStPerfMdCsStAvl "Passenger Seat Performance Mode Customization Setting Available";
BA_ "VNSigAllNodes" SG_ 567 PsngStPerfMdCsStAvl 1;
BA_ "SignalType" SG_ 567 DrvrStPerfMdCsCrStVal "ENM";
BA_ "SignalLongName" SG_ 567 DrvrStPerfMdCsCrStVal "Driver Seat Performance Mode Customization Current Setting Value";
BA_ "VNSigAllNodes" SG_ 567 DrvrStPerfMdCsCrStVal 1;
BA_ "SignalType" SG_ 567 DrvrStPerfMdCsStAvl "BLN";
BA_ "SignalLongName" SG_ 567 DrvrStPerfMdCsStAvl "Driver Seat Performance Mode Customization Setting Available";
BA_ "VNSigAllNodes" SG_ 567 DrvrStPerfMdCsStAvl 1;
BA_ "SignalType" SG_ 567 ACCPerfMdCsCrStVal "ENM";
BA_ "SignalLongName" SG_ 567 ACCPerfMdCsCrStVal "Adaptive Cruise Control Performance Mode Customization Current Setting Value";
BA_ "VNSigAllNodes" SG_ 567 ACCPerfMdCsCrStVal 1;
BA_ "SignalType" SG_ 567 ACCPerfMdCsStAvl "BLN";
BA_ "SignalLongName" SG_ 567 ACCPerfMdCsStAvl "Adaptive Cruise Control Performance Mode Customization Setting Available";
BA_ "VNSigAllNodes" SG_ 567 ACCPerfMdCsStAvl 1;
BA_ "SignalType" SG_ 1219 DslExhFldDiagWrnIdRq "ENM";
BA_ "SignalLongName" SG_ 1219 DslExhFldDiagWrnIdRq "Diesel Exhaust Fluid System Diagnostic Warning Indication Request";
BA_ "VNSigAllNodes" SG_ 1219 DslExhFldDiagWrnIdRq 1;
BA_ "SignalType" SG_ 1219 DslEmnsOBDMrkt "ENM";
BA_ "SignalLongName" SG_ 1219 DslEmnsOBDMrkt "Diesel Emissions OBD Market";
BA_ "VNSigAllNodes" SG_ 1219 DslEmnsOBDMrkt 1;
BA_ "SignalType" SG_ 1219 DslExNxEmWrngIndRq "ENM";
BA_ "SignalLongName" SG_ 1219 DslExNxEmWrngIndRq "Diesel Exhaust NOx Emissions Too High Warning Indication Request";
BA_ "VNSigAllNodes" SG_ 1219 DslExNxEmWrngIndRq 1;
BA_ "SignalType" SG_ 1219 DEFWVSL_S3SpdLmt "UNM";
BA_ "PacketOrder" SG_ 1219 DEFWVSL_S3SpdLmt 3;
BA_ "SignalLongName" SG_ 1219 DEFWVSL_S3SpdLmt "Diesel Exhaust Fluid Warning Vehicle Speed Limit : Stage 3 Vehicle Speed Limit";
BA_ "VNSigAllNodes" SG_ 1219 DEFWVSL_S3SpdLmt 1;
BA_ "SignalType" SG_ 1219 DEFWVSL_S2SpdLmt "UNM";
BA_ "PacketOrder" SG_ 1219 DEFWVSL_S2SpdLmt 2;
BA_ "SignalLongName" SG_ 1219 DEFWVSL_S2SpdLmt "Diesel Exhaust Fluid Warning Vehicle Speed Limit : Stage 2 Vehicle Speed Limit";
BA_ "VNSigAllNodes" SG_ 1219 DEFWVSL_S2SpdLmt 1;
BA_ "SignalType" SG_ 1219 DEFWVSL_S1SpdLmt "UNM";
BA_ "PacketOrder" SG_ 1219 DEFWVSL_S1SpdLmt 1;
BA_ "SignalLongName" SG_ 1219 DEFWVSL_S1SpdLmt "Diesel Exhaust Fluid Warning Vehicle Speed Limit : Stage 1 Vehicle Speed Limit";
BA_ "VNSigAllNodes" SG_ 1219 DEFWVSL_S1SpdLmt 1;
BA_ "SignalType" SG_ 1219 DslExFldTpWrngIndRq "ENM";
BA_ "SignalLongName" SG_ 1219 DslExFldTpWrngIndRq "Diesel Exhaust Fluid Tampering Warning Indication Request";
BA_ "VNSigAllNodes" SG_ 1219 DslExFldTpWrngIndRq 1;
BA_ "SignalType" SG_ 1219 DslExhFldQlyWrngIReq "ENM";
BA_ "SignalLongName" SG_ 1219 DslExhFldQlyWrngIReq "Diesel Exhaust Fluid Quality Warning Indication Request";
BA_ "VNSigAllNodes" SG_ 1219 DslExhFldQlyWrngIReq 1;
BA_ "SignalType" SG_ 1219 DslExhFldWrngIdRqER "ENM";
BA_ "SignalLongName" SG_ 1219 DslExhFldWrngIdRqER "Diesel Exhaust Fluid Level Warning Indication Request Extended Range";
BA_ "VNSigAllNodes" SG_ 1219 DslExhFldWrngIdRqER 1;
BA_ "SignalType" SG_ 1219 DslExFldCnWrngIndRq "ENM";
BA_ "SignalLongName" SG_ 1219 DslExFldCnWrngIndRq "Diesel Exhaust Fluid Consumption Monitoring Warning Indication Request";
BA_ "VNSigAllNodes" SG_ 1219 DslExFldCnWrngIndRq 1;
BA_ "SignalType" SG_ 372 ARSFlrIO "BLN";
BA_ "SignalLongName" SG_ 372 ARSFlrIO "Active Rear Steer Failure Indication On";
BA_ "VNSigAllNodes" SG_ 372 ARSFlrIO 1;
BA_ "SignalType" SG_ 528 BrkSysAutBrkReqRC "UNM";
BA_ "SignalLongName" SG_ 528 BrkSysAutBrkReqRC "Brake System Autonomous Braking Request Rolling Count";
BA_ "VNSigAllNodes" SG_ 528 BrkSysAutBrkReqRC 1;
BA_ "SignalType" SG_ 528 BrkSysAutBrkReqPVal "UNM";
BA_ "SignalLongName" SG_ 528 BrkSysAutBrkReqPVal "Brake System Autonomous Braking Request Protection Value";
BA_ "VNSigAllNodes" SG_ 528 BrkSysAutBrkReqPVal 1;
BA_ "SignalType" SG_ 528 BSABR_TrlBrkRq "UNM";
BA_ "PacketOrder" SG_ 528 BSABR_TrlBrkRq 1;
BA_ "SignalLongName" SG_ 528 BSABR_TrlBrkRq "Brake System Autonomous Braking Request : Trailer Brake Request";
BA_ "VNSigAllNodes" SG_ 528 BSABR_TrlBrkRq 1;
BA_ "SignalType" SG_ 528 BSABR_TrlBrkCntlIntRq "BLN";
BA_ "PacketOrder" SG_ 528 BSABR_TrlBrkCntlIntRq 2;
BA_ "SignalLongName" SG_ 528 BSABR_TrlBrkCntlIntRq "Brake System Autonomous Braking Request : Trailer Brake Control Interactive Request";
BA_ "VNSigAllNodes" SG_ 528 BSABR_TrlBrkCntlIntRq 1;
BA_ "SignalType" SG_ 442 CrksftTqMinImCapV "ENM";
BA_ "SignalLongName" SG_ 442 CrksftTqMinImCapV "Crankshaft Torque Minimum Immediate Capacity Validity";
BA_ "VNSigAllNodes" SG_ 442 CrksftTqMinImCapV 1;
BA_ "SignalType" SG_ 442 CrksftTqMinImCap "UNM";
BA_ "SignalLongName" SG_ 442 CrksftTqMinImCap "Crankshaft Torque Minimum Immediate Capacity";
BA_ "VNSigAllNodes" SG_ 442 CrksftTqMinImCap 1;
BA_ "SignalType" SG_ 442 DrvIntndCrksftTrqRw "UNM";
BA_ "SignalLongName" SG_ 442 DrvIntndCrksftTrqRw "Driver Intended Crankshaft Torque Raw";
BA_ "VNSigAllNodes" SG_ 442 DrvIntndCrksftTrqRw 1;
BA_ "SignalType" SG_ 442 DrvIntndCrksftTrqMin "UNM";
BA_ "SignalLongName" SG_ 442 DrvIntndCrksftTrqMin "Driver Intended Crankshaft Torque Minimum";
BA_ "VNSigAllNodes" SG_ 442 DrvIntndCrksftTrqMin 1;
BA_ "SignalType" SG_ 442 DrvIntndCrksftTrq "UNM";
BA_ "SignalLongName" SG_ 442 DrvIntndCrksftTrq "Driver Intended Crankshaft Torque";
BA_ "VNSigAllNodes" SG_ 442 DrvIntndCrksftTrq 1;
BA_ "SignalType" SG_ 442 CrksftMaxTrqLmtV "ENM";
BA_ "SignalLongName" SG_ 442 CrksftMaxTrqLmtV "Crankshaft Maximum Torque Limit Validity";
BA_ "VNSigAllNodes" SG_ 442 CrksftMaxTrqLmtV 1;
BA_ "SignalType" SG_ 442 CrksftMaxTrqLmt "UNM";
BA_ "SignalLongName" SG_ 442 CrksftMaxTrqLmt "Crankshaft Maximum Torque Limit";
BA_ "VNSigAllNodes" SG_ 442 CrksftMaxTrqLmt 1;
BA_ "SignalType" SG_ 753 EBCMDS5_DTCStatus "ENM";
BA_ "PacketOrder" SG_ 753 EBCMDS5_DTCStatus 2;
BA_ "SignalLongName" SG_ 753 EBCMDS5_DTCStatus "Electronic Brake Control Module Diagnostic Status 5 : Diagnostic Trouble Code Status";
BA_ "VNSigAllNodes" SG_ 753 EBCMDS5_DTCStatus 1;
BA_ "SignalType" SG_ 753 EBCMDS5_DTCIndex "UNM";
BA_ "PacketOrder" SG_ 753 EBCMDS5_DTCIndex 1;
BA_ "SignalLongName" SG_ 753 EBCMDS5_DTCIndex "Electronic Brake Control Module Diagnostic Status 5 : Diagnostic Trouble Code Index";
BA_ "VNSigAllNodes" SG_ 753 EBCMDS5_DTCIndex 1;
BA_ "SignalType" SG_ 753 EBCMDS4_DTCStatus "ENM";
BA_ "PacketOrder" SG_ 753 EBCMDS4_DTCStatus 2;
BA_ "SignalLongName" SG_ 753 EBCMDS4_DTCStatus "Electronic Brake Control Module Diagnostic Status 4 : Diagnostic Trouble Code Status";
BA_ "VNSigAllNodes" SG_ 753 EBCMDS4_DTCStatus 1;
BA_ "SignalType" SG_ 753 EBCMDS4_DTCIndex "UNM";
BA_ "PacketOrder" SG_ 753 EBCMDS4_DTCIndex 1;
BA_ "SignalLongName" SG_ 753 EBCMDS4_DTCIndex "Electronic Brake Control Module Diagnostic Status 4 : Diagnostic Trouble Code Index";
BA_ "VNSigAllNodes" SG_ 753 EBCMDS4_DTCIndex 1;
BA_ "SignalType" SG_ 753 EBCMDS3_DTCStatus "ENM";
BA_ "PacketOrder" SG_ 753 EBCMDS3_DTCStatus 2;
BA_ "SignalLongName" SG_ 753 EBCMDS3_DTCStatus "Electronic Brake Control Module Diagnostic Status 3 : Diagnostic Trouble Code Status";
BA_ "VNSigAllNodes" SG_ 753 EBCMDS3_DTCStatus 1;
BA_ "SignalType" SG_ 753 EBCMDS3_DTCIndex "UNM";
BA_ "PacketOrder" SG_ 753 EBCMDS3_DTCIndex 1;
BA_ "SignalLongName" SG_ 753 EBCMDS3_DTCIndex "Electronic Brake Control Module Diagnostic Status 3 : Diagnostic Trouble Code Index";
BA_ "VNSigAllNodes" SG_ 753 EBCMDS3_DTCIndex 1;
BA_ "SignalType" SG_ 753 EBCMDS2_DTCStatus "ENM";
BA_ "PacketOrder" SG_ 753 EBCMDS2_DTCStatus 2;
BA_ "SignalLongName" SG_ 753 EBCMDS2_DTCStatus "Electronic Brake Control Module Diagnostic Status 2 : Diagnostic Trouble Code Status";
BA_ "VNSigAllNodes" SG_ 753 EBCMDS2_DTCStatus 1;
BA_ "SignalType" SG_ 753 EBCMDS2_DTCIndex "UNM";
BA_ "PacketOrder" SG_ 753 EBCMDS2_DTCIndex 1;
BA_ "SignalLongName" SG_ 753 EBCMDS2_DTCIndex "Electronic Brake Control Module Diagnostic Status 2 : Diagnostic Trouble Code Index";
BA_ "VNSigAllNodes" SG_ 753 EBCMDS2_DTCIndex 1;
BA_ "SignalType" SG_ 753 EBCMDS1_DTCStatus "ENM";
BA_ "PacketOrder" SG_ 753 EBCMDS1_DTCStatus 2;
BA_ "SignalLongName" SG_ 753 EBCMDS1_DTCStatus "Electronic Brake Control Module Diagnostic Status 1 : Diagnostic Trouble Code Status";
BA_ "VNSigAllNodes" SG_ 753 EBCMDS1_DTCStatus 1;
BA_ "SignalType" SG_ 753 EBCMDS1_DTCIndex "UNM";
BA_ "PacketOrder" SG_ 753 EBCMDS1_DTCIndex 1;
BA_ "SignalLongName" SG_ 753 EBCMDS1_DTCIndex "Electronic Brake Control Module Diagnostic Status 1 : Diagnostic Trouble Code Index";
BA_ "VNSigAllNodes" SG_ 753 EBCMDS1_DTCIndex 1;
BA_ "SignalType" SG_ 989 RdHVCntctrShdwnReq "ENM";
BA_ "SignalLongName" SG_ 989 RdHVCntctrShdwnReq "Redundant High Voltage Contactor Shutdown Request";
BA_ "VNSigAllNodes" SG_ 989 RdHVCntctrShdwnReq 1;
BA_ "SignalType" SG_ 989 AuxClntHtrVlvStat "ENM";
BA_ "SignalLongName" SG_ 989 AuxClntHtrVlvStat "Auxiliary Coolant Heater Valve Status";
BA_ "VNSigAllNodes" SG_ 989 AuxClntHtrVlvStat 1;
BA_ "SignalType" SG_ 989 EngCoolFanOpEnbl "BLN";
BA_ "SignalLongName" SG_ 989 EngCoolFanOpEnbl "Engine Cooling Fan Operation Enable";
BA_ "VNSigAllNodes" SG_ 989 EngCoolFanOpEnbl 1;
BA_ "SignalType" SG_ 989 DiagFreeRunCntrV "ENM";
BA_ "SignalLongName" SG_ 989 DiagFreeRunCntrV "Diagnostic Free Running Counter Validity";
BA_ "VNSigAllNodes" SG_ 989 DiagFreeRunCntrV 1;
BA_ "SignalType" SG_ 989 DiagFreeRunCntr "UNM";
BA_ "SignalLongName" SG_ 989 DiagFreeRunCntr "Diagnostic Free Running Counter";
BA_ "VNSigAllNodes" SG_ 989 DiagFreeRunCntr 1;
BA_ "SignalType" SG_ 989 JmpStrtEnbld "BLN";
BA_ "SignalLongName" SG_ 989 JmpStrtEnbld "Jump Start Enabled";
BA_ "VNSigAllNodes" SG_ 989 JmpStrtEnbld 1;
BA_ "SignalType" SG_ 989 HybFanSpdRq "UNM";
BA_ "SignalLongName" SG_ 989 HybFanSpdRq "Hybrid Fan Speed Percent Request";
BA_ "VNSigAllNodes" SG_ 989 HybFanSpdRq 1;
BA_ "SignalType" SG_ 989 MntnceMdStEngRq "BLN";
BA_ "SignalLongName" SG_ 989 MntnceMdStEngRq "Maintenance Mode Start Engine Request";
BA_ "VNSigAllNodes" SG_ 989 MntnceMdStEngRq 1;
BA_ "SignalType" SG_ 989 ThrmlRefCompSpdV "ENM";
BA_ "SignalLongName" SG_ 989 ThrmlRefCompSpdV "Thermal Refrigerant Compressor Speed Validity";
BA_ "VNSigAllNodes" SG_ 989 ThrmlRefCompSpdV 1;
BA_ "SignalType" SG_ 989 ThrmlRefCompSpd "UNM";
BA_ "SignalLongName" SG_ 989 ThrmlRefCompSpd "Thermal Refrigerant Compressor Speed";
BA_ "VNSigAllNodes" SG_ 989 ThrmlRefCompSpd 1;
BA_ "SignalType" SG_ 989 RdHVCntctrCmdStat "ENM";
BA_ "SignalLongName" SG_ 989 RdHVCntctrCmdStat "Redundant High Voltage Contactor Command Status";
BA_ "VNSigAllNodes" SG_ 989 RdHVCntctrCmdStat 1;
BA_ "SignalType" SG_ 550 ACCMCII_DtBtG "ASC";
BA_ "PacketOrder" SG_ 550 ACCMCII_DtBtG 10;
BA_ "SignalLongName" SG_ 550 ACCMCII_DtBtG "Air Compressor Control Module Calibration Identification : Data Byte G";
BA_ "VNSigAllNodes" SG_ 550 ACCMCII_DtBtG 1;
BA_ "SignalType" SG_ 550 ACCMCII_DtBtF "ASC";
BA_ "PacketOrder" SG_ 550 ACCMCII_DtBtF 9;
BA_ "SignalLongName" SG_ 550 ACCMCII_DtBtF "Air Compressor Control Module Calibration Identification : Data Byte F";
BA_ "VNSigAllNodes" SG_ 550 ACCMCII_DtBtF 1;
BA_ "SignalType" SG_ 550 ACCMCII_DtBtE "ASC";
BA_ "PacketOrder" SG_ 550 ACCMCII_DtBtE 8;
BA_ "SignalLongName" SG_ 550 ACCMCII_DtBtE "Air Compressor Control Module Calibration Identification : Data Byte E";
BA_ "VNSigAllNodes" SG_ 550 ACCMCII_DtBtE 1;
BA_ "SignalType" SG_ 550 ACCMCII_DtBtD "ASC";
BA_ "PacketOrder" SG_ 550 ACCMCII_DtBtD 7;
BA_ "SignalLongName" SG_ 550 ACCMCII_DtBtD "Air Compressor Control Module Calibration Identification : Data Byte D";
BA_ "VNSigAllNodes" SG_ 550 ACCMCII_DtBtD 1;
BA_ "SignalType" SG_ 550 ACCMCII_DtBtC "ASC";
BA_ "PacketOrder" SG_ 550 ACCMCII_DtBtC 6;
BA_ "SignalLongName" SG_ 550 ACCMCII_DtBtC "Air Compressor Control Module Calibration Identification : Data Byte C";
BA_ "VNSigAllNodes" SG_ 550 ACCMCII_DtBtC 1;
BA_ "SignalType" SG_ 550 ACCMCII_DtBtB "ASC";
BA_ "PacketOrder" SG_ 550 ACCMCII_DtBtB 5;
BA_ "SignalLongName" SG_ 550 ACCMCII_DtBtB "Air Compressor Control Module Calibration Identification : Data Byte B";
BA_ "VNSigAllNodes" SG_ 550 ACCMCII_DtBtB 1;
BA_ "SignalType" SG_ 550 ACCMCII_DtBtA "ASC";
BA_ "PacketOrder" SG_ 550 ACCMCII_DtBtA 4;
BA_ "SignalLongName" SG_ 550 ACCMCII_DtBtA "Air Compressor Control Module Calibration Identification : Data Byte A";
BA_ "VNSigAllNodes" SG_ 550 ACCMCII_DtBtA 1;
BA_ "SignalType" SG_ 550 ACCMCII_SeqNum "UNM";
BA_ "PacketOrder" SG_ 550 ACCMCII_SeqNum 3;
BA_ "SignalLongName" SG_ 550 ACCMCII_SeqNum "Air Compressor Control Module Calibration Identification : Sequence Number";
BA_ "VNSigAllNodes" SG_ 550 ACCMCII_SeqNum 1;
BA_ "SignalType" SG_ 550 ACCMCII_Index "UNM";
BA_ "PacketOrder" SG_ 550 ACCMCII_Index 1;
BA_ "SignalLongName" SG_ 550 ACCMCII_Index "Air Compressor Control Module Calibration Identification : Index";
BA_ "VNSigAllNodes" SG_ 550 ACCMCII_Index 1;
BA_ "SignalType" SG_ 550 ACCMCII_DatStat "ENM";
BA_ "PacketOrder" SG_ 550 ACCMCII_DatStat 2;
BA_ "SignalLongName" SG_ 550 ACCMCII_DatStat "Air Compressor Control Module Calibration Identification : Data Status";
BA_ "VNSigAllNodes" SG_ 550 ACCMCII_DatStat 1;
BA_ "SignalType" SG_ 988 EGHRInhbtRqstd "BLN";
BA_ "SignalLongName" SG_ 988 EGHRInhbtRqstd "Exhaust Gas Heat Recovery Inhibit Requested";
BA_ "VNSigAllNodes" SG_ 988 EGHRInhbtRqstd 1;
BA_ "SignalType" SG_ 988 AccPwrModMinCoolRq "ENM";
BA_ "SignalLongName" SG_ 988 AccPwrModMinCoolRq "Accessory Power Module Minimum Cooling Request";
BA_ "VNSigAllNodes" SG_ 988 AccPwrModMinCoolRq 1;
BA_ "SignalType" SG_ 988 A6ERRAlrmTime "UNM";
BA_ "PacketOrder" SG_ 988 A6ERRAlrmTime 2;
BA_ "SignalLongName" SG_ 988 A6ERRAlrmTime "Alarm 6 Extended Range Request : Alarm Time";
BA_ "VNSigAllNodes" SG_ 988 A6ERRAlrmTime 1;
BA_ "SignalType" SG_ 988 A6ERRAlrmReq "ENM";
BA_ "PacketOrder" SG_ 988 A6ERRAlrmReq 1;
BA_ "SignalLongName" SG_ 988 A6ERRAlrmReq "Alarm 6 Extended Range Request : Alarm Request";
BA_ "VNSigAllNodes" SG_ 988 A6ERRAlrmReq 1;
BA_ "SignalType" SG_ 988 EngMntncePrcntCpl "UNM";
BA_ "SignalLongName" SG_ 988 EngMntncePrcntCpl "Engine Maintenance Percent Complete";
BA_ "VNSigAllNodes" SG_ 988 EngMntncePrcntCpl 1;
BA_ "SignalType" SG_ 988 MntnceMdDsplyRq "ENM";
BA_ "SignalLongName" SG_ 988 MntnceMdDsplyRq "Maintenance Mode Display Request";
BA_ "VNSigAllNodes" SG_ 988 MntnceMdDsplyRq 1;
BA_ "SignalType" SG_ 988 EngMntnceMdAct "BLN";
BA_ "SignalLongName" SG_ 988 EngMntnceMdAct "Engine Maintenance Mode Active";
BA_ "VNSigAllNodes" SG_ 988 EngMntnceMdAct 1;
BA_ "SignalType" SG_ 988 HVPropChgrUnbl "BLN";
BA_ "SignalLongName" SG_ 988 HVPropChgrUnbl "High Voltage Propulsion Charging Unavailable";
BA_ "VNSigAllNodes" SG_ 988 HVPropChgrUnbl 1;
BA_ "SignalType" SG_ 988 EngHtrValvBpasCmd "ENM";
BA_ "SignalLongName" SG_ 988 EngHtrValvBpasCmd "Engine Heater Valve Bypass Command";
BA_ "VNSigAllNodes" SG_ 988 EngHtrValvBpasCmd 1;
BA_REL_ "GenSigSuprvResp" BU_SG_REL_ BCM_HS SG_ 563 SPMCA_SusPrfMd6Avl 1;
BA_REL_ "GenSigTimeoutMsg" BU_SG_REL_ BCM_HS SG_ 563 SPMCA_SusPrfMd6Avl 563;
BA_REL_ "GenSigTimeoutTime" BU_SG_REL_ BCM_HS SG_ 563 SPMCA_SusPrfMd6Avl 5000;
BA_REL_ "GenSigSuprvResp" BU_SG_REL_ BCM_HS SG_ 563 SPMCA_SusPrfMd5Avl 1;
BA_REL_ "GenSigTimeoutMsg" BU_SG_REL_ BCM_HS SG_ 563 SPMCA_SusPrfMd5Avl 563;
BA_REL_ "GenSigTimeoutTime" BU_SG_REL_ BCM_HS SG_ 563 SPMCA_SusPrfMd5Avl 5000;
BA_REL_ "GenSigSuprvResp" BU_SG_REL_ BCM_HS SG_ 563 SPMCA_SusPrfMd4Avl 1;
BA_REL_ "GenSigTimeoutMsg" BU_SG_REL_ BCM_HS SG_ 563 SPMCA_SusPrfMd4Avl 563;
BA_REL_ "GenSigTimeoutTime" BU_SG_REL_ BCM_HS SG_ 563 SPMCA_SusPrfMd4Avl 5000;
BA_REL_ "GenSigSuprvResp" BU_SG_REL_ BCM_HS SG_ 563 SPMCA_SusPrfMd3Avl 1;
BA_REL_ "GenSigTimeoutMsg" BU_SG_REL_ BCM_HS SG_ 563 SPMCA_SusPrfMd3Avl 563;
BA_REL_ "GenSigTimeoutTime" BU_SG_REL_ BCM_HS SG_ 563 SPMCA_SusPrfMd3Avl 5000;
BA_REL_ "GenSigSuprvResp" BU_SG_REL_ BCM_HS SG_ 563 SPMCA_SusPrfMd2Avl 1;
BA_REL_ "GenSigTimeoutMsg" BU_SG_REL_ BCM_HS SG_ 563 SPMCA_SusPrfMd2Avl 563;
BA_REL_ "GenSigTimeoutTime" BU_SG_REL_ BCM_HS SG_ 563 SPMCA_SusPrfMd2Avl 5000;
BA_REL_ "GenSigSuprvResp" BU_SG_REL_ BCM_HS SG_ 563 SPMCA_SusPrfMd1Avl 1;
BA_REL_ "GenSigTimeoutMsg" BU_SG_REL_ BCM_HS SG_ 563 SPMCA_SusPrfMd1Avl 563;
BA_REL_ "GenSigTimeoutTime" BU_SG_REL_ BCM_HS SG_ 563 SPMCA_SusPrfMd1Avl 5000;
BA_REL_ "GenSigSuprvResp" BU_SG_REL_ BCM_HS SG_ 563 SPMCA_StrPrfMd6Avl 1;
BA_REL_ "GenSigTimeoutMsg" BU_SG_REL_ BCM_HS SG_ 563 SPMCA_StrPrfMd6Avl 563;
BA_REL_ "GenSigTimeoutTime" BU_SG_REL_ BCM_HS SG_ 563 SPMCA_StrPrfMd6Avl 5000;
BA_REL_ "GenSigSuprvResp" BU_SG_REL_ BCM_HS SG_ 563 SPMCA_StrPrfMd5Avl 1;
BA_REL_ "GenSigTimeoutMsg" BU_SG_REL_ BCM_HS SG_ 563 SPMCA_StrPrfMd5Avl 563;
BA_REL_ "GenSigTimeoutTime" BU_SG_REL_ BCM_HS SG_ 563 SPMCA_StrPrfMd5Avl 5000;
BA_REL_ "GenSigSuprvResp" BU_SG_REL_ BCM_HS SG_ 563 SPMCA_StrPrfMd4Avl 1;
BA_REL_ "GenSigTimeoutMsg" BU_SG_REL_ BCM_HS SG_ 563 SPMCA_StrPrfMd4Avl 563;
BA_REL_ "GenSigTimeoutTime" BU_SG_REL_ BCM_HS SG_ 563 SPMCA_StrPrfMd4Avl 5000;
BA_REL_ "GenSigSuprvResp" BU_SG_REL_ BCM_HS SG_ 563 SPMCA_StrPrfMd3Avl 1;
BA_REL_ "GenSigTimeoutMsg" BU_SG_REL_ BCM_HS SG_ 563 SPMCA_StrPrfMd3Avl 563;
BA_REL_ "GenSigTimeoutTime" BU_SG_REL_ BCM_HS SG_ 563 SPMCA_StrPrfMd3Avl 5000;
BA_REL_ "GenSigSuprvResp" BU_SG_REL_ BCM_HS SG_ 563 SPMCA_StrPrfMd2Avl 1;
BA_REL_ "GenSigTimeoutMsg" BU_SG_REL_ BCM_HS SG_ 563 SPMCA_StrPrfMd2Avl 563;
BA_REL_ "GenSigTimeoutTime" BU_SG_REL_ BCM_HS SG_ 563 SPMCA_StrPrfMd2Avl 5000;
BA_REL_ "GenSigSuprvResp" BU_SG_REL_ BCM_HS SG_ 563 SPMCA_StrPrfMd1Avl 1;
BA_REL_ "GenSigTimeoutMsg" BU_SG_REL_ BCM_HS SG_ 563 SPMCA_StrPrfMd1Avl 563;
BA_REL_ "GenSigTimeoutTime" BU_SG_REL_ BCM_HS SG_ 563 SPMCA_StrPrfMd1Avl 5000;
BA_REL_ "GenSigSuprvResp" BU_SG_REL_ BCM_HS SG_ 563 SPMCA_SndPrfMd6Avl 1;
BA_REL_ "GenSigTimeoutMsg" BU_SG_REL_ BCM_HS SG_ 563 SPMCA_SndPrfMd6Avl 563;
BA_REL_ "GenSigTimeoutTime" BU_SG_REL_ BCM_HS SG_ 563 SPMCA_SndPrfMd6Avl 5000;
BA_REL_ "GenSigSuprvResp" BU_SG_REL_ BCM_HS SG_ 563 SPMCA_SndPrfMd5Avl 1;
BA_REL_ "GenSigTimeoutMsg" BU_SG_REL_ BCM_HS SG_ 563 SPMCA_SndPrfMd5Avl 563;
BA_REL_ "GenSigTimeoutTime" BU_SG_REL_ BCM_HS SG_ 563 SPMCA_SndPrfMd5Avl 5000;
BA_REL_ "GenSigSuprvResp" BU_SG_REL_ BCM_HS SG_ 563 SPMCA_SndPrfMd4Avl 1;
BA_REL_ "GenSigTimeoutMsg" BU_SG_REL_ BCM_HS SG_ 563 SPMCA_SndPrfMd4Avl 563;
BA_REL_ "GenSigTimeoutTime" BU_SG_REL_ BCM_HS SG_ 563 SPMCA_SndPrfMd4Avl 5000;
BA_REL_ "GenSigSuprvResp" BU_SG_REL_ BCM_HS SG_ 563 SPMCA_SndPrfMd3Avl 1;
BA_REL_ "GenSigTimeoutMsg" BU_SG_REL_ BCM_HS SG_ 563 SPMCA_SndPrfMd3Avl 563;
BA_REL_ "GenSigTimeoutTime" BU_SG_REL_ BCM_HS SG_ 563 SPMCA_SndPrfMd3Avl 5000;
BA_REL_ "GenSigSuprvResp" BU_SG_REL_ BCM_HS SG_ 563 SPMCA_SndPrfMd2Avl 1;
BA_REL_ "GenSigTimeoutMsg" BU_SG_REL_ BCM_HS SG_ 563 SPMCA_SndPrfMd2Avl 563;
BA_REL_ "GenSigTimeoutTime" BU_SG_REL_ BCM_HS SG_ 563 SPMCA_SndPrfMd2Avl 5000;
BA_REL_ "GenSigSuprvResp" BU_SG_REL_ BCM_HS SG_ 563 SPMCA_SndPrfMd1Avl 1;
BA_REL_ "GenSigTimeoutMsg" BU_SG_REL_ BCM_HS SG_ 563 SPMCA_SndPrfMd1Avl 563;
BA_REL_ "GenSigTimeoutTime" BU_SG_REL_ BCM_HS SG_ 563 SPMCA_SndPrfMd1Avl 5000;
BA_REL_ "GenSigSuprvResp" BU_SG_REL_ BCM_HS SG_ 563 DPMCA_DispPrfMd6Avl 1;
BA_REL_ "GenSigTimeoutMsg" BU_SG_REL_ BCM_HS SG_ 563 DPMCA_DispPrfMd6Avl 563;
BA_REL_ "GenSigTimeoutTime" BU_SG_REL_ BCM_HS SG_ 563 DPMCA_DispPrfMd6Avl 5000;
BA_REL_ "GenSigSuprvResp" BU_SG_REL_ BCM_HS SG_ 563 DPMCA_DispPrfMd5Avl 1;
BA_REL_ "GenSigTimeoutMsg" BU_SG_REL_ BCM_HS SG_ 563 DPMCA_DispPrfMd5Avl 563;
BA_REL_ "GenSigTimeoutTime" BU_SG_REL_ BCM_HS SG_ 563 DPMCA_DispPrfMd5Avl 5000;
BA_REL_ "GenSigSuprvResp" BU_SG_REL_ BCM_HS SG_ 563 DPMCA_DispPrfMd4Avl 1;
BA_REL_ "GenSigTimeoutMsg" BU_SG_REL_ BCM_HS SG_ 563 DPMCA_DispPrfMd4Avl 563;
BA_REL_ "GenSigTimeoutTime" BU_SG_REL_ BCM_HS SG_ 563 DPMCA_DispPrfMd4Avl 5000;
BA_REL_ "GenSigSuprvResp" BU_SG_REL_ BCM_HS SG_ 563 DPMCA_DispPrfMd3Avl 1;
BA_REL_ "GenSigTimeoutMsg" BU_SG_REL_ BCM_HS SG_ 563 DPMCA_DispPrfMd3Avl 563;
BA_REL_ "GenSigTimeoutTime" BU_SG_REL_ BCM_HS SG_ 563 DPMCA_DispPrfMd3Avl 5000;
BA_REL_ "GenSigSuprvResp" BU_SG_REL_ BCM_HS SG_ 563 DPMCA_DispPrfMd2Avl 1;
BA_REL_ "GenSigTimeoutMsg" BU_SG_REL_ BCM_HS SG_ 563 DPMCA_DispPrfMd2Avl 563;
BA_REL_ "GenSigTimeoutTime" BU_SG_REL_ BCM_HS SG_ 563 DPMCA_DispPrfMd2Avl 5000;
BA_REL_ "GenSigSuprvResp" BU_SG_REL_ BCM_HS SG_ 563 DPMCA_DispPrfMd1Avl 1;
BA_REL_ "GenSigTimeoutMsg" BU_SG_REL_ BCM_HS SG_ 563 DPMCA_DispPrfMd1Avl 563;
BA_REL_ "GenSigTimeoutTime" BU_SG_REL_ BCM_HS SG_ 563 DPMCA_DispPrfMd1Avl 5000;
BA_REL_ "GenSigSuprvResp" BU_SG_REL_ BCM_HS SG_ 563 DPMCA_DrvlPrfMd6Avl 1;
BA_REL_ "GenSigTimeoutMsg" BU_SG_REL_ BCM_HS SG_ 563 DPMCA_DrvlPrfMd6Avl 563;
BA_REL_ "GenSigTimeoutTime" BU_SG_REL_ BCM_HS SG_ 563 DPMCA_DrvlPrfMd6Avl 5000;
BA_REL_ "GenSigSuprvResp" BU_SG_REL_ BCM_HS SG_ 563 DPMCA_DrvlPrfMd5Avl 1;
BA_REL_ "GenSigTimeoutMsg" BU_SG_REL_ BCM_HS SG_ 563 DPMCA_DrvlPrfMd5Avl 563;
BA_REL_ "GenSigTimeoutTime" BU_SG_REL_ BCM_HS SG_ 563 DPMCA_DrvlPrfMd5Avl 5000;
BA_REL_ "GenSigSuprvResp" BU_SG_REL_ BCM_HS SG_ 563 DPMCA_DrvlPrfMd4Avl 1;
BA_REL_ "GenSigTimeoutMsg" BU_SG_REL_ BCM_HS SG_ 563 DPMCA_DrvlPrfMd4Avl 563;
BA_REL_ "GenSigTimeoutTime" BU_SG_REL_ BCM_HS SG_ 563 DPMCA_DrvlPrfMd4Avl 5000;
BA_REL_ "GenSigSuprvResp" BU_SG_REL_ BCM_HS SG_ 563 DPMCA_DrvlPrfMd3Avl 1;
BA_REL_ "GenSigTimeoutMsg" BU_SG_REL_ BCM_HS SG_ 563 DPMCA_DrvlPrfMd3Avl 563;
BA_REL_ "GenSigTimeoutTime" BU_SG_REL_ BCM_HS SG_ 563 DPMCA_DrvlPrfMd3Avl 5000;
BA_REL_ "GenSigSuprvResp" BU_SG_REL_ BCM_HS SG_ 563 DPMCA_DrvlPrfMd2Avl 1;
BA_REL_ "GenSigTimeoutMsg" BU_SG_REL_ BCM_HS SG_ 563 DPMCA_DrvlPrfMd2Avl 563;
BA_REL_ "GenSigTimeoutTime" BU_SG_REL_ BCM_HS SG_ 563 DPMCA_DrvlPrfMd2Avl 5000;
BA_REL_ "GenSigSuprvResp" BU_SG_REL_ BCM_HS SG_ 563 DPMCA_DrvlPrfMd1Avl 1;
BA_REL_ "GenSigTimeoutMsg" BU_SG_REL_ BCM_HS SG_ 563 DPMCA_DrvlPrfMd1Avl 563;
BA_REL_ "GenSigTimeoutTime" BU_SG_REL_ BCM_HS SG_ 563 DPMCA_DrvlPrfMd1Avl 5000;
BA_REL_ "GenSigSuprvResp" BU_SG_REL_ EBCM_OBD_HS SG_ 1323 TireLRTmp 1;
BA_REL_ "GenSigTimeoutMsg" BU_SG_REL_ EBCM_OBD_HS SG_ 1323 TireLRTmp 1323;
BA_REL_ "GenSigTimeoutTime" BU_SG_REL_ EBCM_OBD_HS SG_ 1323 TireLRTmp 2500;
BA_REL_ "GenSigSuprvResp" BU_SG_REL_ EBCM_HS SG_ 1323 TireLRTmp 1;
BA_REL_ "GenSigTimeoutMsg" BU_SG_REL_ EBCM_HS SG_ 1323 TireLRTmp 1323;
BA_REL_ "GenSigTimeoutTime" BU_SG_REL_ EBCM_HS SG_ 1323 TireLRTmp 2500;
BA_REL_ "GenSigSuprvResp" BU_SG_REL_ ICCM_OBD_HS SG_ 1323 TireLRTmp 1;
BA_REL_ "GenSigTimeoutMsg" BU_SG_REL_ ICCM_OBD_HS SG_ 1323 TireLRTmp 1323;
BA_REL_ "GenSigTimeoutTime" BU_SG_REL_ ICCM_OBD_HS SG_ 1323 TireLRTmp 2500;
BA_REL_ "GenSigSuprvResp" BU_SG_REL_ ICCM_HS SG_ 1323 TireLRTmp 1;
BA_REL_ "GenSigTimeoutMsg" BU_SG_REL_ ICCM_HS SG_ 1323 TireLRTmp 1323;
BA_REL_ "GenSigTimeoutTime" BU_SG_REL_ ICCM_HS SG_ 1323 TireLRTmp 2500;
BA_REL_ "GenSigSuprvResp" BU_SG_REL_ RDCM_HS SG_ 1323 TireLRTmp 1;
BA_REL_ "GenSigTimeoutMsg" BU_SG_REL_ RDCM_HS SG_ 1323 TireLRTmp 1323;
BA_REL_ "GenSigTimeoutTime" BU_SG_REL_ RDCM_HS SG_ 1323 TireLRTmp 2500;
BA_REL_ "GenSigSuprvResp" BU_SG_REL_ EBCM_OBD_HS SG_ 1323 TireLFTmp 1;
BA_REL_ "GenSigTimeoutMsg" BU_SG_REL_ EBCM_OBD_HS SG_ 1323 TireLFTmp 1323;
BA_REL_ "GenSigTimeoutTime" BU_SG_REL_ EBCM_OBD_HS SG_ 1323 TireLFTmp 2500;
BA_REL_ "GenSigSuprvResp" BU_SG_REL_ EBCM_HS SG_ 1323 TireLFTmp 1;
BA_REL_ "GenSigTimeoutMsg" BU_SG_REL_ EBCM_HS SG_ 1323 TireLFTmp 1323;
BA_REL_ "GenSigTimeoutTime" BU_SG_REL_ EBCM_HS SG_ 1323 TireLFTmp 2500;
BA_REL_ "GenSigSuprvResp" BU_SG_REL_ ICCM_OBD_HS SG_ 1323 TireLFTmp 1;
BA_REL_ "GenSigTimeoutMsg" BU_SG_REL_ ICCM_OBD_HS SG_ 1323 TireLFTmp 1323;
BA_REL_ "GenSigTimeoutTime" BU_SG_REL_ ICCM_OBD_HS SG_ 1323 TireLFTmp 2500;
BA_REL_ "GenSigSuprvResp" BU_SG_REL_ ICCM_HS SG_ 1323 TireLFTmp 1;
BA_REL_ "GenSigTimeoutMsg" BU_SG_REL_ ICCM_HS SG_ 1323 TireLFTmp 1323;
BA_REL_ "GenSigTimeoutTime" BU_SG_REL_ ICCM_HS SG_ 1323 TireLFTmp 2500;
BA_REL_ "GenSigSuprvResp" BU_SG_REL_ RDCM_HS SG_ 1323 TireLFTmp 1;
BA_REL_ "GenSigTimeoutMsg" BU_SG_REL_ RDCM_HS SG_ 1323 TireLFTmp 1323;
BA_REL_ "GenSigTimeoutTime" BU_SG_REL_ RDCM_HS SG_ 1323 TireLFTmp 2500;
BA_REL_ "GenSigSuprvResp" BU_SG_REL_ EBCM_OBD_HS SG_ 1323 TireRRTmp 1;
BA_REL_ "GenSigTimeoutMsg" BU_SG_REL_ EBCM_OBD_HS SG_ 1323 TireRRTmp 1323;
BA_REL_ "GenSigTimeoutTime" BU_SG_REL_ EBCM_OBD_HS SG_ 1323 TireRRTmp 2500;
BA_REL_ "GenSigSuprvResp" BU_SG_REL_ EBCM_HS SG_ 1323 TireRRTmp 1;
BA_REL_ "GenSigTimeoutMsg" BU_SG_REL_ EBCM_HS SG_ 1323 TireRRTmp 1323;
BA_REL_ "GenSigTimeoutTime" BU_SG_REL_ EBCM_HS SG_ 1323 TireRRTmp 2500;
BA_REL_ "GenSigSuprvResp" BU_SG_REL_ ICCM_OBD_HS SG_ 1323 TireRRTmp 1;
BA_REL_ "GenSigTimeoutMsg" BU_SG_REL_ ICCM_OBD_HS SG_ 1323 TireRRTmp 1323;
BA_REL_ "GenSigTimeoutTime" BU_SG_REL_ ICCM_OBD_HS SG_ 1323 TireRRTmp 2500;
BA_REL_ "GenSigSuprvResp" BU_SG_REL_ ICCM_HS SG_ 1323 TireRRTmp 1;
BA_REL_ "GenSigTimeoutMsg" BU_SG_REL_ ICCM_HS SG_ 1323 TireRRTmp 1323;
BA_REL_ "GenSigTimeoutTime" BU_SG_REL_ ICCM_HS SG_ 1323 TireRRTmp 2500;
BA_REL_ "GenSigSuprvResp" BU_SG_REL_ RDCM_HS SG_ 1323 TireRRTmp 1;
BA_REL_ "GenSigTimeoutMsg" BU_SG_REL_ RDCM_HS SG_ 1323 TireRRTmp 1323;
BA_REL_ "GenSigTimeoutTime" BU_SG_REL_ RDCM_HS SG_ 1323 TireRRTmp 2500;
BA_REL_ "GenSigSuprvResp" BU_SG_REL_ EBCM_OBD_HS SG_ 1323 TireRFTmp 1;
BA_REL_ "GenSigTimeoutMsg" BU_SG_REL_ EBCM_OBD_HS SG_ 1323 TireRFTmp 1323;
BA_REL_ "GenSigTimeoutTime" BU_SG_REL_ EBCM_OBD_HS SG_ 1323 TireRFTmp 2500;
BA_REL_ "GenSigSuprvResp" BU_SG_REL_ EBCM_HS SG_ 1323 TireRFTmp 1;
BA_REL_ "GenSigTimeoutMsg" BU_SG_REL_ EBCM_HS SG_ 1323 TireRFTmp 1323;
BA_REL_ "GenSigTimeoutTime" BU_SG_REL_ EBCM_HS SG_ 1323 TireRFTmp 2500;
BA_REL_ "GenSigSuprvResp" BU_SG_REL_ ICCM_OBD_HS SG_ 1323 TireRFTmp 1;
BA_REL_ "GenSigTimeoutMsg" BU_SG_REL_ ICCM_OBD_HS SG_ 1323 TireRFTmp 1323;
BA_REL_ "GenSigTimeoutTime" BU_SG_REL_ ICCM_OBD_HS SG_ 1323 TireRFTmp 2500;
BA_REL_ "GenSigSuprvResp" BU_SG_REL_ ICCM_HS SG_ 1323 TireRFTmp 1;
BA_REL_ "GenSigTimeoutMsg" BU_SG_REL_ ICCM_HS SG_ 1323 TireRFTmp 1323;
BA_REL_ "GenSigTimeoutTime" BU_SG_REL_ ICCM_HS SG_ 1323 TireRFTmp 2500;
BA_REL_ "GenSigSuprvResp" BU_SG_REL_ RDCM_HS SG_ 1323 TireRFTmp 1;
BA_REL_ "GenSigTimeoutMsg" BU_SG_REL_ RDCM_HS SG_ 1323 TireRFTmp 1323;
BA_REL_ "GenSigTimeoutTime" BU_SG_REL_ RDCM_HS SG_ 1323 TireRFTmp 2500;
BA_REL_ "GenSigSuprvResp" BU_SG_REL_ TCM_HS SG_ 1247 RrPTCoolFanStat 1;
BA_REL_ "GenSigTimeoutMsg" BU_SG_REL_ TCM_HS SG_ 1247 RrPTCoolFanStat 1247;
BA_REL_ "GenSigTimeoutTime" BU_SG_REL_ TCM_HS SG_ 1247 RrPTCoolFanStat 1250;
BA_REL_ "GenSigSuprvResp" BU_SG_REL_ TCM_HS SG_ 1247 RrPTCoolFanSpPctCmd 1;
BA_REL_ "GenSigTimeoutMsg" BU_SG_REL_ TCM_HS SG_ 1247 RrPTCoolFanSpPctCmd 1247;
BA_REL_ "GenSigTimeoutTime" BU_SG_REL_ TCM_HS SG_ 1247 RrPTCoolFanSpPctCmd 1250;
BA_REL_ "GenSigSuprvResp" BU_SG_REL_ FCM_HS SG_ 873 FrtCmModIntgStat 1;
BA_REL_ "GenSigTimeoutMsg" BU_SG_REL_ FCM_HS SG_ 873 FrtCmModIntgStat 873;
BA_REL_ "GenSigTimeoutTime" BU_SG_REL_ FCM_HS SG_ 873 FrtCmModIntgStat 250;
BA_REL_ "GenSigSuprvResp" BU_SG_REL_ FCM_HS SG_ 873 FrtCmModAsmt 1;
BA_REL_ "GenSigTimeoutMsg" BU_SG_REL_ FCM_HS SG_ 873 FrtCmModAsmt 873;
BA_REL_ "GenSigTimeoutTime" BU_SG_REL_ FCM_HS SG_ 873 FrtCmModAsmt 250;
BA_REL_ "GenSigSuprvResp" BU_SG_REL_ FCM_HS SG_ 873 ACCMR_RptdChlng 1;
BA_REL_ "GenSigTimeoutMsg" BU_SG_REL_ FCM_HS SG_ 873 ACCMR_RptdChlng 873;
BA_REL_ "GenSigTimeoutTime" BU_SG_REL_ FCM_HS SG_ 873 ACCMR_RptdChlng 250;
BA_REL_ "GenSigSuprvResp" BU_SG_REL_ FCM_HS SG_ 873 ACCMR_Answr 1;
BA_REL_ "GenSigTimeoutMsg" BU_SG_REL_ FCM_HS SG_ 873 ACCMR_Answr 873;
BA_REL_ "GenSigTimeoutTime" BU_SG_REL_ FCM_HS SG_ 873 ACCMR_Answr 250;
BA_REL_ "GenSigSuprvResp" BU_SG_REL_ FCM_HS SG_ 873 AdptCrsCtrlModChlng 1;
BA_REL_ "GenSigTimeoutMsg" BU_SG_REL_ FCM_HS SG_ 873 AdptCrsCtrlModChlng 873;
BA_REL_ "GenSigTimeoutTime" BU_SG_REL_ FCM_HS SG_ 873 AdptCrsCtrlModChlng 250;
BA_REL_ "GenSigSuprvResp" BU_SG_REL_ FICM_HS SG_ 405 ThrPos 1;
BA_REL_ "GenSigTimeoutMsg" BU_SG_REL_ FICM_HS SG_ 405 ThrPos 405;
BA_REL_ "GenSigTimeoutTime" BU_SG_REL_ FICM_HS SG_ 405 ThrPos 250;
BA_REL_ "GenSigSuprvResp" BU_SG_REL_ VCM_HS SG_ 405 MassAirFlo 1;
BA_REL_ "GenSigTimeoutMsg" BU_SG_REL_ VCM_HS SG_ 405 MassAirFlo 405;
BA_REL_ "GenSigTimeoutTime" BU_SG_REL_ VCM_HS SG_ 405 MassAirFlo 250;
BA_REL_ "GenSigSuprvResp" BU_SG_REL_ FICM_HS SG_ 405 MassAirFlo 1;
BA_REL_ "GenSigTimeoutMsg" BU_SG_REL_ FICM_HS SG_ 405 MassAirFlo 405;
BA_REL_ "GenSigTimeoutTime" BU_SG_REL_ FICM_HS SG_ 405 MassAirFlo 250;
BA_REL_ "GenSigSuprvResp" BU_SG_REL_ FICM_HS SG_ 405 EngManfldAbsPrsER 1;
BA_REL_ "GenSigTimeoutMsg" BU_SG_REL_ FICM_HS SG_ 405 EngManfldAbsPrsER 405;
BA_REL_ "GenSigTimeoutTime" BU_SG_REL_ FICM_HS SG_ 405 EngManfldAbsPrsER 250;
BA_REL_ "GenSigSuprvResp" BU_SG_REL_ HCP_B_HS SG_ 419 EngRunng 1;
BA_REL_ "GenSigTimeoutMsg" BU_SG_REL_ HCP_B_HS SG_ 419 EngRunng 419;
BA_REL_ "GenSigTimeoutTime" BU_SG_REL_ HCP_B_HS SG_ 419 EngRunng 250;
BA_REL_ "GenSigSuprvResp" BU_SG_REL_ HCP_T_HS SG_ 419 EngRunng 1;
BA_REL_ "GenSigTimeoutMsg" BU_SG_REL_ HCP_T_HS SG_ 419 EngRunng 419;
BA_REL_ "GenSigTimeoutTime" BU_SG_REL_ HCP_T_HS SG_ 419 EngRunng 250;
BA_REL_ "GenSigSuprvResp" BU_SG_REL_ BCM_HS SG_ 419 EngRunng 1;
BA_REL_ "GenSigTimeoutMsg" BU_SG_REL_ BCM_HS SG_ 419 EngRunng 419;
BA_REL_ "GenSigTimeoutTime" BU_SG_REL_ BCM_HS SG_ 419 EngRunng 250;
BA_REL_ "GenSigSuprvResp" BU_SG_REL_ DCDC_HS SG_ 419 EngRunng 1;
BA_REL_ "GenSigTimeoutMsg" BU_SG_REL_ DCDC_HS SG_ 419 EngRunng 419;
BA_REL_ "GenSigTimeoutTime" BU_SG_REL_ DCDC_HS SG_ 419 EngRunng 250;
BA_REL_ "GenSigSuprvResp" BU_SG_REL_ TCCM_HS SG_ 419 EngRunng 1;
BA_REL_ "GenSigTimeoutMsg" BU_SG_REL_ TCCM_HS SG_ 419 EngRunng 419;
BA_REL_ "GenSigTimeoutTime" BU_SG_REL_ TCCM_HS SG_ 419 EngRunng 250;
BA_REL_ "GenSigSuprvResp" BU_SG_REL_ Dummy_HS SG_ 289 ARDM_RawData 1;
BA_REL_ "GenSigTimeoutMsg" BU_SG_REL_ Dummy_HS SG_ 289 ARDM_RawData 289;
BA_REL_ "GenSigTimeoutTime" BU_SG_REL_ Dummy_HS SG_ 289 ARDM_RawData 250;
BA_REL_ "GenSigSuprvResp" BU_SG_REL_ Dummy_HS SG_ 289 ARDM_MsgType 1;
BA_REL_ "GenSigTimeoutMsg" BU_SG_REL_ Dummy_HS SG_ 289 ARDM_MsgType 289;
BA_REL_ "GenSigTimeoutTime" BU_SG_REL_ Dummy_HS SG_ 289 ARDM_MsgType 250;
BA_REL_ "GenSigSuprvResp" BU_SG_REL_ ACC_HS SG_ 871 ACCModIntgStat 1;
BA_REL_ "GenSigTimeoutMsg" BU_SG_REL_ ACC_HS SG_ 871 ACCModIntgStat 871;
BA_REL_ "GenSigTimeoutTime" BU_SG_REL_ ACC_HS SG_ 871 ACCModIntgStat 250;
BA_REL_ "GenSigSuprvResp" BU_SG_REL_ ACC_HS SG_ 871 AdptCrsCtrlModAsmt 1;
BA_REL_ "GenSigTimeoutMsg" BU_SG_REL_ ACC_HS SG_ 871 AdptCrsCtrlModAsmt 871;
BA_REL_ "GenSigTimeoutTime" BU_SG_REL_ ACC_HS SG_ 871 AdptCrsCtrlModAsmt 250;
BA_REL_ "GenSigSuprvResp" BU_SG_REL_ ACC_HS SG_ 871 FCMR_RptdChlng 1;
BA_REL_ "GenSigTimeoutMsg" BU_SG_REL_ ACC_HS SG_ 871 FCMR_RptdChlng 871;
BA_REL_ "GenSigTimeoutTime" BU_SG_REL_ ACC_HS SG_ 871 FCMR_RptdChlng 250;
BA_REL_ "GenSigSuprvResp" BU_SG_REL_ ACC_HS SG_ 871 FCMR_Answr 1;
BA_REL_ "GenSigTimeoutMsg" BU_SG_REL_ ACC_HS SG_ 871 FCMR_Answr 871;
BA_REL_ "GenSigTimeoutTime" BU_SG_REL_ ACC_HS SG_ 871 FCMR_Answr 250;
BA_REL_ "GenSigSuprvResp" BU_SG_REL_ ACC_HS SG_ 871 FrtCmModChlng 1;
BA_REL_ "GenSigTimeoutMsg" BU_SG_REL_ ACC_HS SG_ 871 FrtCmModChlng 871;
BA_REL_ "GenSigTimeoutTime" BU_SG_REL_ ACC_HS SG_ 871 FrtCmModChlng 250;
BA_REL_ "GenSigSuprvResp" BU_SG_REL_ EBCM_OBD_HS SG_ 800 FCACtrlBrkSysCmdPrtVl 1;
BA_REL_ "GenSigTimeoutMsg" BU_SG_REL_ EBCM_OBD_HS SG_ 800 FCACtrlBrkSysCmdPrtVl 800;
BA_REL_ "GenSigTimeoutTime" BU_SG_REL_ EBCM_OBD_HS SG_ 800 FCACtrlBrkSysCmdPrtVl 250;
BA_REL_ "GenSigSuprvResp" BU_SG_REL_ EBCM_HS SG_ 800 FCACtrlBrkSysCmdPrtVl 1;
BA_REL_ "GenSigTimeoutMsg" BU_SG_REL_ EBCM_HS SG_ 800 FCACtrlBrkSysCmdPrtVl 800;
BA_REL_ "GenSigTimeoutTime" BU_SG_REL_ EBCM_HS SG_ 800 FCACtrlBrkSysCmdPrtVl 250;
BA_REL_ "GenSigSuprvResp" BU_SG_REL_ EBCM_OBD_HS SG_ 800 FCACBSC_CtrlAcc 1;
BA_REL_ "GenSigTimeoutMsg" BU_SG_REL_ EBCM_OBD_HS SG_ 800 FCACBSC_CtrlAcc 800;
BA_REL_ "GenSigTimeoutTime" BU_SG_REL_ EBCM_OBD_HS SG_ 800 FCACBSC_CtrlAcc 250;
BA_REL_ "GenSigSuprvResp" BU_SG_REL_ EBCM_HS SG_ 800 FCACBSC_CtrlAcc 1;
BA_REL_ "GenSigTimeoutMsg" BU_SG_REL_ EBCM_HS SG_ 800 FCACBSC_CtrlAcc 800;
BA_REL_ "GenSigTimeoutTime" BU_SG_REL_ EBCM_HS SG_ 800 FCACBSC_CtrlAcc 250;
BA_REL_ "GenSigSuprvResp" BU_SG_REL_ EBCM_OBD_HS SG_ 800 FCACBSC_AutBrkRpRt 1;
BA_REL_ "GenSigTimeoutMsg" BU_SG_REL_ EBCM_OBD_HS SG_ 800 FCACBSC_AutBrkRpRt 800;
BA_REL_ "GenSigTimeoutTime" BU_SG_REL_ EBCM_OBD_HS SG_ 800 FCACBSC_AutBrkRpRt 250;
BA_REL_ "GenSigSuprvResp" BU_SG_REL_ EBCM_HS SG_ 800 FCACBSC_AutBrkRpRt 1;
BA_REL_ "GenSigTimeoutMsg" BU_SG_REL_ EBCM_HS SG_ 800 FCACBSC_AutBrkRpRt 800;
BA_REL_ "GenSigTimeoutTime" BU_SG_REL_ EBCM_HS SG_ 800 FCACBSC_AutBrkRpRt 250;
BA_REL_ "GenSigSuprvResp" BU_SG_REL_ EBCM_OBD_HS SG_ 800 FCACBSC_AutBrkRqTp 1;
BA_REL_ "GenSigTimeoutMsg" BU_SG_REL_ EBCM_OBD_HS SG_ 800 FCACBSC_AutBrkRqTp 800;
BA_REL_ "GenSigTimeoutTime" BU_SG_REL_ EBCM_OBD_HS SG_ 800 FCACBSC_AutBrkRqTp 250;
BA_REL_ "GenSigSuprvResp" BU_SG_REL_ EBCM_HS SG_ 800 FCACBSC_AutBrkRqTp 1;
BA_REL_ "GenSigTimeoutMsg" BU_SG_REL_ EBCM_HS SG_ 800 FCACBSC_AutBrkRqTp 800;
BA_REL_ "GenSigTimeoutTime" BU_SG_REL_ EBCM_HS SG_ 800 FCACBSC_AutBrkRqTp 250;
BA_REL_ "GenSigSuprvResp" BU_SG_REL_ EBCM_OBD_HS SG_ 800 FCACBSC_AutBrkRqd 1;
BA_REL_ "GenSigTimeoutMsg" BU_SG_REL_ EBCM_OBD_HS SG_ 800 FCACBSC_AutBrkRqd 800;
BA_REL_ "GenSigTimeoutTime" BU_SG_REL_ EBCM_OBD_HS SG_ 800 FCACBSC_AutBrkRqd 250;
BA_REL_ "GenSigSuprvResp" BU_SG_REL_ EBCM_HS SG_ 800 FCACBSC_AutBrkRqd 1;
BA_REL_ "GenSigTimeoutMsg" BU_SG_REL_ EBCM_HS SG_ 800 FCACBSC_AutBrkRqd 800;
BA_REL_ "GenSigTimeoutTime" BU_SG_REL_ EBCM_HS SG_ 800 FCACBSC_AutBrkRqd 250;
BA_REL_ "GenSigSuprvResp" BU_SG_REL_ EBCM_OBD_HS SG_ 800 FCACtrlBrkSysCmdRC 1;
BA_REL_ "GenSigTimeoutMsg" BU_SG_REL_ EBCM_OBD_HS SG_ 800 FCACtrlBrkSysCmdRC 800;
BA_REL_ "GenSigTimeoutTime" BU_SG_REL_ EBCM_OBD_HS SG_ 800 FCACtrlBrkSysCmdRC 250;
BA_REL_ "GenSigSuprvResp" BU_SG_REL_ EBCM_HS SG_ 800 FCACtrlBrkSysCmdRC 1;
BA_REL_ "GenSigTimeoutMsg" BU_SG_REL_ EBCM_HS SG_ 800 FCACtrlBrkSysCmdRC 800;
BA_REL_ "GenSigTimeoutTime" BU_SG_REL_ EBCM_HS SG_ 800 FCACtrlBrkSysCmdRC 250;
BA_REL_ "GenSigSuprvResp" BU_SG_REL_ CGM_HS SG_ 388 HndsOffStrWhlDtSt 1;
BA_REL_ "GenSigTimeoutMsg" BU_SG_REL_ CGM_HS SG_ 388 HndsOffStrWhlDtSt 388;
BA_REL_ "GenSigTimeoutTime" BU_SG_REL_ CGM_HS SG_ 388 HndsOffStrWhlDtSt 250;
BA_REL_ "GenSigSuprvResp" BU_SG_REL_ EOCM_F_HS SG_ 388 HndsOffStrWhlDtSt 1;
BA_REL_ "GenSigTimeoutMsg" BU_SG_REL_ EOCM_F_HS SG_ 388 HndsOffStrWhlDtSt 388;
BA_REL_ "GenSigTimeoutTime" BU_SG_REL_ EOCM_F_HS SG_ 388 HndsOffStrWhlDtSt 250;
BA_REL_ "GenSigSuprvResp" BU_SG_REL_ FCM_HS SG_ 388 HndsOffStrWhlDtSt 1;
BA_REL_ "GenSigTimeoutMsg" BU_SG_REL_ FCM_HS SG_ 388 HndsOffStrWhlDtSt 388;
BA_REL_ "GenSigTimeoutTime" BU_SG_REL_ FCM_HS SG_ 388 HndsOffStrWhlDtSt 250;
BA_REL_ "GenSigSuprvResp" BU_SG_REL_ CGM_HS SG_ 388 HndsOffStrWhlDtMd 1;
BA_REL_ "GenSigTimeoutMsg" BU_SG_REL_ CGM_HS SG_ 388 HndsOffStrWhlDtMd 388;
BA_REL_ "GenSigTimeoutTime" BU_SG_REL_ CGM_HS SG_ 388 HndsOffStrWhlDtMd 250;
BA_REL_ "GenSigSuprvResp" BU_SG_REL_ EOCM_F_HS SG_ 388 HndsOffStrWhlDtMd 1;
BA_REL_ "GenSigTimeoutMsg" BU_SG_REL_ EOCM_F_HS SG_ 388 HndsOffStrWhlDtMd 388;
BA_REL_ "GenSigTimeoutTime" BU_SG_REL_ EOCM_F_HS SG_ 388 HndsOffStrWhlDtMd 250;
BA_REL_ "GenSigSuprvResp" BU_SG_REL_ FCM_HS SG_ 388 HndsOffStrWhlDtMd 1;
BA_REL_ "GenSigTimeoutMsg" BU_SG_REL_ FCM_HS SG_ 388 HndsOffStrWhlDtMd 388;
BA_REL_ "GenSigTimeoutTime" BU_SG_REL_ FCM_HS SG_ 388 HndsOffStrWhlDtMd 250;
BA_REL_ "GenSigSuprvResp" BU_SG_REL_ EOCM_F_HS SG_ 388 LKATrqOvrlStatChksm 1;
BA_REL_ "GenSigTimeoutMsg" BU_SG_REL_ EOCM_F_HS SG_ 388 LKATrqOvrlStatChksm 388;
BA_REL_ "GenSigTimeoutTime" BU_SG_REL_ EOCM_F_HS SG_ 388 LKATrqOvrlStatChksm 250;
BA_REL_ "GenSigSuprvResp" BU_SG_REL_ FCM_HS SG_ 388 LKATrqOvrlStatChksm 1;
BA_REL_ "GenSigTimeoutMsg" BU_SG_REL_ FCM_HS SG_ 388 LKATrqOvrlStatChksm 388;
BA_REL_ "GenSigTimeoutTime" BU_SG_REL_ FCM_HS SG_ 388 LKATrqOvrlStatChksm 250;
BA_REL_ "GenSigSuprvResp" BU_SG_REL_ CGM_HS SG_ 388 LKATrqOvrlDltTrqDlvd 1;
BA_REL_ "GenSigTimeoutMsg" BU_SG_REL_ CGM_HS SG_ 388 LKATrqOvrlDltTrqDlvd 388;
BA_REL_ "GenSigTimeoutTime" BU_SG_REL_ CGM_HS SG_ 388 LKATrqOvrlDltTrqDlvd 250;
BA_REL_ "GenSigSuprvResp" BU_SG_REL_ EOCM_F_HS SG_ 388 LKATrqOvrlDltTrqDlvd 1;
BA_REL_ "GenSigTimeoutMsg" BU_SG_REL_ EOCM_F_HS SG_ 388 LKATrqOvrlDltTrqDlvd 388;
BA_REL_ "GenSigTimeoutTime" BU_SG_REL_ EOCM_F_HS SG_ 388 LKATrqOvrlDltTrqDlvd 250;
BA_REL_ "GenSigSuprvResp" BU_SG_REL_ FCM_HS SG_ 388 LKATrqOvrlDltTrqDlvd 1;
BA_REL_ "GenSigTimeoutMsg" BU_SG_REL_ FCM_HS SG_ 388 LKATrqOvrlDltTrqDlvd 388;
BA_REL_ "GenSigTimeoutTime" BU_SG_REL_ FCM_HS SG_ 388 LKATrqOvrlDltTrqDlvd 250;
BA_REL_ "GenSigSuprvResp" BU_SG_REL_ EOCM_F_HS SG_ 388 LKATrqOvrlDlvdRC 1;
BA_REL_ "GenSigTimeoutMsg" BU_SG_REL_ EOCM_F_HS SG_ 388 LKATrqOvrlDlvdRC 388;
BA_REL_ "GenSigTimeoutTime" BU_SG_REL_ EOCM_F_HS SG_ 388 LKATrqOvrlDlvdRC 250;
BA_REL_ "GenSigSuprvResp" BU_SG_REL_ FCM_HS SG_ 388 LKATrqOvrlDlvdRC 1;
BA_REL_ "GenSigTimeoutMsg" BU_SG_REL_ FCM_HS SG_ 388 LKATrqOvrlDlvdRC 388;
BA_REL_ "GenSigTimeoutTime" BU_SG_REL_ FCM_HS SG_ 388 LKATrqOvrlDlvdRC 250;
BA_REL_ "GenSigSuprvResp" BU_SG_REL_ CGM_HS SG_ 388 LKAElPwrStTtlTqDlvd 1;
BA_REL_ "GenSigTimeoutMsg" BU_SG_REL_ CGM_HS SG_ 388 LKAElPwrStTtlTqDlvd 388;
BA_REL_ "GenSigTimeoutTime" BU_SG_REL_ CGM_HS SG_ 388 LKAElPwrStTtlTqDlvd 250;
BA_REL_ "GenSigSuprvResp" BU_SG_REL_ EOCM_F_HS SG_ 388 LKAElPwrStTtlTqDlvd 1;
BA_REL_ "GenSigTimeoutMsg" BU_SG_REL_ EOCM_F_HS SG_ 388 LKAElPwrStTtlTqDlvd 388;
BA_REL_ "GenSigTimeoutTime" BU_SG_REL_ EOCM_F_HS SG_ 388 LKAElPwrStTtlTqDlvd 250;
BA_REL_ "GenSigSuprvResp" BU_SG_REL_ FCM_HS SG_ 388 LKAElPwrStTtlTqDlvd 1;
BA_REL_ "GenSigTimeoutMsg" BU_SG_REL_ FCM_HS SG_ 388 LKAElPwrStTtlTqDlvd 388;
BA_REL_ "GenSigTimeoutTime" BU_SG_REL_ FCM_HS SG_ 388 LKAElPwrStTtlTqDlvd 250;
BA_REL_ "GenSigSuprvResp" BU_SG_REL_ CGM_HS SG_ 388 LKATrqOvrlTrqDStat 1;
BA_REL_ "GenSigTimeoutMsg" BU_SG_REL_ CGM_HS SG_ 388 LKATrqOvrlTrqDStat 388;
BA_REL_ "GenSigTimeoutTime" BU_SG_REL_ CGM_HS SG_ 388 LKATrqOvrlTrqDStat 250;
BA_REL_ "GenSigSuprvResp" BU_SG_REL_ EOCM_F_HS SG_ 388 LKATrqOvrlTrqDStat 1;
BA_REL_ "GenSigTimeoutMsg" BU_SG_REL_ EOCM_F_HS SG_ 388 LKATrqOvrlTrqDStat 388;
BA_REL_ "GenSigTimeoutTime" BU_SG_REL_ EOCM_F_HS SG_ 388 LKATrqOvrlTrqDStat 250;
BA_REL_ "GenSigSuprvResp" BU_SG_REL_ FCM_HS SG_ 388 LKATrqOvrlTrqDStat 1;
BA_REL_ "GenSigTimeoutMsg" BU_SG_REL_ FCM_HS SG_ 388 LKATrqOvrlTrqDStat 388;
BA_REL_ "GenSigTimeoutTime" BU_SG_REL_ FCM_HS SG_ 388 LKATrqOvrlTrqDStat 250;
BA_REL_ "GenSigSuprvResp" BU_SG_REL_ CGM_HS SG_ 388 LKADrvAppldTrq 1;
BA_REL_ "GenSigTimeoutMsg" BU_SG_REL_ CGM_HS SG_ 388 LKADrvAppldTrq 388;
BA_REL_ "GenSigTimeoutTime" BU_SG_REL_ CGM_HS SG_ 388 LKADrvAppldTrq 250;
BA_REL_ "GenSigSuprvResp" BU_SG_REL_ EOCM_F_HS SG_ 388 LKADrvAppldTrq 1;
BA_REL_ "GenSigTimeoutMsg" BU_SG_REL_ EOCM_F_HS SG_ 388 LKADrvAppldTrq 388;
BA_REL_ "GenSigTimeoutTime" BU_SG_REL_ EOCM_F_HS SG_ 388 LKADrvAppldTrq 250;
BA_REL_ "GenSigSuprvResp" BU_SG_REL_ FCM_HS SG_ 388 LKADrvAppldTrq 1;
BA_REL_ "GenSigTimeoutMsg" BU_SG_REL_ FCM_HS SG_ 388 LKADrvAppldTrq 388;
BA_REL_ "GenSigTimeoutTime" BU_SG_REL_ FCM_HS SG_ 388 LKADrvAppldTrq 250;
BA_REL_ "GenSigSuprvResp" BU_SG_REL_ EPS_HS SG_ 384 LKATqOvrDltCmdPrtVl 1;
BA_REL_ "GenSigTimeoutMsg" BU_SG_REL_ EPS_HS SG_ 384 LKATqOvrDltCmdPrtVl 384;
BA_REL_ "GenSigTimeoutTime" BU_SG_REL_ EPS_HS SG_ 384 LKATqOvrDltCmdPrtVl 250;
BA_REL_ "GenSigSuprvResp" BU_SG_REL_ EPS_HS SG_ 384 LKATqOvrDltCmdRC 1;
BA_REL_ "GenSigTimeoutMsg" BU_SG_REL_ EPS_HS SG_ 384 LKATqOvrDltCmdRC 384;
BA_REL_ "GenSigTimeoutTime" BU_SG_REL_ EPS_HS SG_ 384 LKATqOvrDltCmdRC 250;
BA_REL_ "GenSigSuprvResp" BU_SG_REL_ BCM_HS SG_ 384 LKATODC_TrqVl 1;
BA_REL_ "GenSigTimeoutMsg" BU_SG_REL_ BCM_HS SG_ 384 LKATODC_TrqVl 384;
BA_REL_ "GenSigTimeoutTime" BU_SG_REL_ BCM_HS SG_ 384 LKATODC_TrqVl 250;
BA_REL_ "GenSigSuprvResp" BU_SG_REL_ EPS_HS SG_ 384 LKATODC_TrqVl 1;
BA_REL_ "GenSigTimeoutMsg" BU_SG_REL_ EPS_HS SG_ 384 LKATODC_TrqVl 384;
BA_REL_ "GenSigTimeoutTime" BU_SG_REL_ EPS_HS SG_ 384 LKATODC_TrqVl 250;
BA_REL_ "GenSigSuprvResp" BU_SG_REL_ BCM_HS SG_ 384 LKATODC_TrqRqAct 1;
BA_REL_ "GenSigTimeoutMsg" BU_SG_REL_ BCM_HS SG_ 384 LKATODC_TrqRqAct 384;
BA_REL_ "GenSigTimeoutTime" BU_SG_REL_ BCM_HS SG_ 384 LKATODC_TrqRqAct 250;
BA_REL_ "GenSigSuprvResp" BU_SG_REL_ EPS_HS SG_ 384 LKATODC_TrqRqAct 1;
BA_REL_ "GenSigTimeoutMsg" BU_SG_REL_ EPS_HS SG_ 384 LKATODC_TrqRqAct 384;
BA_REL_ "GenSigTimeoutTime" BU_SG_REL_ EPS_HS SG_ 384 LKATODC_TrqRqAct 250;
BA_REL_ "GenSigSuprvResp" BU_SG_REL_ BSM_HS SG_ 866 RegenBrkAxTrqAch 1;
BA_REL_ "GenSigTimeoutMsg" BU_SG_REL_ BSM_HS SG_ 866 RegenBrkAxTrqAch 866;
BA_REL_ "GenSigTimeoutTime" BU_SG_REL_ BSM_HS SG_ 866 RegenBrkAxTrqAch 250;
BA_REL_ "GenSigSuprvResp" BU_SG_REL_ VICM_HS SG_ 866 RegenBrkAxTrqAch 1;
BA_REL_ "GenSigTimeoutMsg" BU_SG_REL_ VICM_HS SG_ 866 RegenBrkAxTrqAch 866;
BA_REL_ "GenSigTimeoutTime" BU_SG_REL_ VICM_HS SG_ 866 RegenBrkAxTrqAch 250;
BA_REL_ "GenSigSuprvResp" BU_SG_REL_ BSM_HS SG_ 1223 EngSnPwrECoolLpTmp 1;
BA_REL_ "GenSigTimeoutMsg" BU_SG_REL_ BSM_HS SG_ 1223 EngSnPwrECoolLpTmp 1223;
BA_REL_ "GenSigTimeoutTime" BU_SG_REL_ BSM_HS SG_ 1223 EngSnPwrECoolLpTmp 1250;
BA_REL_ "GenSigSuprvResp" BU_SG_REL_ VICM_HS SG_ 1223 EngSnPwrECoolLpTmp 1;
BA_REL_ "GenSigTimeoutMsg" BU_SG_REL_ VICM_HS SG_ 1223 EngSnPwrECoolLpTmp 1223;
BA_REL_ "GenSigTimeoutTime" BU_SG_REL_ VICM_HS SG_ 1223 EngSnPwrECoolLpTmp 1250;
BA_REL_ "GenSigSuprvResp" BU_SG_REL_ HCP_B_HS SG_ 1223 PropSysOffTme 1;
BA_REL_ "GenSigTimeoutMsg" BU_SG_REL_ HCP_B_HS SG_ 1223 PropSysOffTme 1223;
BA_REL_ "GenSigTimeoutTime" BU_SG_REL_ HCP_B_HS SG_ 1223 PropSysOffTme 1250;
BA_REL_ "GenSigSuprvResp" BU_SG_REL_ BSM_HS SG_ 1223 PropSysOffTme 1;
BA_REL_ "GenSigTimeoutMsg" BU_SG_REL_ BSM_HS SG_ 1223 PropSysOffTme 1223;
BA_REL_ "GenSigTimeoutTime" BU_SG_REL_ BSM_HS SG_ 1223 PropSysOffTme 1250;
BA_REL_ "GenSigSuprvResp" BU_SG_REL_ HCP_T_HS SG_ 1223 PropSysOffTme 1;
BA_REL_ "GenSigTimeoutMsg" BU_SG_REL_ HCP_T_HS SG_ 1223 PropSysOffTme 1223;
BA_REL_ "GenSigTimeoutTime" BU_SG_REL_ HCP_T_HS SG_ 1223 PropSysOffTme 1250;
BA_REL_ "GenSigSuprvResp" BU_SG_REL_ HCP_T_HS SG_ 1223 PropSysOffTme 1;
BA_REL_ "GenSigTimeoutMsg" BU_SG_REL_ HCP_T_HS SG_ 1223 PropSysOffTme 1223;
BA_REL_ "GenSigTimeoutTime" BU_SG_REL_ HCP_T_HS SG_ 1223 PropSysOffTme 1250;
BA_REL_ "GenSigSuprvResp" BU_SG_REL_ VICM2_HS SG_ 1223 PropSysOffTme 1;
BA_REL_ "GenSigTimeoutMsg" BU_SG_REL_ VICM2_HS SG_ 1223 PropSysOffTme 1223;
BA_REL_ "GenSigTimeoutTime" BU_SG_REL_ VICM2_HS SG_ 1223 PropSysOffTme 1250;
BA_REL_ "GenSigSuprvResp" BU_SG_REL_ EBCM_OBD_HS SG_ 1223 PropSysOffTme 1;
BA_REL_ "GenSigTimeoutMsg" BU_SG_REL_ EBCM_OBD_HS SG_ 1223 PropSysOffTme 1223;
BA_REL_ "GenSigTimeoutTime" BU_SG_REL_ EBCM_OBD_HS SG_ 1223 PropSysOffTme 1250;
BA_REL_ "GenSigSuprvResp" BU_SG_REL_ EBCM_HS SG_ 1223 PropSysOffTme 1;
BA_REL_ "GenSigTimeoutMsg" BU_SG_REL_ EBCM_HS SG_ 1223 PropSysOffTme 1223;
BA_REL_ "GenSigTimeoutTime" BU_SG_REL_ EBCM_HS SG_ 1223 PropSysOffTme 1250;
BA_REL_ "GenSigSuprvResp" BU_SG_REL_ VICM_HS SG_ 1223 PropSysOffTme 1;
BA_REL_ "GenSigTimeoutMsg" BU_SG_REL_ VICM_HS SG_ 1223 PropSysOffTme 1223;
BA_REL_ "GenSigTimeoutTime" BU_SG_REL_ VICM_HS SG_ 1223 PropSysOffTme 1250;
BA_REL_ "GenSigSuprvResp" BU_SG_REL_ VICM_HS SG_ 1223 PropSysOffTme 1;
BA_REL_ "GenSigTimeoutMsg" BU_SG_REL_ VICM_HS SG_ 1223 PropSysOffTme 1223;
BA_REL_ "GenSigTimeoutTime" BU_SG_REL_ VICM_HS SG_ 1223 PropSysOffTme 1250;
BA_REL_ "GenSigSuprvResp" BU_SG_REL_ HCP_T_HS SG_ 1227 BattThrmlCondOffTme 1;
BA_REL_ "GenSigTimeoutMsg" BU_SG_REL_ HCP_T_HS SG_ 1227 BattThrmlCondOffTme 1227;
BA_REL_ "GenSigTimeoutTime" BU_SG_REL_ HCP_T_HS SG_ 1227 BattThrmlCondOffTme 1250;
BA_REL_ "GenSigSuprvResp" BU_SG_REL_ HCP_T_HS SG_ 1227 BattThrmlCondOffTme 1;
BA_REL_ "GenSigTimeoutMsg" BU_SG_REL_ HCP_T_HS SG_ 1227 BattThrmlCondOffTme 1227;
BA_REL_ "GenSigTimeoutTime" BU_SG_REL_ HCP_T_HS SG_ 1227 BattThrmlCondOffTme 1250;
BA_REL_ "GenSigSuprvResp" BU_SG_REL_ HCP_T_HS SG_ 1227 OffBrdChrgOffTme 1;
BA_REL_ "GenSigTimeoutMsg" BU_SG_REL_ HCP_T_HS SG_ 1227 OffBrdChrgOffTme 1227;
BA_REL_ "GenSigTimeoutTime" BU_SG_REL_ HCP_T_HS SG_ 1227 OffBrdChrgOffTme 1250;
BA_REL_ "GenSigSuprvResp" BU_SG_REL_ HCP_T_HS SG_ 1227 OffBrdChrgOffTme 1;
BA_REL_ "GenSigTimeoutMsg" BU_SG_REL_ HCP_T_HS SG_ 1227 OffBrdChrgOffTme 1227;
BA_REL_ "GenSigTimeoutTime" BU_SG_REL_ HCP_T_HS SG_ 1227 OffBrdChrgOffTme 1250;
BA_REL_ "GenSigSuprvResp" BU_SG_REL_ PTO_HS SG_ 543 PTOTpStpSpdCsStReq 1;
BA_REL_ "GenSigTimeoutMsg" BU_SG_REL_ PTO_HS SG_ 543 PTOTpStpSpdCsStReq 543;
BA_REL_ "GenSigTimeoutTime" BU_SG_REL_ PTO_HS SG_ 543 PTOTpStpSpdCsStReq 250;
BA_REL_ "GenSigSuprvResp" BU_SG_REL_ PTO_HS SG_ 543 PTOStdbySpdCsStReq 1;
BA_REL_ "GenSigTimeoutMsg" BU_SG_REL_ PTO_HS SG_ 543 PTOStdbySpdCsStReq 543;
BA_REL_ "GenSigTimeoutTime" BU_SG_REL_ PTO_HS SG_ 543 PTOStdbySpdCsStReq 250;
BA_REL_ "GenSigSuprvResp" BU_SG_REL_ PTO_HS SG_ 543 PTOEngRnTmrCsStRq 1;
BA_REL_ "GenSigTimeoutMsg" BU_SG_REL_ PTO_HS SG_ 543 PTOEngRnTmrCsStRq 543;
BA_REL_ "GenSigTimeoutTime" BU_SG_REL_ PTO_HS SG_ 543 PTOEngRnTmrCsStRq 250;
BA_REL_ "GenSigSuprvResp" BU_SG_REL_ PTO_HS SG_ 543 PTOSet2SpdCsStReq 1;
BA_REL_ "GenSigTimeoutMsg" BU_SG_REL_ PTO_HS SG_ 543 PTOSet2SpdCsStReq 543;
BA_REL_ "GenSigTimeoutTime" BU_SG_REL_ PTO_HS SG_ 543 PTOSet2SpdCsStReq 250;
BA_REL_ "GenSigSuprvResp" BU_SG_REL_ PTO_HS SG_ 543 PTOSet1SpdCsStReq 1;
BA_REL_ "GenSigTimeoutMsg" BU_SG_REL_ PTO_HS SG_ 543 PTOSet1SpdCsStReq 543;
BA_REL_ "GenSigTimeoutTime" BU_SG_REL_ PTO_HS SG_ 543 PTOSet1SpdCsStReq 250;
BA_REL_ "GenSigSuprvResp" BU_SG_REL_ BCM_HS SG_ 544 PTOMobModTrnsInGrIO 1;
BA_REL_ "GenSigTimeoutMsg" BU_SG_REL_ BCM_HS SG_ 544 PTOMobModTrnsInGrIO 544;
BA_REL_ "GenSigTimeoutTime" BU_SG_REL_ BCM_HS SG_ 544 PTOMobModTrnsInGrIO 625;
BA_REL_ "GenSigSuprvResp" BU_SG_REL_ BCM_HS SG_ 544 PTOManTransInGrIO 1;
BA_REL_ "GenSigTimeoutMsg" BU_SG_REL_ BCM_HS SG_ 544 PTOManTransInGrIO 544;
BA_REL_ "GenSigTimeoutTime" BU_SG_REL_ BCM_HS SG_ 544 PTOManTransInGrIO 625;
BA_REL_ "GenSigSuprvResp" BU_SG_REL_ BCM_HS SG_ 544 PTOServIndOn 1;
BA_REL_ "GenSigTimeoutMsg" BU_SG_REL_ BCM_HS SG_ 544 PTOServIndOn 544;
BA_REL_ "GenSigTimeoutTime" BU_SG_REL_ BCM_HS SG_ 544 PTOServIndOn 625;
BA_REL_ "GenSigSuprvResp" BU_SG_REL_ BCM_HS SG_ 544 PTOEngUpnBrkRelIO 1;
BA_REL_ "GenSigTimeoutMsg" BU_SG_REL_ BCM_HS SG_ 544 PTOEngUpnBrkRelIO 544;
BA_REL_ "GenSigTimeoutTime" BU_SG_REL_ BCM_HS SG_ 544 PTOEngUpnBrkRelIO 625;
BA_REL_ "GenSigSuprvResp" BU_SG_REL_ BCM_HS SG_ 544 PTOAccelUpnBrkRelIO 1;
BA_REL_ "GenSigTimeoutMsg" BU_SG_REL_ BCM_HS SG_ 544 PTOAccelUpnBrkRelIO 544;
BA_REL_ "GenSigTimeoutTime" BU_SG_REL_ BCM_HS SG_ 544 PTOAccelUpnBrkRelIO 625;
BA_REL_ "GenSigSuprvResp" BU_SG_REL_ BCM_HS SG_ 544 PTOAudExtAlertReq 1;
BA_REL_ "GenSigTimeoutMsg" BU_SG_REL_ BCM_HS SG_ 544 PTOAudExtAlertReq 544;
BA_REL_ "GenSigTimeoutTime" BU_SG_REL_ BCM_HS SG_ 544 PTOAudExtAlertReq 625;
BA_REL_ "GenSigSuprvResp" BU_SG_REL_ BCM_HS SG_ 544 PTOTransInGearIO 1;
BA_REL_ "GenSigTimeoutMsg" BU_SG_REL_ BCM_HS SG_ 544 PTOTransInGearIO 544;
BA_REL_ "GenSigTimeoutTime" BU_SG_REL_ BCM_HS SG_ 544 PTOTransInGearIO 625;
BA_REL_ "GenSigSuprvResp" BU_SG_REL_ BCM_HS SG_ 544 PTOTpStpSpdCsStAvl 1;
BA_REL_ "GenSigTimeoutMsg" BU_SG_REL_ BCM_HS SG_ 544 PTOTpStpSpdCsStAvl 544;
BA_REL_ "GenSigTimeoutTime" BU_SG_REL_ BCM_HS SG_ 544 PTOTpStpSpdCsStAvl 625;
BA_REL_ "GenSigSuprvResp" BU_SG_REL_ BCM_HS SG_ 544 PTOTpStSpdCsCrStVal 1;
BA_REL_ "GenSigTimeoutMsg" BU_SG_REL_ BCM_HS SG_ 544 PTOTpStSpdCsCrStVal 544;
BA_REL_ "GenSigTimeoutTime" BU_SG_REL_ BCM_HS SG_ 544 PTOTpStSpdCsCrStVal 625;
BA_REL_ "GenSigSuprvResp" BU_SG_REL_ BCM_HS SG_ 544 PTOStdbySpdCsStAvl 1;
BA_REL_ "GenSigTimeoutMsg" BU_SG_REL_ BCM_HS SG_ 544 PTOStdbySpdCsStAvl 544;
BA_REL_ "GenSigTimeoutTime" BU_SG_REL_ BCM_HS SG_ 544 PTOStdbySpdCsStAvl 625;
BA_REL_ "GenSigSuprvResp" BU_SG_REL_ BCM_HS SG_ 544 PTOStdbSpdCsCrStVal 1;
BA_REL_ "GenSigTimeoutMsg" BU_SG_REL_ BCM_HS SG_ 544 PTOStdbSpdCsCrStVal 544;
BA_REL_ "GenSigTimeoutTime" BU_SG_REL_ BCM_HS SG_ 544 PTOStdbSpdCsCrStVal 625;
BA_REL_ "GenSigSuprvResp" BU_SG_REL_ BCM_HS SG_ 544 PTOSetPrkBrkIO 1;
BA_REL_ "GenSigTimeoutMsg" BU_SG_REL_ BCM_HS SG_ 544 PTOSetPrkBrkIO 544;
BA_REL_ "GenSigTimeoutTime" BU_SG_REL_ BCM_HS SG_ 544 PTOSetPrkBrkIO 625;
BA_REL_ "GenSigSuprvResp" BU_SG_REL_ BCM_HS SG_ 544 PTOSet2SpdCsStAvl 1;
BA_REL_ "GenSigTimeoutMsg" BU_SG_REL_ BCM_HS SG_ 544 PTOSet2SpdCsStAvl 544;
BA_REL_ "GenSigTimeoutTime" BU_SG_REL_ BCM_HS SG_ 544 PTOSet2SpdCsStAvl 625;
BA_REL_ "GenSigSuprvResp" BU_SG_REL_ BCM_HS SG_ 544 PTOSet2SpdCsCrStVal 1;
BA_REL_ "GenSigTimeoutMsg" BU_SG_REL_ BCM_HS SG_ 544 PTOSet2SpdCsCrStVal 544;
BA_REL_ "GenSigTimeoutTime" BU_SG_REL_ BCM_HS SG_ 544 PTOSet2SpdCsCrStVal 625;
BA_REL_ "GenSigSuprvResp" BU_SG_REL_ BCM_HS SG_ 544 PTOSet1SpdCsStAvl 1;
BA_REL_ "GenSigTimeoutMsg" BU_SG_REL_ BCM_HS SG_ 544 PTOSet1SpdCsStAvl 544;
BA_REL_ "GenSigTimeoutTime" BU_SG_REL_ BCM_HS SG_ 544 PTOSet1SpdCsStAvl 625;
BA_REL_ "GenSigSuprvResp" BU_SG_REL_ BCM_HS SG_ 544 PTOSet1SpdCsCrStVal 1;
BA_REL_ "GenSigTimeoutMsg" BU_SG_REL_ BCM_HS SG_ 544 PTOSet1SpdCsCrStVal 544;
BA_REL_ "GenSigTimeoutTime" BU_SG_REL_ BCM_HS SG_ 544 PTOSet1SpdCsCrStVal 625;
BA_REL_ "GenSigSuprvResp" BU_SG_REL_ BCM_HS SG_ 544 PTORelCltPedIO 1;
BA_REL_ "GenSigTimeoutMsg" BU_SG_REL_ BCM_HS SG_ 544 PTORelCltPedIO 544;
BA_REL_ "GenSigTimeoutTime" BU_SG_REL_ BCM_HS SG_ 544 PTORelCltPedIO 625;
BA_REL_ "GenSigSuprvResp" BU_SG_REL_ BCM_HS SG_ 544 PTORelBrkPedIO 1;
BA_REL_ "GenSigTimeoutMsg" BU_SG_REL_ BCM_HS SG_ 544 PTORelBrkPedIO 544;
BA_REL_ "GenSigTimeoutTime" BU_SG_REL_ BCM_HS SG_ 544 PTORelBrkPedIO 625;
BA_REL_ "GenSigSuprvResp" BU_SG_REL_ BCM_HS SG_ 544 PTORelAccPedIO 1;
BA_REL_ "GenSigTimeoutMsg" BU_SG_REL_ BCM_HS SG_ 544 PTORelAccPedIO 544;
BA_REL_ "GenSigTimeoutTime" BU_SG_REL_ BCM_HS SG_ 544 PTORelAccPedIO 625;
BA_REL_ "GenSigSuprvResp" BU_SG_REL_ BCM_HS SG_ 544 PTORedEngSpdIO 1;
BA_REL_ "GenSigTimeoutMsg" BU_SG_REL_ BCM_HS SG_ 544 PTORedEngSpdIO 544;
BA_REL_ "GenSigTimeoutTime" BU_SG_REL_ BCM_HS SG_ 544 PTORedEngSpdIO 625;
BA_REL_ "GenSigSuprvResp" BU_SG_REL_ BCM_HS SG_ 544 PTOPrsRelCltPedIO 1;
BA_REL_ "GenSigTimeoutMsg" BU_SG_REL_ BCM_HS SG_ 544 PTOPrsRelCltPedIO 544;
BA_REL_ "GenSigTimeoutTime" BU_SG_REL_ BCM_HS SG_ 544 PTOPrsRelCltPedIO 625;
BA_REL_ "GenSigSuprvResp" BU_SG_REL_ BCM_HS SG_ 544 PTOPrsRelBrkPedIO 1;
BA_REL_ "GenSigTimeoutMsg" BU_SG_REL_ BCM_HS SG_ 544 PTOPrsRelBrkPedIO 544;
BA_REL_ "GenSigTimeoutTime" BU_SG_REL_ BCM_HS SG_ 544 PTOPrsRelBrkPedIO 625;
BA_REL_ "GenSigSuprvResp" BU_SG_REL_ BCM_HS SG_ 544 PTOEngRnTmrCsStAvl 1;
BA_REL_ "GenSigTimeoutMsg" BU_SG_REL_ BCM_HS SG_ 544 PTOEngRnTmrCsStAvl 544;
BA_REL_ "GenSigTimeoutTime" BU_SG_REL_ BCM_HS SG_ 544 PTOEngRnTmrCsStAvl 625;
BA_REL_ "GenSigSuprvResp" BU_SG_REL_ BCM_HS SG_ 544 PTOEnRnTmCsCrStVal 1;
BA_REL_ "GenSigTimeoutMsg" BU_SG_REL_ BCM_HS SG_ 544 PTOEnRnTmCsCrStVal 544;
BA_REL_ "GenSigTimeoutTime" BU_SG_REL_ BCM_HS SG_ 544 PTOEnRnTmCsCrStVal 625;
BA_REL_ "GenSigSuprvResp" BU_SG_REL_ BCM_HS SG_ 544 PTOEngmntStatInd 1;
BA_REL_ "GenSigTimeoutMsg" BU_SG_REL_ BCM_HS SG_ 544 PTOEngmntStatInd 544;
BA_REL_ "GenSigTimeoutTime" BU_SG_REL_ BCM_HS SG_ 544 PTOEngmntStatInd 625;
BA_REL_ "GenSigSuprvResp" BU_SG_REL_ BCM_HS SG_ 544 PTODisengCrsCntlIO 1;
BA_REL_ "GenSigTimeoutMsg" BU_SG_REL_ BCM_HS SG_ 544 PTODisengCrsCntlIO 544;
BA_REL_ "GenSigTimeoutTime" BU_SG_REL_ BCM_HS SG_ 544 PTODisengCrsCntlIO 625;
BA_REL_ "GenSigSuprvResp" BU_SG_REL_ HCP_HS SG_ 901 TrnsMtrBCoolFlwEst 1;
BA_REL_ "GenSigTimeoutMsg" BU_SG_REL_ HCP_HS SG_ 901 TrnsMtrBCoolFlwEst 901;
BA_REL_ "GenSigTimeoutTime" BU_SG_REL_ HCP_HS SG_ 901 TrnsMtrBCoolFlwEst 250;
BA_REL_ "GenSigSuprvResp" BU_SG_REL_ HCP_HS SG_ 901 TrnsMtrACoolFlwEst 1;
BA_REL_ "GenSigTimeoutMsg" BU_SG_REL_ HCP_HS SG_ 901 TrnsMtrACoolFlwEst 901;
BA_REL_ "GenSigTimeoutTime" BU_SG_REL_ HCP_HS SG_ 901 TrnsMtrACoolFlwEst 250;
BA_REL_ "GenSigSuprvResp" BU_SG_REL_ HCP_HS SG_ 901 TrnsLubeFlwEst 1;
BA_REL_ "GenSigTimeoutMsg" BU_SG_REL_ HCP_HS SG_ 901 TrnsLubeFlwEst 901;
BA_REL_ "GenSigTimeoutTime" BU_SG_REL_ HCP_HS SG_ 901 TrnsLubeFlwEst 250;
BA_REL_ "GenSigSuprvResp" BU_SG_REL_ AHL_AFL_HS SG_ 1032 RdTyp 1;
BA_REL_ "GenSigTimeoutMsg" BU_SG_REL_ AHL_AFL_HS SG_ 1032 RdTyp 1032;
BA_REL_ "GenSigTimeoutTime" BU_SG_REL_ AHL_AFL_HS SG_ 1032 RdTyp 250;
BA_REL_ "GenSigSuprvResp" BU_SG_REL_ AHL_AFL_HS SG_ 1032 FwdCamSysOpStat 1;
BA_REL_ "GenSigTimeoutMsg" BU_SG_REL_ AHL_AFL_HS SG_ 1032 FwdCamSysOpStat 1032;
BA_REL_ "GenSigTimeoutTime" BU_SG_REL_ AHL_AFL_HS SG_ 1032 FwdCamSysOpStat 250;
BA_REL_ "GenSigSuprvResp" BU_SG_REL_ AHL_AFL_HS SG_ 1032 EnvIllum 1;
BA_REL_ "GenSigTimeoutMsg" BU_SG_REL_ AHL_AFL_HS SG_ 1032 EnvIllum 1032;
BA_REL_ "GenSigTimeoutTime" BU_SG_REL_ AHL_AFL_HS SG_ 1032 EnvIllum 250;
BA_REL_ "GenSigSuprvResp" BU_SG_REL_ AHL_AFL_HS SG_ 1032 AutoHgBmSts 1;
BA_REL_ "GenSigTimeoutMsg" BU_SG_REL_ AHL_AFL_HS SG_ 1032 AutoHgBmSts 1032;
BA_REL_ "GenSigTimeoutTime" BU_SG_REL_ AHL_AFL_HS SG_ 1032 AutoHgBmSts 250;
BA_REL_ "GenSigSuprvResp" BU_SG_REL_ AHL_AFL_HS SG_ 1031 GFHBFwVsnWidthTrk8 1;
BA_REL_ "GenSigTimeoutMsg" BU_SG_REL_ AHL_AFL_HS SG_ 1031 GFHBFwVsnWidthTrk8 1031;
BA_REL_ "GenSigTimeoutTime" BU_SG_REL_ AHL_AFL_HS SG_ 1031 GFHBFwVsnWidthTrk8 250;
BA_REL_ "GenSigSuprvResp" BU_SG_REL_ AHL_AFL_HS SG_ 1031 GFHBFwVsnVertPosTrk8 1;
BA_REL_ "GenSigTimeoutMsg" BU_SG_REL_ AHL_AFL_HS SG_ 1031 GFHBFwVsnVertPosTrk8 1031;
BA_REL_ "GenSigTimeoutTime" BU_SG_REL_ AHL_AFL_HS SG_ 1031 GFHBFwVsnVertPosTrk8 250;
BA_REL_ "GenSigSuprvResp" BU_SG_REL_ AHL_AFL_HS SG_ 1031 GFHBFwVsnRelLaneTrk8 1;
BA_REL_ "GenSigTimeoutMsg" BU_SG_REL_ AHL_AFL_HS SG_ 1031 GFHBFwVsnRelLaneTrk8 1031;
BA_REL_ "GenSigTimeoutTime" BU_SG_REL_ AHL_AFL_HS SG_ 1031 GFHBFwVsnRelLaneTrk8 250;
BA_REL_ "GenSigSuprvResp" BU_SG_REL_ AHL_AFL_HS SG_ 1031 GFHBFwVsnAzmthRtTrk8 1;
BA_REL_ "GenSigTimeoutMsg" BU_SG_REL_ AHL_AFL_HS SG_ 1031 GFHBFwVsnAzmthRtTrk8 1031;
BA_REL_ "GenSigTimeoutTime" BU_SG_REL_ AHL_AFL_HS SG_ 1031 GFHBFwVsnAzmthRtTrk8 250;
BA_REL_ "GenSigSuprvResp" BU_SG_REL_ AHL_AFL_HS SG_ 1031 GFHBFwVsnCnfdncTrk8 1;
BA_REL_ "GenSigTimeoutMsg" BU_SG_REL_ AHL_AFL_HS SG_ 1031 GFHBFwVsnCnfdncTrk8 1031;
BA_REL_ "GenSigTimeoutTime" BU_SG_REL_ AHL_AFL_HS SG_ 1031 GFHBFwVsnCnfdncTrk8 250;
BA_REL_ "GenSigSuprvResp" BU_SG_REL_ AHL_AFL_HS SG_ 1031 GFHBFwVsnRngTrkRev8 1;
BA_REL_ "GenSigTimeoutMsg" BU_SG_REL_ AHL_AFL_HS SG_ 1031 GFHBFwVsnRngTrkRev8 1031;
BA_REL_ "GenSigTimeoutTime" BU_SG_REL_ AHL_AFL_HS SG_ 1031 GFHBFwVsnRngTrkRev8 250;
BA_REL_ "GenSigSuprvResp" BU_SG_REL_ AHL_AFL_HS SG_ 1031 GFHBFwVsnAzmthTrkRev8 1;
BA_REL_ "GenSigTimeoutMsg" BU_SG_REL_ AHL_AFL_HS SG_ 1031 GFHBFwVsnAzmthTrkRev8 1031;
BA_REL_ "GenSigTimeoutTime" BU_SG_REL_ AHL_AFL_HS SG_ 1031 GFHBFwVsnAzmthTrkRev8 250;
BA_REL_ "GenSigSuprvResp" BU_SG_REL_ AHL_AFL_HS SG_ 1031 GFHBFVsnObjTypTrkRev8 1;
BA_REL_ "GenSigTimeoutMsg" BU_SG_REL_ AHL_AFL_HS SG_ 1031 GFHBFVsnObjTypTrkRev8 1031;
BA_REL_ "GenSigTimeoutTime" BU_SG_REL_ AHL_AFL_HS SG_ 1031 GFHBFVsnObjTypTrkRev8 250;
BA_REL_ "GenSigSuprvResp" BU_SG_REL_ AHL_AFL_HS SG_ 1031 GFHBObjDirTrk8 1;
BA_REL_ "GenSigTimeoutMsg" BU_SG_REL_ AHL_AFL_HS SG_ 1031 GFHBObjDirTrk8 1031;
BA_REL_ "GenSigTimeoutTime" BU_SG_REL_ AHL_AFL_HS SG_ 1031 GFHBObjDirTrk8 250;
BA_REL_ "GenSigSuprvResp" BU_SG_REL_ AHL_AFL_HS SG_ 1031 GFHBFwVsnMesStatTrk8 1;
BA_REL_ "GenSigTimeoutMsg" BU_SG_REL_ AHL_AFL_HS SG_ 1031 GFHBFwVsnMesStatTrk8 1031;
BA_REL_ "GenSigTimeoutTime" BU_SG_REL_ AHL_AFL_HS SG_ 1031 GFHBFwVsnMesStatTrk8 250;
BA_REL_ "GenSigSuprvResp" BU_SG_REL_ AHL_AFL_HS SG_ 1031 GFHBFwVsnObjIDTrk8 1;
BA_REL_ "GenSigTimeoutMsg" BU_SG_REL_ AHL_AFL_HS SG_ 1031 GFHBFwVsnObjIDTrk8 1031;
BA_REL_ "GenSigTimeoutTime" BU_SG_REL_ AHL_AFL_HS SG_ 1031 GFHBFwVsnObjIDTrk8 250;
BA_REL_ "GenSigSuprvResp" BU_SG_REL_ AHL_AFL_HS SG_ 1030 GFHBFwVsnWidthTrk7 1;
BA_REL_ "GenSigTimeoutMsg" BU_SG_REL_ AHL_AFL_HS SG_ 1030 GFHBFwVsnWidthTrk7 1030;
BA_REL_ "GenSigTimeoutTime" BU_SG_REL_ AHL_AFL_HS SG_ 1030 GFHBFwVsnWidthTrk7 250;
BA_REL_ "GenSigSuprvResp" BU_SG_REL_ AHL_AFL_HS SG_ 1030 GFHBFwVsnVertPosTrk7 1;
BA_REL_ "GenSigTimeoutMsg" BU_SG_REL_ AHL_AFL_HS SG_ 1030 GFHBFwVsnVertPosTrk7 1030;
BA_REL_ "GenSigTimeoutTime" BU_SG_REL_ AHL_AFL_HS SG_ 1030 GFHBFwVsnVertPosTrk7 250;
BA_REL_ "GenSigSuprvResp" BU_SG_REL_ AHL_AFL_HS SG_ 1030 GFHBFwVsnRelLaneTrk7 1;
BA_REL_ "GenSigTimeoutMsg" BU_SG_REL_ AHL_AFL_HS SG_ 1030 GFHBFwVsnRelLaneTrk7 1030;
BA_REL_ "GenSigTimeoutTime" BU_SG_REL_ AHL_AFL_HS SG_ 1030 GFHBFwVsnRelLaneTrk7 250;
BA_REL_ "GenSigSuprvResp" BU_SG_REL_ AHL_AFL_HS SG_ 1030 GFHBFwVsnAzmthRtTrk7 1;
BA_REL_ "GenSigTimeoutMsg" BU_SG_REL_ AHL_AFL_HS SG_ 1030 GFHBFwVsnAzmthRtTrk7 1030;
BA_REL_ "GenSigTimeoutTime" BU_SG_REL_ AHL_AFL_HS SG_ 1030 GFHBFwVsnAzmthRtTrk7 250;
BA_REL_ "GenSigSuprvResp" BU_SG_REL_ AHL_AFL_HS SG_ 1030 GFHBFwVsnCnfdncTrk7 1;
BA_REL_ "GenSigTimeoutMsg" BU_SG_REL_ AHL_AFL_HS SG_ 1030 GFHBFwVsnCnfdncTrk7 1030;
BA_REL_ "GenSigTimeoutTime" BU_SG_REL_ AHL_AFL_HS SG_ 1030 GFHBFwVsnCnfdncTrk7 250;
BA_REL_ "GenSigSuprvResp" BU_SG_REL_ AHL_AFL_HS SG_ 1030 GFHBFwVsnRngTrkRev7 1;
BA_REL_ "GenSigTimeoutMsg" BU_SG_REL_ AHL_AFL_HS SG_ 1030 GFHBFwVsnRngTrkRev7 1030;
BA_REL_ "GenSigTimeoutTime" BU_SG_REL_ AHL_AFL_HS SG_ 1030 GFHBFwVsnRngTrkRev7 250;
BA_REL_ "GenSigSuprvResp" BU_SG_REL_ AHL_AFL_HS SG_ 1030 GFHBFwVsnAzmthTrkRev7 1;
BA_REL_ "GenSigTimeoutMsg" BU_SG_REL_ AHL_AFL_HS SG_ 1030 GFHBFwVsnAzmthTrkRev7 1030;
BA_REL_ "GenSigTimeoutTime" BU_SG_REL_ AHL_AFL_HS SG_ 1030 GFHBFwVsnAzmthTrkRev7 250;
BA_REL_ "GenSigSuprvResp" BU_SG_REL_ AHL_AFL_HS SG_ 1030 GFHBFVsnObjTypTrkRev7 1;
BA_REL_ "GenSigTimeoutMsg" BU_SG_REL_ AHL_AFL_HS SG_ 1030 GFHBFVsnObjTypTrkRev7 1030;
BA_REL_ "GenSigTimeoutTime" BU_SG_REL_ AHL_AFL_HS SG_ 1030 GFHBFVsnObjTypTrkRev7 250;
BA_REL_ "GenSigSuprvResp" BU_SG_REL_ AHL_AFL_HS SG_ 1030 GFHBObjDirTrk7 1;
BA_REL_ "GenSigTimeoutMsg" BU_SG_REL_ AHL_AFL_HS SG_ 1030 GFHBObjDirTrk7 1030;
BA_REL_ "GenSigTimeoutTime" BU_SG_REL_ AHL_AFL_HS SG_ 1030 GFHBObjDirTrk7 250;
BA_REL_ "GenSigSuprvResp" BU_SG_REL_ AHL_AFL_HS SG_ 1030 GFHBFwVsnMesStatTrk7 1;
BA_REL_ "GenSigTimeoutMsg" BU_SG_REL_ AHL_AFL_HS SG_ 1030 GFHBFwVsnMesStatTrk7 1030;
BA_REL_ "GenSigTimeoutTime" BU_SG_REL_ AHL_AFL_HS SG_ 1030 GFHBFwVsnMesStatTrk7 250;
BA_REL_ "GenSigSuprvResp" BU_SG_REL_ AHL_AFL_HS SG_ 1030 GFHBFwVsnObjIDTrk7 1;
BA_REL_ "GenSigTimeoutMsg" BU_SG_REL_ AHL_AFL_HS SG_ 1030 GFHBFwVsnObjIDTrk7 1030;
BA_REL_ "GenSigTimeoutTime" BU_SG_REL_ AHL_AFL_HS SG_ 1030 GFHBFwVsnObjIDTrk7 250;
BA_REL_ "GenSigSuprvResp" BU_SG_REL_ TCM_HS SG_ 479 EngAutoStpNotProb 1;
BA_REL_ "GenSigTimeoutMsg" BU_SG_REL_ TCM_HS SG_ 479 EngAutoStpNotProb 479;
BA_REL_ "GenSigTimeoutTime" BU_SG_REL_ TCM_HS SG_ 479 EngAutoStpNotProb 250;
BA_REL_ "GenSigSuprvResp" BU_SG_REL_ ECM_HS SG_ 479 EngAutoStpNotProb 1;
BA_REL_ "GenSigTimeoutMsg" BU_SG_REL_ ECM_HS SG_ 479 EngAutoStpNotProb 479;
BA_REL_ "GenSigTimeoutTime" BU_SG_REL_ ECM_HS SG_ 479 EngAutoStpNotProb 250;
BA_REL_ "GenSigSuprvResp" BU_SG_REL_ BCM_HS SG_ 479 EngAutoStpNotProb 1;
BA_REL_ "GenSigTimeoutMsg" BU_SG_REL_ BCM_HS SG_ 479 EngAutoStpNotProb 479;
BA_REL_ "GenSigTimeoutTime" BU_SG_REL_ BCM_HS SG_ 479 EngAutoStpNotProb 250;
BA_REL_ "GenSigSuprvResp" BU_SG_REL_ TCM_HS SG_ 479 EASSI_UnsdRsrvd2 1;
BA_REL_ "GenSigTimeoutMsg" BU_SG_REL_ TCM_HS SG_ 479 EASSI_UnsdRsrvd2 479;
BA_REL_ "GenSigTimeoutTime" BU_SG_REL_ TCM_HS SG_ 479 EASSI_UnsdRsrvd2 250;
BA_REL_ "GenSigSuprvResp" BU_SG_REL_ ECM_HS SG_ 479 EASSI_UnsdRsrvd2 1;
BA_REL_ "GenSigTimeoutMsg" BU_SG_REL_ ECM_HS SG_ 479 EASSI_UnsdRsrvd2 479;
BA_REL_ "GenSigTimeoutTime" BU_SG_REL_ ECM_HS SG_ 479 EASSI_UnsdRsrvd2 250;
BA_REL_ "GenSigSuprvResp" BU_SG_REL_ BCM_HS SG_ 479 EASSI_UnsdRsrvd2 1;
BA_REL_ "GenSigTimeoutMsg" BU_SG_REL_ BCM_HS SG_ 479 EASSI_UnsdRsrvd2 479;
BA_REL_ "GenSigTimeoutTime" BU_SG_REL_ BCM_HS SG_ 479 EASSI_UnsdRsrvd2 250;
BA_REL_ "GenSigSuprvResp" BU_SG_REL_ EBCM_OBD_HS SG_ 479 EASSI_UnsdRsrvd2 1;
BA_REL_ "GenSigTimeoutMsg" BU_SG_REL_ EBCM_OBD_HS SG_ 479 EASSI_UnsdRsrvd2 479;
BA_REL_ "GenSigTimeoutTime" BU_SG_REL_ EBCM_OBD_HS SG_ 479 EASSI_UnsdRsrvd2 250;
BA_REL_ "GenSigSuprvResp" BU_SG_REL_ EBCM_HS SG_ 479 EASSI_UnsdRsrvd2 1;
BA_REL_ "GenSigTimeoutMsg" BU_SG_REL_ EBCM_HS SG_ 479 EASSI_UnsdRsrvd2 479;
BA_REL_ "GenSigTimeoutTime" BU_SG_REL_ EBCM_HS SG_ 479 EASSI_UnsdRsrvd2 250;
BA_REL_ "GenSigSuprvResp" BU_SG_REL_ TCM_HS SG_ 479 EASSI_StlDetd 1;
BA_REL_ "GenSigTimeoutMsg" BU_SG_REL_ TCM_HS SG_ 479 EASSI_StlDetd 479;
BA_REL_ "GenSigTimeoutTime" BU_SG_REL_ TCM_HS SG_ 479 EASSI_StlDetd 250;
BA_REL_ "GenSigSuprvResp" BU_SG_REL_ ECM_HS SG_ 479 EASSI_StlDetd 1;
BA_REL_ "GenSigTimeoutMsg" BU_SG_REL_ ECM_HS SG_ 479 EASSI_StlDetd 479;
BA_REL_ "GenSigTimeoutTime" BU_SG_REL_ ECM_HS SG_ 479 EASSI_StlDetd 250;
BA_REL_ "GenSigSuprvResp" BU_SG_REL_ BCM_HS SG_ 479 EASSI_StlDetd 1;
BA_REL_ "GenSigTimeoutMsg" BU_SG_REL_ BCM_HS SG_ 479 EASSI_StlDetd 479;
BA_REL_ "GenSigTimeoutTime" BU_SG_REL_ BCM_HS SG_ 479 EASSI_StlDetd 250;
BA_REL_ "GenSigSuprvResp" BU_SG_REL_ EBCM_OBD_HS SG_ 479 EASSI_StlDetd 1;
BA_REL_ "GenSigTimeoutMsg" BU_SG_REL_ EBCM_OBD_HS SG_ 479 EASSI_StlDetd 479;
BA_REL_ "GenSigTimeoutTime" BU_SG_REL_ EBCM_OBD_HS SG_ 479 EASSI_StlDetd 250;
BA_REL_ "GenSigSuprvResp" BU_SG_REL_ EBCM_HS SG_ 479 EASSI_StlDetd 1;
BA_REL_ "GenSigTimeoutMsg" BU_SG_REL_ EBCM_HS SG_ 479 EASSI_StlDetd 479;
BA_REL_ "GenSigTimeoutTime" BU_SG_REL_ EBCM_HS SG_ 479 EASSI_StlDetd 250;
BA_REL_ "GenSigSuprvResp" BU_SG_REL_ TCM_HS SG_ 479 EASSI_TrqDetd 1;
BA_REL_ "GenSigTimeoutMsg" BU_SG_REL_ TCM_HS SG_ 479 EASSI_TrqDetd 479;
BA_REL_ "GenSigTimeoutTime" BU_SG_REL_ TCM_HS SG_ 479 EASSI_TrqDetd 250;
BA_REL_ "GenSigSuprvResp" BU_SG_REL_ ECM_HS SG_ 479 EASSI_TrqDetd 1;
BA_REL_ "GenSigTimeoutMsg" BU_SG_REL_ ECM_HS SG_ 479 EASSI_TrqDetd 479;
BA_REL_ "GenSigTimeoutTime" BU_SG_REL_ ECM_HS SG_ 479 EASSI_TrqDetd 250;
BA_REL_ "GenSigSuprvResp" BU_SG_REL_ BCM_HS SG_ 479 EASSI_TrqDetd 1;
BA_REL_ "GenSigTimeoutMsg" BU_SG_REL_ BCM_HS SG_ 479 EASSI_TrqDetd 479;
BA_REL_ "GenSigTimeoutTime" BU_SG_REL_ BCM_HS SG_ 479 EASSI_TrqDetd 250;
BA_REL_ "GenSigSuprvResp" BU_SG_REL_ EBCM_OBD_HS SG_ 479 EASSI_TrqDetd 1;
BA_REL_ "GenSigTimeoutMsg" BU_SG_REL_ EBCM_OBD_HS SG_ 479 EASSI_TrqDetd 479;
BA_REL_ "GenSigTimeoutTime" BU_SG_REL_ EBCM_OBD_HS SG_ 479 EASSI_TrqDetd 250;
BA_REL_ "GenSigSuprvResp" BU_SG_REL_ EBCM_HS SG_ 479 EASSI_TrqDetd 1;
BA_REL_ "GenSigTimeoutMsg" BU_SG_REL_ EBCM_HS SG_ 479 EASSI_TrqDetd 479;
BA_REL_ "GenSigTimeoutTime" BU_SG_REL_ EBCM_HS SG_ 479 EASSI_TrqDetd 250;
BA_REL_ "GenSigSuprvResp" BU_SG_REL_ TCM_HS SG_ 479 EASSI_FuelReqOn 1;
BA_REL_ "GenSigTimeoutMsg" BU_SG_REL_ TCM_HS SG_ 479 EASSI_FuelReqOn 479;
BA_REL_ "GenSigTimeoutTime" BU_SG_REL_ TCM_HS SG_ 479 EASSI_FuelReqOn 250;
BA_REL_ "GenSigSuprvResp" BU_SG_REL_ ECM_HS SG_ 479 EASSI_FuelReqOn 1;
BA_REL_ "GenSigTimeoutMsg" BU_SG_REL_ ECM_HS SG_ 479 EASSI_FuelReqOn 479;
BA_REL_ "GenSigTimeoutTime" BU_SG_REL_ ECM_HS SG_ 479 EASSI_FuelReqOn 250;
BA_REL_ "GenSigSuprvResp" BU_SG_REL_ BCM_HS SG_ 479 EASSI_FuelReqOn 1;
BA_REL_ "GenSigTimeoutMsg" BU_SG_REL_ BCM_HS SG_ 479 EASSI_FuelReqOn 479;
BA_REL_ "GenSigTimeoutTime" BU_SG_REL_ BCM_HS SG_ 479 EASSI_FuelReqOn 250;
BA_REL_ "GenSigSuprvResp" BU_SG_REL_ EBCM_OBD_HS SG_ 479 EASSI_FuelReqOn 1;
BA_REL_ "GenSigTimeoutMsg" BU_SG_REL_ EBCM_OBD_HS SG_ 479 EASSI_FuelReqOn 479;
BA_REL_ "GenSigTimeoutTime" BU_SG_REL_ EBCM_OBD_HS SG_ 479 EASSI_FuelReqOn 250;
BA_REL_ "GenSigSuprvResp" BU_SG_REL_ EBCM_HS SG_ 479 EASSI_FuelReqOn 1;
BA_REL_ "GenSigTimeoutMsg" BU_SG_REL_ EBCM_HS SG_ 479 EASSI_FuelReqOn 479;
BA_REL_ "GenSigTimeoutTime" BU_SG_REL_ EBCM_HS SG_ 479 EASSI_FuelReqOn 250;
BA_REL_ "GenSigSuprvResp" BU_SG_REL_ TCM_HS SG_ 479 EASSI_StrtTyp 1;
BA_REL_ "GenSigTimeoutMsg" BU_SG_REL_ TCM_HS SG_ 479 EASSI_StrtTyp 479;
BA_REL_ "GenSigTimeoutTime" BU_SG_REL_ TCM_HS SG_ 479 EASSI_StrtTyp 250;
BA_REL_ "GenSigSuprvResp" BU_SG_REL_ ECM_HS SG_ 479 EASSI_StrtTyp 1;
BA_REL_ "GenSigTimeoutMsg" BU_SG_REL_ ECM_HS SG_ 479 EASSI_StrtTyp 479;
BA_REL_ "GenSigTimeoutTime" BU_SG_REL_ ECM_HS SG_ 479 EASSI_StrtTyp 250;
BA_REL_ "GenSigSuprvResp" BU_SG_REL_ BCM_HS SG_ 479 EASSI_StrtTyp 1;
BA_REL_ "GenSigTimeoutMsg" BU_SG_REL_ BCM_HS SG_ 479 EASSI_StrtTyp 479;
BA_REL_ "GenSigTimeoutTime" BU_SG_REL_ BCM_HS SG_ 479 EASSI_StrtTyp 250;
BA_REL_ "GenSigSuprvResp" BU_SG_REL_ EBCM_OBD_HS SG_ 479 EASSI_StrtTyp 1;
BA_REL_ "GenSigTimeoutMsg" BU_SG_REL_ EBCM_OBD_HS SG_ 479 EASSI_StrtTyp 479;
BA_REL_ "GenSigTimeoutTime" BU_SG_REL_ EBCM_OBD_HS SG_ 479 EASSI_StrtTyp 250;
BA_REL_ "GenSigSuprvResp" BU_SG_REL_ EBCM_HS SG_ 479 EASSI_StrtTyp 1;
BA_REL_ "GenSigTimeoutMsg" BU_SG_REL_ EBCM_HS SG_ 479 EASSI_StrtTyp 479;
BA_REL_ "GenSigTimeoutTime" BU_SG_REL_ EBCM_HS SG_ 479 EASSI_StrtTyp 250;
BA_REL_ "GenSigSuprvResp" BU_SG_REL_ TCM_HS SG_ 479 EASSI_StrtStpSt 1;
BA_REL_ "GenSigTimeoutMsg" BU_SG_REL_ TCM_HS SG_ 479 EASSI_StrtStpSt 479;
BA_REL_ "GenSigTimeoutTime" BU_SG_REL_ TCM_HS SG_ 479 EASSI_StrtStpSt 250;
BA_REL_ "GenSigSuprvResp" BU_SG_REL_ ECM_HS SG_ 479 EASSI_StrtStpSt 1;
BA_REL_ "GenSigTimeoutMsg" BU_SG_REL_ ECM_HS SG_ 479 EASSI_StrtStpSt 479;
BA_REL_ "GenSigTimeoutTime" BU_SG_REL_ ECM_HS SG_ 479 EASSI_StrtStpSt 250;
BA_REL_ "GenSigSuprvResp" BU_SG_REL_ BCM_HS SG_ 479 EASSI_StrtStpSt 1;
BA_REL_ "GenSigTimeoutMsg" BU_SG_REL_ BCM_HS SG_ 479 EASSI_StrtStpSt 479;
BA_REL_ "GenSigTimeoutTime" BU_SG_REL_ BCM_HS SG_ 479 EASSI_StrtStpSt 250;
BA_REL_ "GenSigSuprvResp" BU_SG_REL_ EBCM_OBD_HS SG_ 479 EASSI_StrtStpSt 1;
BA_REL_ "GenSigTimeoutMsg" BU_SG_REL_ EBCM_OBD_HS SG_ 479 EASSI_StrtStpSt 479;
BA_REL_ "GenSigTimeoutTime" BU_SG_REL_ EBCM_OBD_HS SG_ 479 EASSI_StrtStpSt 250;
BA_REL_ "GenSigSuprvResp" BU_SG_REL_ EBCM_HS SG_ 479 EASSI_StrtStpSt 1;
BA_REL_ "GenSigTimeoutMsg" BU_SG_REL_ EBCM_HS SG_ 479 EASSI_StrtStpSt 479;
BA_REL_ "GenSigTimeoutTime" BU_SG_REL_ EBCM_HS SG_ 479 EASSI_StrtStpSt 250;
BA_REL_ "GenSigSuprvResp" BU_SG_REL_ TCM_HS SG_ 479 EASSI_TorqDetdIndet 1;
BA_REL_ "GenSigTimeoutMsg" BU_SG_REL_ TCM_HS SG_ 479 EASSI_TorqDetdIndet 479;
BA_REL_ "GenSigTimeoutTime" BU_SG_REL_ TCM_HS SG_ 479 EASSI_TorqDetdIndet 250;
BA_REL_ "GenSigSuprvResp" BU_SG_REL_ ECM_HS SG_ 479 EASSI_TorqDetdIndet 1;
BA_REL_ "GenSigTimeoutMsg" BU_SG_REL_ ECM_HS SG_ 479 EASSI_TorqDetdIndet 479;
BA_REL_ "GenSigTimeoutTime" BU_SG_REL_ ECM_HS SG_ 479 EASSI_TorqDetdIndet 250;
BA_REL_ "GenSigSuprvResp" BU_SG_REL_ BCM_HS SG_ 479 EASSI_TorqDetdIndet 1;
BA_REL_ "GenSigTimeoutMsg" BU_SG_REL_ BCM_HS SG_ 479 EASSI_TorqDetdIndet 479;
BA_REL_ "GenSigTimeoutTime" BU_SG_REL_ BCM_HS SG_ 479 EASSI_TorqDetdIndet 250;
BA_REL_ "GenSigSuprvResp" BU_SG_REL_ EBCM_OBD_HS SG_ 479 EASSI_TorqDetdIndet 1;
BA_REL_ "GenSigTimeoutMsg" BU_SG_REL_ EBCM_OBD_HS SG_ 479 EASSI_TorqDetdIndet 479;
BA_REL_ "GenSigTimeoutTime" BU_SG_REL_ EBCM_OBD_HS SG_ 479 EASSI_TorqDetdIndet 250;
BA_REL_ "GenSigSuprvResp" BU_SG_REL_ EBCM_HS SG_ 479 EASSI_TorqDetdIndet 1;
BA_REL_ "GenSigTimeoutMsg" BU_SG_REL_ EBCM_HS SG_ 479 EASSI_TorqDetdIndet 479;
BA_REL_ "GenSigTimeoutTime" BU_SG_REL_ EBCM_HS SG_ 479 EASSI_TorqDetdIndet 250;
BA_REL_ "GenSigSuprvResp" BU_SG_REL_ BCM_HS SG_ 479 ASIRI_Indication08 1;
BA_REL_ "GenSigTimeoutMsg" BU_SG_REL_ BCM_HS SG_ 479 ASIRI_Indication08 479;
BA_REL_ "GenSigTimeoutTime" BU_SG_REL_ BCM_HS SG_ 479 ASIRI_Indication08 62;
BA_REL_ "GenSigSuprvResp" BU_SG_REL_ BCM_HS SG_ 479 ASIRI_Indication07 1;
BA_REL_ "GenSigTimeoutMsg" BU_SG_REL_ BCM_HS SG_ 479 ASIRI_Indication07 479;
BA_REL_ "GenSigTimeoutTime" BU_SG_REL_ BCM_HS SG_ 479 ASIRI_Indication07 62;
BA_REL_ "GenSigSuprvResp" BU_SG_REL_ BCM_HS SG_ 479 ASIRI_Indication06 1;
BA_REL_ "GenSigTimeoutMsg" BU_SG_REL_ BCM_HS SG_ 479 ASIRI_Indication06 479;
BA_REL_ "GenSigTimeoutTime" BU_SG_REL_ BCM_HS SG_ 479 ASIRI_Indication06 62;
BA_REL_ "GenSigSuprvResp" BU_SG_REL_ BCM_HS SG_ 479 ASIRI_Indication05 1;
BA_REL_ "GenSigTimeoutMsg" BU_SG_REL_ BCM_HS SG_ 479 ASIRI_Indication05 479;
BA_REL_ "GenSigTimeoutTime" BU_SG_REL_ BCM_HS SG_ 479 ASIRI_Indication05 62;
BA_REL_ "GenSigSuprvResp" BU_SG_REL_ BCM_HS SG_ 479 ASIRI_Indication04 1;
BA_REL_ "GenSigTimeoutMsg" BU_SG_REL_ BCM_HS SG_ 479 ASIRI_Indication04 479;
BA_REL_ "GenSigTimeoutTime" BU_SG_REL_ BCM_HS SG_ 479 ASIRI_Indication04 62;
BA_REL_ "GenSigSuprvResp" BU_SG_REL_ BCM_HS SG_ 479 ASIRI_Indication03 1;
BA_REL_ "GenSigTimeoutMsg" BU_SG_REL_ BCM_HS SG_ 479 ASIRI_Indication03 479;
BA_REL_ "GenSigTimeoutTime" BU_SG_REL_ BCM_HS SG_ 479 ASIRI_Indication03 62;
BA_REL_ "GenSigSuprvResp" BU_SG_REL_ BCM_HS SG_ 479 ASIRI_Indication02 1;
BA_REL_ "GenSigTimeoutMsg" BU_SG_REL_ BCM_HS SG_ 479 ASIRI_Indication02 479;
BA_REL_ "GenSigTimeoutTime" BU_SG_REL_ BCM_HS SG_ 479 ASIRI_Indication02 62;
BA_REL_ "GenSigSuprvResp" BU_SG_REL_ BCM_HS SG_ 479 ASIRI_Indication01 1;
BA_REL_ "GenSigTimeoutMsg" BU_SG_REL_ BCM_HS SG_ 479 ASIRI_Indication01 479;
BA_REL_ "GenSigTimeoutTime" BU_SG_REL_ BCM_HS SG_ 479 ASIRI_Indication01 62;
BA_REL_ "GenSigSuprvResp" BU_SG_REL_ BCM_HS SG_ 479 PTWrmgWtToShftIO 1;
BA_REL_ "GenSigTimeoutMsg" BU_SG_REL_ BCM_HS SG_ 479 PTWrmgWtToShftIO 479;
BA_REL_ "GenSigTimeoutTime" BU_SG_REL_ BCM_HS SG_ 479 PTWrmgWtToShftIO 250;
BA_REL_ "GenSigSuprvResp" BU_SG_REL_ EBOOST_HS SG_ 479 PrplsnSysAtv 1;
BA_REL_ "GenSigTimeoutMsg" BU_SG_REL_ EBOOST_HS SG_ 479 PrplsnSysAtv 479;
BA_REL_ "GenSigTimeoutTime" BU_SG_REL_ EBOOST_HS SG_ 479 PrplsnSysAtv 250;
BA_REL_ "GenSigSuprvResp" BU_SG_REL_ HCP_T_HS SG_ 479 PrplsnSysAtv 1;
BA_REL_ "GenSigTimeoutMsg" BU_SG_REL_ HCP_T_HS SG_ 479 PrplsnSysAtv 479;
BA_REL_ "GenSigTimeoutTime" BU_SG_REL_ HCP_T_HS SG_ 479 PrplsnSysAtv 250;
BA_REL_ "GenSigSuprvResp" BU_SG_REL_ EPB_HS SG_ 479 PrplsnSysAtv 1;
BA_REL_ "GenSigTimeoutMsg" BU_SG_REL_ EPB_HS SG_ 479 PrplsnSysAtv 479;
BA_REL_ "GenSigTimeoutTime" BU_SG_REL_ EPB_HS SG_ 479 PrplsnSysAtv 250;
BA_REL_ "GenSigSuprvResp" BU_SG_REL_ BSM_HS SG_ 479 PrplsnSysAtv 1;
BA_REL_ "GenSigTimeoutMsg" BU_SG_REL_ BSM_HS SG_ 479 PrplsnSysAtv 479;
BA_REL_ "GenSigTimeoutTime" BU_SG_REL_ BSM_HS SG_ 479 PrplsnSysAtv 250;
BA_REL_ "GenSigSuprvResp" BU_SG_REL_ VICM_HS SG_ 479 PrplsnSysAtv 1;
BA_REL_ "GenSigTimeoutMsg" BU_SG_REL_ VICM_HS SG_ 479 PrplsnSysAtv 479;
BA_REL_ "GenSigTimeoutTime" BU_SG_REL_ VICM_HS SG_ 479 PrplsnSysAtv 250;
BA_REL_ "GenSigSuprvResp" BU_SG_REL_ ICCM_OBD_HS SG_ 479 PrplsnSysAtv 1;
BA_REL_ "GenSigTimeoutMsg" BU_SG_REL_ ICCM_OBD_HS SG_ 479 PrplsnSysAtv 479;
BA_REL_ "GenSigTimeoutTime" BU_SG_REL_ ICCM_OBD_HS SG_ 479 PrplsnSysAtv 250;
BA_REL_ "GenSigSuprvResp" BU_SG_REL_ ICCM_HS SG_ 479 PrplsnSysAtv 1;
BA_REL_ "GenSigTimeoutMsg" BU_SG_REL_ ICCM_HS SG_ 479 PrplsnSysAtv 479;
BA_REL_ "GenSigTimeoutTime" BU_SG_REL_ ICCM_HS SG_ 479 PrplsnSysAtv 250;
BA_REL_ "GenSigSuprvResp" BU_SG_REL_ VICM2_HS SG_ 479 PrplsnSysAtv 1;
BA_REL_ "GenSigTimeoutMsg" BU_SG_REL_ VICM2_HS SG_ 479 PrplsnSysAtv 479;
BA_REL_ "GenSigTimeoutTime" BU_SG_REL_ VICM2_HS SG_ 479 PrplsnSysAtv 250;
BA_REL_ "GenSigSuprvResp" BU_SG_REL_ VICM2_HS SG_ 479 PrplsnSysAtv 1;
BA_REL_ "GenSigTimeoutMsg" BU_SG_REL_ VICM2_HS SG_ 479 PrplsnSysAtv 479;
BA_REL_ "GenSigTimeoutTime" BU_SG_REL_ VICM2_HS SG_ 479 PrplsnSysAtv 250;
BA_REL_ "GenSigSuprvResp" BU_SG_REL_ BCM_HS SG_ 479 PTShftLvrLckRqd 1;
BA_REL_ "GenSigTimeoutMsg" BU_SG_REL_ BCM_HS SG_ 479 PTShftLvrLckRqd 479;
BA_REL_ "GenSigTimeoutTime" BU_SG_REL_ BCM_HS SG_ 479 PTShftLvrLckRqd 250;
BA_REL_ "GenSigSuprvResp" BU_SG_REL_ CGM_HS SG_ 211 ActAxleTrq 1;
BA_REL_ "GenSigTimeoutMsg" BU_SG_REL_ CGM_HS SG_ 211 ActAxleTrq 211;
BA_REL_ "GenSigTimeoutTime" BU_SG_REL_ CGM_HS SG_ 211 ActAxleTrq 250;
BA_REL_ "GenSigSuprvResp" BU_SG_REL_ HCP_T_HS SG_ 211 ActAxleTrq 1;
BA_REL_ "GenSigTimeoutMsg" BU_SG_REL_ HCP_T_HS SG_ 211 ActAxleTrq 211;
BA_REL_ "GenSigTimeoutTime" BU_SG_REL_ HCP_T_HS SG_ 211 ActAxleTrq 250;
BA_REL_ "GenSigSuprvResp" BU_SG_REL_ FCM_HS SG_ 211 ActAxleTrq 1;
BA_REL_ "GenSigTimeoutMsg" BU_SG_REL_ FCM_HS SG_ 211 ActAxleTrq 211;
BA_REL_ "GenSigTimeoutTime" BU_SG_REL_ FCM_HS SG_ 211 ActAxleTrq 250;
BA_REL_ "GenSigSuprvResp" BU_SG_REL_ SADS_HS SG_ 211 ActAxleTrq 1;
BA_REL_ "GenSigTimeoutMsg" BU_SG_REL_ SADS_HS SG_ 211 ActAxleTrq 211;
BA_REL_ "GenSigTimeoutTime" BU_SG_REL_ SADS_HS SG_ 211 ActAxleTrq 250;
BA_REL_ "GenSigSuprvResp" BU_SG_REL_ EPS_HS SG_ 211 ActAxleTrq 1;
BA_REL_ "GenSigTimeoutMsg" BU_SG_REL_ EPS_HS SG_ 211 ActAxleTrq 211;
BA_REL_ "GenSigTimeoutTime" BU_SG_REL_ EPS_HS SG_ 211 ActAxleTrq 250;
BA_REL_ "GenSigSuprvResp" BU_SG_REL_ BSM_HS SG_ 211 ActAxleTrq 1;
BA_REL_ "GenSigTimeoutMsg" BU_SG_REL_ BSM_HS SG_ 211 ActAxleTrq 211;
BA_REL_ "GenSigTimeoutTime" BU_SG_REL_ BSM_HS SG_ 211 ActAxleTrq 250;
BA_REL_ "GenSigSuprvResp" BU_SG_REL_ VICM_HS SG_ 211 ActAxleTrq 1;
BA_REL_ "GenSigTimeoutMsg" BU_SG_REL_ VICM_HS SG_ 211 ActAxleTrq 211;
BA_REL_ "GenSigTimeoutTime" BU_SG_REL_ VICM_HS SG_ 211 ActAxleTrq 250;
BA_REL_ "GenSigSuprvResp" BU_SG_REL_ BSM_HS SG_ 1020 OtsAirTmpEmsnsRel 1;
BA_REL_ "GenSigTimeoutMsg" BU_SG_REL_ BSM_HS SG_ 1020 OtsAirTmpEmsnsRel 1020;
BA_REL_ "GenSigTimeoutTime" BU_SG_REL_ BSM_HS SG_ 1020 OtsAirTmpEmsnsRel 625;
BA_REL_ "GenSigSuprvResp" BU_SG_REL_ VICM_HS SG_ 1020 OtsAirTmpEmsnsRel 1;
BA_REL_ "GenSigTimeoutMsg" BU_SG_REL_ VICM_HS SG_ 1020 OtsAirTmpEmsnsRel 1020;
BA_REL_ "GenSigTimeoutTime" BU_SG_REL_ VICM_HS SG_ 1020 OtsAirTmpEmsnsRel 625;
BA_REL_ "GenSigSuprvResp" BU_SG_REL_ HCP_B_HS SG_ 1020 OtsAirTmpEmsnsRel 1;
BA_REL_ "GenSigTimeoutMsg" BU_SG_REL_ HCP_B_HS SG_ 1020 OtsAirTmpEmsnsRel 1020;
BA_REL_ "GenSigTimeoutTime" BU_SG_REL_ HCP_B_HS SG_ 1020 OtsAirTmpEmsnsRel 625;
BA_REL_ "GenSigSuprvResp" BU_SG_REL_ BSM_HS SG_ 1020 OATEmsnsRelCrVal 1;
BA_REL_ "GenSigTimeoutMsg" BU_SG_REL_ BSM_HS SG_ 1020 OATEmsnsRelCrVal 1020;
BA_REL_ "GenSigTimeoutTime" BU_SG_REL_ BSM_HS SG_ 1020 OATEmsnsRelCrVal 625;
BA_REL_ "GenSigSuprvResp" BU_SG_REL_ VICM_HS SG_ 1020 OATEmsnsRelCrVal 1;
BA_REL_ "GenSigTimeoutMsg" BU_SG_REL_ VICM_HS SG_ 1020 OATEmsnsRelCrVal 1020;
BA_REL_ "GenSigTimeoutTime" BU_SG_REL_ VICM_HS SG_ 1020 OATEmsnsRelCrVal 625;
BA_REL_ "GenSigSuprvResp" BU_SG_REL_ HCP_B_HS SG_ 1020 OATEmsnsRelCrVal 1;
BA_REL_ "GenSigTimeoutMsg" BU_SG_REL_ HCP_B_HS SG_ 1020 OATEmsnsRelCrVal 1020;
BA_REL_ "GenSigTimeoutTime" BU_SG_REL_ HCP_B_HS SG_ 1020 OATEmsnsRelCrVal 625;
BA_REL_ "GenSigSuprvResp" BU_SG_REL_ BSM_HS SG_ 1020 CatlystOutGasTempEst 1;
BA_REL_ "GenSigTimeoutMsg" BU_SG_REL_ BSM_HS SG_ 1020 CatlystOutGasTempEst 1020;
BA_REL_ "GenSigTimeoutTime" BU_SG_REL_ BSM_HS SG_ 1020 CatlystOutGasTempEst 625;
BA_REL_ "GenSigSuprvResp" BU_SG_REL_ VICM_HS SG_ 1020 CatlystOutGasTempEst 1;
BA_REL_ "GenSigTimeoutMsg" BU_SG_REL_ VICM_HS SG_ 1020 CatlystOutGasTempEst 1020;
BA_REL_ "GenSigTimeoutTime" BU_SG_REL_ VICM_HS SG_ 1020 CatlystOutGasTempEst 625;
BA_REL_ "GenSigSuprvResp" BU_SG_REL_ TCM_HS SG_ 1020 OtsAirTmpCrVal 1;
BA_REL_ "GenSigTimeoutMsg" BU_SG_REL_ TCM_HS SG_ 1020 OtsAirTmpCrVal 1020;
BA_REL_ "GenSigTimeoutTime" BU_SG_REL_ TCM_HS SG_ 1020 OtsAirTmpCrVal 625;
BA_REL_ "GenSigSuprvResp" BU_SG_REL_ BSM_HS SG_ 1020 OtsAirTmpCrVal 1;
BA_REL_ "GenSigTimeoutMsg" BU_SG_REL_ BSM_HS SG_ 1020 OtsAirTmpCrVal 1020;
BA_REL_ "GenSigTimeoutTime" BU_SG_REL_ BSM_HS SG_ 1020 OtsAirTmpCrVal 625;
BA_REL_ "GenSigSuprvResp" BU_SG_REL_ VICM_HS SG_ 1020 OtsAirTmpCrVal 1;
BA_REL_ "GenSigTimeoutMsg" BU_SG_REL_ VICM_HS SG_ 1020 OtsAirTmpCrVal 1020;
BA_REL_ "GenSigTimeoutTime" BU_SG_REL_ VICM_HS SG_ 1020 OtsAirTmpCrVal 625;
BA_REL_ "GenSigSuprvResp" BU_SG_REL_ BSM_HS SG_ 1020 OtsAirTmp 1;
BA_REL_ "GenSigTimeoutMsg" BU_SG_REL_ BSM_HS SG_ 1020 OtsAirTmp 1020;
BA_REL_ "GenSigTimeoutTime" BU_SG_REL_ BSM_HS SG_ 1020 OtsAirTmp 625;
BA_REL_ "GenSigSuprvResp" BU_SG_REL_ VICM_HS SG_ 1020 OtsAirTmp 1;
BA_REL_ "GenSigTimeoutMsg" BU_SG_REL_ VICM_HS SG_ 1020 OtsAirTmp 1020;
BA_REL_ "GenSigTimeoutTime" BU_SG_REL_ VICM_HS SG_ 1020 OtsAirTmp 625;
BA_REL_ "GenSigSuprvResp" BU_SG_REL_ PFAF_HS SG_ 1020 OtsAirTmp 1;
BA_REL_ "GenSigTimeoutMsg" BU_SG_REL_ PFAF_HS SG_ 1020 OtsAirTmp 1020;
BA_REL_ "GenSigTimeoutTime" BU_SG_REL_ PFAF_HS SG_ 1020 OtsAirTmp 625;
BA_REL_ "GenSigSuprvResp" BU_SG_REL_ BSM_HS SG_ 1020 EngInltSpcfcHmdty 1;
BA_REL_ "GenSigTimeoutMsg" BU_SG_REL_ BSM_HS SG_ 1020 EngInltSpcfcHmdty 1020;
BA_REL_ "GenSigTimeoutTime" BU_SG_REL_ BSM_HS SG_ 1020 EngInltSpcfcHmdty 625;
BA_REL_ "GenSigSuprvResp" BU_SG_REL_ VICM_HS SG_ 1020 EngInltSpcfcHmdty 1;
BA_REL_ "GenSigTimeoutMsg" BU_SG_REL_ VICM_HS SG_ 1020 EngInltSpcfcHmdty 1020;
BA_REL_ "GenSigTimeoutTime" BU_SG_REL_ VICM_HS SG_ 1020 EngInltSpcfcHmdty 625;
BA_REL_ "GenSigSuprvResp" BU_SG_REL_ BCM_HS SG_ 567 DrvStyPerfMdCsCrStVal 1;
BA_REL_ "GenSigTimeoutMsg" BU_SG_REL_ BCM_HS SG_ 567 DrvStyPerfMdCsCrStVal 567;
BA_REL_ "GenSigTimeoutTime" BU_SG_REL_ BCM_HS SG_ 567 DrvStyPerfMdCsCrStVal 625;
BA_REL_ "GenSigSuprvResp" BU_SG_REL_ BCM_HS SG_ 567 DrvStyPerfMdCsStAvl 1;
BA_REL_ "GenSigTimeoutMsg" BU_SG_REL_ BCM_HS SG_ 567 DrvStyPerfMdCsStAvl 567;
BA_REL_ "GenSigTimeoutTime" BU_SG_REL_ BCM_HS SG_ 567 DrvStyPerfMdCsStAvl 625;
BA_REL_ "GenSigSuprvResp" BU_SG_REL_ BCM_HS SG_ 567 PsngStPerfMdCsCrStVal 1;
BA_REL_ "GenSigTimeoutMsg" BU_SG_REL_ BCM_HS SG_ 567 PsngStPerfMdCsCrStVal 567;
BA_REL_ "GenSigTimeoutTime" BU_SG_REL_ BCM_HS SG_ 567 PsngStPerfMdCsCrStVal 625;
BA_REL_ "GenSigSuprvResp" BU_SG_REL_ BCM_HS SG_ 567 PsngStPerfMdCsStAvl 1;
BA_REL_ "GenSigTimeoutMsg" BU_SG_REL_ BCM_HS SG_ 567 PsngStPerfMdCsStAvl 567;
BA_REL_ "GenSigTimeoutTime" BU_SG_REL_ BCM_HS SG_ 567 PsngStPerfMdCsStAvl 625;
BA_REL_ "GenSigSuprvResp" BU_SG_REL_ BCM_HS SG_ 567 DrvrStPerfMdCsCrStVal 1;
BA_REL_ "GenSigTimeoutMsg" BU_SG_REL_ BCM_HS SG_ 567 DrvrStPerfMdCsCrStVal 567;
BA_REL_ "GenSigTimeoutTime" BU_SG_REL_ BCM_HS SG_ 567 DrvrStPerfMdCsCrStVal 625;
BA_REL_ "GenSigSuprvResp" BU_SG_REL_ BCM_HS SG_ 567 DrvrStPerfMdCsStAvl 1;
BA_REL_ "GenSigTimeoutMsg" BU_SG_REL_ BCM_HS SG_ 567 DrvrStPerfMdCsStAvl 567;
BA_REL_ "GenSigTimeoutTime" BU_SG_REL_ BCM_HS SG_ 567 DrvrStPerfMdCsStAvl 625;
BA_REL_ "GenSigSuprvResp" BU_SG_REL_ BCM_HS SG_ 567 ACCPerfMdCsCrStVal 1;
BA_REL_ "GenSigTimeoutMsg" BU_SG_REL_ BCM_HS SG_ 567 ACCPerfMdCsCrStVal 567;
BA_REL_ "GenSigTimeoutTime" BU_SG_REL_ BCM_HS SG_ 567 ACCPerfMdCsCrStVal 625;
BA_REL_ "GenSigSuprvResp" BU_SG_REL_ BCM_HS SG_ 567 ACCPerfMdCsStAvl 1;
BA_REL_ "GenSigTimeoutMsg" BU_SG_REL_ BCM_HS SG_ 567 ACCPerfMdCsStAvl 567;
BA_REL_ "GenSigTimeoutTime" BU_SG_REL_ BCM_HS SG_ 567 ACCPerfMdCsStAvl 625;
BA_REL_ "GenSigSuprvResp" BU_SG_REL_ BCM_HS SG_ 1219 DslExhFldDiagWrnIdRq 1;
BA_REL_ "GenSigTimeoutMsg" BU_SG_REL_ BCM_HS SG_ 1219 DslExhFldDiagWrnIdRq 1219;
BA_REL_ "GenSigTimeoutTime" BU_SG_REL_ BCM_HS SG_ 1219 DslExhFldDiagWrnIdRq 2500;
BA_REL_ "GenSigSuprvResp" BU_SG_REL_ BCM_HS SG_ 1219 DslEmnsOBDMrkt 1;
BA_REL_ "GenSigTimeoutMsg" BU_SG_REL_ BCM_HS SG_ 1219 DslEmnsOBDMrkt 1219;
BA_REL_ "GenSigTimeoutTime" BU_SG_REL_ BCM_HS SG_ 1219 DslEmnsOBDMrkt 2500;
BA_REL_ "GenSigSuprvResp" BU_SG_REL_ ICCM_OBD_HS SG_ 528 BrkSysAutBrkReqRC 1;
BA_REL_ "GenSigTimeoutMsg" BU_SG_REL_ ICCM_OBD_HS SG_ 528 BrkSysAutBrkReqRC 528;
BA_REL_ "GenSigTimeoutTime" BU_SG_REL_ ICCM_OBD_HS SG_ 528 BrkSysAutBrkReqRC 250;
BA_REL_ "GenSigSuprvResp" BU_SG_REL_ ICCM_HS SG_ 528 BrkSysAutBrkReqRC 1;
BA_REL_ "GenSigTimeoutMsg" BU_SG_REL_ ICCM_HS SG_ 528 BrkSysAutBrkReqRC 528;
BA_REL_ "GenSigTimeoutTime" BU_SG_REL_ ICCM_HS SG_ 528 BrkSysAutBrkReqRC 250;
BA_REL_ "GenSigSuprvResp" BU_SG_REL_ ICCM_OBD_HS SG_ 528 BrkSysAutBrkReqPVal 1;
BA_REL_ "GenSigTimeoutMsg" BU_SG_REL_ ICCM_OBD_HS SG_ 528 BrkSysAutBrkReqPVal 528;
BA_REL_ "GenSigTimeoutTime" BU_SG_REL_ ICCM_OBD_HS SG_ 528 BrkSysAutBrkReqPVal 250;
BA_REL_ "GenSigSuprvResp" BU_SG_REL_ ICCM_HS SG_ 528 BrkSysAutBrkReqPVal 1;
BA_REL_ "GenSigTimeoutMsg" BU_SG_REL_ ICCM_HS SG_ 528 BrkSysAutBrkReqPVal 528;
BA_REL_ "GenSigTimeoutTime" BU_SG_REL_ ICCM_HS SG_ 528 BrkSysAutBrkReqPVal 250;
BA_REL_ "GenSigSuprvResp" BU_SG_REL_ ICCM_OBD_HS SG_ 528 BSABR_TrlBrkRq 1;
BA_REL_ "GenSigTimeoutMsg" BU_SG_REL_ ICCM_OBD_HS SG_ 528 BSABR_TrlBrkRq 528;
BA_REL_ "GenSigTimeoutTime" BU_SG_REL_ ICCM_OBD_HS SG_ 528 BSABR_TrlBrkRq 250;
BA_REL_ "GenSigSuprvResp" BU_SG_REL_ ICCM_HS SG_ 528 BSABR_TrlBrkRq 1;
BA_REL_ "GenSigTimeoutMsg" BU_SG_REL_ ICCM_HS SG_ 528 BSABR_TrlBrkRq 528;
BA_REL_ "GenSigTimeoutTime" BU_SG_REL_ ICCM_HS SG_ 528 BSABR_TrlBrkRq 250;
BA_REL_ "GenSigSuprvResp" BU_SG_REL_ ICCM_OBD_HS SG_ 528 BSABR_TrlBrkCntlIntRq 1;
BA_REL_ "GenSigTimeoutMsg" BU_SG_REL_ ICCM_OBD_HS SG_ 528 BSABR_TrlBrkCntlIntRq 528;
BA_REL_ "GenSigTimeoutTime" BU_SG_REL_ ICCM_OBD_HS SG_ 528 BSABR_TrlBrkCntlIntRq 250;
BA_REL_ "GenSigSuprvResp" BU_SG_REL_ ICCM_HS SG_ 528 BSABR_TrlBrkCntlIntRq 1;
BA_REL_ "GenSigTimeoutMsg" BU_SG_REL_ ICCM_HS SG_ 528 BSABR_TrlBrkCntlIntRq 528;
BA_REL_ "GenSigTimeoutTime" BU_SG_REL_ ICCM_HS SG_ 528 BSABR_TrlBrkCntlIntRq 250;
BA_REL_ "GenSigSuprvResp" BU_SG_REL_ TCM_HS SG_ 442 CrksftTqMinImCap 1;
BA_REL_ "GenSigTimeoutMsg" BU_SG_REL_ TCM_HS SG_ 442 CrksftTqMinImCap 442;
BA_REL_ "GenSigTimeoutTime" BU_SG_REL_ TCM_HS SG_ 442 CrksftTqMinImCap 250;
BA_REL_ "GenSigSuprvResp" BU_SG_REL_ HCP_T_HS SG_ 989 RdHVCntctrShdwnReq 1;
BA_REL_ "GenSigTimeoutMsg" BU_SG_REL_ HCP_T_HS SG_ 989 RdHVCntctrShdwnReq 989;
BA_REL_ "GenSigTimeoutTime" BU_SG_REL_ HCP_T_HS SG_ 989 RdHVCntctrShdwnReq 250;
BA_REL_ "GenSigSuprvResp" BU_SG_REL_ HCP_T_HS SG_ 989 RdHVCntctrShdwnReq 1;
BA_REL_ "GenSigTimeoutMsg" BU_SG_REL_ HCP_T_HS SG_ 989 RdHVCntctrShdwnReq 989;
BA_REL_ "GenSigTimeoutTime" BU_SG_REL_ HCP_T_HS SG_ 989 RdHVCntctrShdwnReq 250;
BA_REL_ "GenSigSuprvResp" BU_SG_REL_ HCP_T_HS SG_ 989 RdHVCntctrShdwnReq 1;
BA_REL_ "GenSigTimeoutMsg" BU_SG_REL_ HCP_T_HS SG_ 989 RdHVCntctrShdwnReq 989;
BA_REL_ "GenSigTimeoutTime" BU_SG_REL_ HCP_T_HS SG_ 989 RdHVCntctrShdwnReq 250;
BA_REL_ "GenSigSuprvResp" BU_SG_REL_ HCP_HS SG_ 989 RdHVCntctrShdwnReq 1;
BA_REL_ "GenSigTimeoutMsg" BU_SG_REL_ HCP_HS SG_ 989 RdHVCntctrShdwnReq 989;
BA_REL_ "GenSigTimeoutTime" BU_SG_REL_ HCP_HS SG_ 989 RdHVCntctrShdwnReq 250;
BA_REL_ "GenSigSuprvResp" BU_SG_REL_ HCP_HS SG_ 989 RdHVCntctrShdwnReq 1;
BA_REL_ "GenSigTimeoutMsg" BU_SG_REL_ HCP_HS SG_ 989 RdHVCntctrShdwnReq 989;
BA_REL_ "GenSigTimeoutTime" BU_SG_REL_ HCP_HS SG_ 989 RdHVCntctrShdwnReq 250;
BA_REL_ "GenSigSuprvResp" BU_SG_REL_ HCP_HS SG_ 989 RdHVCntctrShdwnReq 1;
BA_REL_ "GenSigTimeoutMsg" BU_SG_REL_ HCP_HS SG_ 989 RdHVCntctrShdwnReq 989;
BA_REL_ "GenSigTimeoutTime" BU_SG_REL_ HCP_HS SG_ 989 RdHVCntctrShdwnReq 250;
BA_REL_ "GenSigSuprvResp" BU_SG_REL_ HCP_B_HS SG_ 989 RdHVCntctrShdwnReq 1;
BA_REL_ "GenSigTimeoutMsg" BU_SG_REL_ HCP_B_HS SG_ 989 RdHVCntctrShdwnReq 989;
BA_REL_ "GenSigTimeoutTime" BU_SG_REL_ HCP_B_HS SG_ 989 RdHVCntctrShdwnReq 250;
BA_REL_ "GenSigSuprvResp" BU_SG_REL_ HCP_B_HS SG_ 989 JmpStrtEnbld 1;
BA_REL_ "GenSigTimeoutMsg" BU_SG_REL_ HCP_B_HS SG_ 989 JmpStrtEnbld 989;
BA_REL_ "GenSigTimeoutTime" BU_SG_REL_ HCP_B_HS SG_ 989 JmpStrtEnbld 250;
BA_REL_ "GenSigSuprvResp" BU_SG_REL_ HCP_T_HS SG_ 989 RdHVCntctrCmdStat 1;
BA_REL_ "GenSigTimeoutMsg" BU_SG_REL_ HCP_T_HS SG_ 989 RdHVCntctrCmdStat 989;
BA_REL_ "GenSigTimeoutTime" BU_SG_REL_ HCP_T_HS SG_ 989 RdHVCntctrCmdStat 250;
BA_REL_ "GenSigSuprvResp" BU_SG_REL_ HCP_T_HS SG_ 989 RdHVCntctrCmdStat 1;
BA_REL_ "GenSigTimeoutMsg" BU_SG_REL_ HCP_T_HS SG_ 989 RdHVCntctrCmdStat 989;
BA_REL_ "GenSigTimeoutTime" BU_SG_REL_ HCP_T_HS SG_ 989 RdHVCntctrCmdStat 250;
BA_REL_ "GenSigSuprvResp" BU_SG_REL_ HCP_T_HS SG_ 989 RdHVCntctrCmdStat 1;
BA_REL_ "GenSigTimeoutMsg" BU_SG_REL_ HCP_T_HS SG_ 989 RdHVCntctrCmdStat 989;
BA_REL_ "GenSigTimeoutTime" BU_SG_REL_ HCP_T_HS SG_ 989 RdHVCntctrCmdStat 250;
BA_REL_ "GenSigSuprvResp" BU_SG_REL_ HCP_HS SG_ 989 RdHVCntctrCmdStat 1;
BA_REL_ "GenSigTimeoutMsg" BU_SG_REL_ HCP_HS SG_ 989 RdHVCntctrCmdStat 989;
BA_REL_ "GenSigTimeoutTime" BU_SG_REL_ HCP_HS SG_ 989 RdHVCntctrCmdStat 250;
BA_REL_ "GenSigSuprvResp" BU_SG_REL_ HCP_HS SG_ 989 RdHVCntctrCmdStat 1;
BA_REL_ "GenSigTimeoutMsg" BU_SG_REL_ HCP_HS SG_ 989 RdHVCntctrCmdStat 989;
BA_REL_ "GenSigTimeoutTime" BU_SG_REL_ HCP_HS SG_ 989 RdHVCntctrCmdStat 250;
BA_REL_ "GenSigSuprvResp" BU_SG_REL_ HCP_HS SG_ 989 RdHVCntctrCmdStat 1;
BA_REL_ "GenSigTimeoutMsg" BU_SG_REL_ HCP_HS SG_ 989 RdHVCntctrCmdStat 989;
BA_REL_ "GenSigTimeoutTime" BU_SG_REL_ HCP_HS SG_ 989 RdHVCntctrCmdStat 250;
BA_REL_ "GenSigSuprvResp" BU_SG_REL_ HCP_B_HS SG_ 989 RdHVCntctrCmdStat 1;
BA_REL_ "GenSigTimeoutMsg" BU_SG_REL_ HCP_B_HS SG_ 989 RdHVCntctrCmdStat 989;
BA_REL_ "GenSigTimeoutTime" BU_SG_REL_ HCP_B_HS SG_ 989 RdHVCntctrCmdStat 250;
BA_REL_ "GenSigSuprvResp" BU_SG_REL_ BSM_HS SG_ 988 EGHRInhbtRqstd 1;
BA_REL_ "GenSigTimeoutMsg" BU_SG_REL_ BSM_HS SG_ 988 EGHRInhbtRqstd 988;
BA_REL_ "GenSigTimeoutTime" BU_SG_REL_ BSM_HS SG_ 988 EGHRInhbtRqstd 250;
BA_REL_ "GenSigSuprvResp" BU_SG_REL_ BSM_HS SG_ 988 AccPwrModMinCoolRq 1;
BA_REL_ "GenSigTimeoutMsg" BU_SG_REL_ BSM_HS SG_ 988 AccPwrModMinCoolRq 988;
BA_REL_ "GenSigTimeoutTime" BU_SG_REL_ BSM_HS SG_ 988 AccPwrModMinCoolRq 250;
BA_REL_ "GenSigSuprvResp" BU_SG_REL_ VICM_HS SG_ 988 AccPwrModMinCoolRq 1;
BA_REL_ "GenSigTimeoutMsg" BU_SG_REL_ VICM_HS SG_ 988 AccPwrModMinCoolRq 988;
BA_REL_ "GenSigTimeoutTime" BU_SG_REL_ VICM_HS SG_ 988 AccPwrModMinCoolRq 250;
BA_REL_ "GenSigSuprvResp" BU_SG_REL_ BSM_HS SG_ 988 A6ERRAlrmTime 1;
BA_REL_ "GenSigTimeoutMsg" BU_SG_REL_ BSM_HS SG_ 988 A6ERRAlrmTime 988;
BA_REL_ "GenSigTimeoutTime" BU_SG_REL_ BSM_HS SG_ 988 A6ERRAlrmTime 250;
BA_REL_ "GenSigSuprvResp" BU_SG_REL_ VICM_HS SG_ 988 A6ERRAlrmTime 1;
BA_REL_ "GenSigTimeoutMsg" BU_SG_REL_ VICM_HS SG_ 988 A6ERRAlrmTime 988;
BA_REL_ "GenSigTimeoutTime" BU_SG_REL_ VICM_HS SG_ 988 A6ERRAlrmTime 250;
BA_REL_ "GenSigSuprvResp" BU_SG_REL_ BSM_HS SG_ 988 A6ERRAlrmReq 1;
BA_REL_ "GenSigTimeoutMsg" BU_SG_REL_ BSM_HS SG_ 988 A6ERRAlrmReq 988;
BA_REL_ "GenSigTimeoutTime" BU_SG_REL_ BSM_HS SG_ 988 A6ERRAlrmReq 250;
BA_REL_ "GenSigSuprvResp" BU_SG_REL_ VICM_HS SG_ 988 A6ERRAlrmReq 1;
BA_REL_ "GenSigTimeoutMsg" BU_SG_REL_ VICM_HS SG_ 988 A6ERRAlrmReq 988;
BA_REL_ "GenSigTimeoutTime" BU_SG_REL_ VICM_HS SG_ 988 A6ERRAlrmReq 250;
BA_REL_ "GenSigSuprvResp" BU_SG_REL_ HCP_T_HS SG_ 988 HVPropChgrUnbl 1;
BA_REL_ "GenSigTimeoutMsg" BU_SG_REL_ HCP_T_HS SG_ 988 HVPropChgrUnbl 988;
BA_REL_ "GenSigTimeoutTime" BU_SG_REL_ HCP_T_HS SG_ 988 HVPropChgrUnbl 250;
BA_REL_ "GenSigSuprvResp" BU_SG_REL_ VICM_HS SG_ 988 EngHtrValvBpasCmd 1;
BA_REL_ "GenSigTimeoutMsg" BU_SG_REL_ VICM_HS SG_ 988 EngHtrValvBpasCmd 988;
BA_REL_ "GenSigTimeoutTime" BU_SG_REL_ VICM_HS SG_ 988 EngHtrValvBpasCmd 250;
VAL_ 563 SPMCA_SusPrfMd6Avl 1 "true" 0 "false" ;
VAL_ 563 SPMCA_SusPrfMd5Avl 1 "true" 0 "false" ;
VAL_ 563 SPMCA_SusPrfMd4Avl 1 "true" 0 "false" ;
VAL_ 563 SPMCA_SusPrfMd3Avl 1 "true" 0 "false" ;
VAL_ 563 SPMCA_SusPrfMd2Avl 1 "true" 0 "false" ;
VAL_ 563 SPMCA_SusPrfMd1Avl 1 "true" 0 "false" ;
VAL_ 563 SPMCA_StrPrfMd6Avl 1 "true" 0 "false" ;
VAL_ 563 SPMCA_StrPrfMd5Avl 1 "true" 0 "false" ;
VAL_ 563 SPMCA_StrPrfMd4Avl 1 "true" 0 "false" ;
VAL_ 563 SPMCA_StrPrfMd3Avl 1 "true" 0 "false" ;
VAL_ 563 SPMCA_StrPrfMd2Avl 1 "true" 0 "false" ;
VAL_ 563 SPMCA_StrPrfMd1Avl 1 "true" 0 "false" ;
VAL_ 563 SPMCA_SndPrfMd6Avl 1 "true" 0 "false" ;
VAL_ 563 SPMCA_SndPrfMd5Avl 1 "true" 0 "false" ;
VAL_ 563 SPMCA_SndPrfMd4Avl 1 "true" 0 "false" ;
VAL_ 563 SPMCA_SndPrfMd3Avl 1 "true" 0 "false" ;
VAL_ 563 SPMCA_SndPrfMd2Avl 1 "true" 0 "false" ;
VAL_ 563 SPMCA_SndPrfMd1Avl 1 "true" 0 "false" ;
VAL_ 563 DPMCA_DispPrfMd6Avl 1 "true" 0 "false" ;
VAL_ 563 DPMCA_DispPrfMd5Avl 1 "true" 0 "false" ;
VAL_ 563 DPMCA_DispPrfMd4Avl 1 "true" 0 "false" ;
VAL_ 563 DPMCA_DispPrfMd3Avl 1 "true" 0 "false" ;
VAL_ 563 DPMCA_DispPrfMd2Avl 1 "true" 0 "false" ;
VAL_ 563 DPMCA_DispPrfMd1Avl 1 "true" 0 "false" ;
VAL_ 563 DPMCA_DrvlPrfMd6Avl 1 "true" 0 "false" ;
VAL_ 563 DPMCA_DrvlPrfMd5Avl 1 "true" 0 "false" ;
VAL_ 563 DPMCA_DrvlPrfMd4Avl 1 "true" 0 "false" ;
VAL_ 563 DPMCA_DrvlPrfMd3Avl 1 "true" 0 "false" ;
VAL_ 563 DPMCA_DrvlPrfMd2Avl 1 "true" 0 "false" ;
VAL_ 563 DPMCA_DrvlPrfMd1Avl 1 "true" 0 "false" ;
VAL_ 1323 TireLRTmpV 1 "Invalid" 0 "Valid" ;
VAL_ 1323 TireLFTmpV 1 "Invalid" 0 "Valid" ;
VAL_ 1323 TireRRTmpV 1 "Invalid" 0 "Valid" ;
VAL_ 1323 TireRFTmpV 1 "Invalid" 0 "Valid" ;
VAL_ 1247 RrPTCoolFanStatV 1 "Invalid" 0 "Valid" ;
VAL_ 1247 RrPTCoolFanStat 0 "Off" 1 "On" ;
VAL_ 873 FrtCmModIntgStat 0 "Pass" 1 "Fail" ;
VAL_ 873 FrtCmModAsmt 0 "No Problem" 1 "Improper Response" 2 "Repeated Challenge" ;
VAL_ 723 PerfTrcEngSpdRqStat 6 "Control System Failure Permanent" 5 "Control System Failure Temporary" 4 "Serial Data Failure Permanent" 3 "Serial Data Failure Temporary" 2 "Lost Arbitration" 1 "Request Honored" 0 "No Request" ;
VAL_ 723 PerfTrcEngSpdLmtStat 3 "Rate & Value Limited" 2 "Value Limited" 1 "Rate Limited" 0 "Not Limited" ;
VAL_ 723 PerfTrcTrqRqStat 6 "Control System Failure Permanent" 5 "Control System Failure Temporary" 4 "Serial Data Failure Permanent" 3 "Serial Data Failure Temporary" 2 "Lost Arbitration" 1 "Request Honored" 0 "No Request" ;
VAL_ 723 PerfTrcTrqLmtStat 3 "Rate & Value Limited" 2 "Value Limited" 1 "Rate Limited" 0 "Not Limited" ;
VAL_ 405 EngDistFuelMdDefltd 1 "true" 0 "false" ;
VAL_ 405 EngInjEnbldD 1 "true" 0 "false" ;
VAL_ 405 EngInjEnbldC 1 "true" 0 "false" ;
VAL_ 405 EngInjEnbldB 1 "true" 0 "false" ;
VAL_ 405 EngInjEnbldA 1 "true" 0 "false" ;
VAL_ 405 ThrPosV 1 "Invalid" 0 "Valid" ;
VAL_ 405 MassAirFloV 1 "Invalid" 0 "Valid" ;
VAL_ 405 EngManfldAbsPrsERV 1 "Invalid" 0 "Valid" ;
VAL_ 419 EngRunng 1 "true" 0 "false" ;
VAL_ 289 ARDM_MsgType 0 "Reserved 1" 1 "Position" 2 "Segment" 3 "Stub" 4 "Profile Short" 5 "Profile Long" 6 "Meta Data" 7 "Reserved 2" ;
VAL_ 871 ACCModIntgStat 0 "Pass" 1 "Fail" ;
VAL_ 871 AdptCrsCtrlModAsmt 0 "No Problem" 1 "Improper Response" 2 "Repeated Challenge" ;
VAL_ 800 FCACBSC_AutBrkRpRt 0 "None" 1 "Light" 2 "Full" 3 "Reserved" ;
VAL_ 800 FCACBSC_AutBrkRqTp 0 "None" 1 "Prefill" 2 "Haptic Pulse" 3 "Brake Per Requested Decel" 4 "Apply Park Brake" 5 "Hold" 6 "Lower Panic Brake Threshold" 7 "Reserved" 8 "Object Detected/Confirmation" ;
VAL_ 800 FCACBSC_AutBrkRqd 1 "true" 0 "false" ;
VAL_ 388 HndsOffStrWhlDtStV 1 "Invalid" 0 "Valid" ;
VAL_ 388 HndsOffStrWhlDtSt 0 "Hands Off" 1 "Hands On" ;
VAL_ 388 HndsOffStrWhlDtMd 0 "Disabled" 1 "Enabled" 2 "Failed" ;
VAL_ 388 LKATrqOvrlTrqDStat 0 "Inactive" 1 "Active" 2 "Temporarily Limited" 3 "Permanently Failed" ;
VAL_ 388 LKADrvAppldTrqV 1 "Invalid" 0 "Valid" ;
VAL_ 384 LKATODC_TrqRqAct 1 "true" 0 "false" ;
VAL_ 866 ColPrSysHzrdLghtsReq 0 "No Action" 1 "Activate" 2 "Deactivate" 3 "Reserved" ;
VAL_ 866 ColPrSysWndwsReq 0 "No Action" 1 "Close" 2 "Open" 3 "Reserved" ;
VAL_ 866 ColPrSysDrsReq 0 "No Action" 1 "Lock All" 2 "Unlock All" 3 "Reserved" ;
VAL_ 866 ColPrSysSnrfReq 0 "No Action" 1 "Close" 2 "Open" 3 "Reserved" ;
VAL_ 866 CPSInfotmntMtReq 0 "No Mute" 1 "Unused and Reserved 1" 2 "Unused and Reserved 2" 3 "Mute" ;
VAL_ 866 StBltTgtSetAvl 1 "true" 0 "false" ;
VAL_ 866 StBltTgtCrtSetVal 0 "No Action" 1 "Low" 2 "Normal" 3 "Performance" 4 "Locked" ;
VAL_ 866 MotStBltUnblIO 1 "true" 0 "false" ;
VAL_ 866 MotStBltFldIO 1 "true" 0 "false" ;
VAL_ 951 FuelInjCntrlModInjFltAct 1 "true" 0 "false" ;
VAL_ 951 AFRP_SnsTyp 3 "Gauge Pressure" 2 "Absolute Pressure" 1 "Pressure Relative Manifold Vacuum" 0 "Not Supported" ;
VAL_ 951 FICMDS3_DTCStatus 4 "Diagnostic Failed" 3 "Diagnostic Passed" 2 "No Status to Report" 1 "Critically Disabled" 0 "Not Supported" ;
VAL_ 951 FICMDS2_DTCStatus 4 "Diagnostic Failed" 3 "Diagnostic Passed" 2 "No Status to Report" 1 "Critically Disabled" 0 "Not Supported" ;
VAL_ 951 FICMDS1_DTCStatus 4 "Diagnostic Failed" 3 "Diagnostic Passed" 2 "No Status to Report" 1 "Critically Disabled" 0 "Not Supported" ;
VAL_ 1223 EngSnPwrECoolLpTmpV 1 "Invalid" 0 "Valid" ;
VAL_ 1223 PropSysOffTmeV 1 "Invalid" 0 "Valid" ;
VAL_ 1223 PropSysOffTmeM 1 "Use Data" 0 "Don't Use Data" ;
VAL_ 1227 BattThrmlCondOffTmeV 1 "Invalid" 0 "Valid" ;
VAL_ 1227 BattThrmlCondOffTmeM 1 "Use Data" 0 "Don't Use Data" ;
VAL_ 1227 OffBrdChrgOffTmeV 1 "Invalid" 0 "Valid" ;
VAL_ 1227 OffBrdChrgOffTmeM 1 "Use Data" 0 "Don't Use Data" ;
VAL_ 543 PTOTpStpSpdCsStReq 0 "No Action" 1 "5 rpm" 2 "10 rpm" 3 "25 rpm" 4 "50 rpm" 5 "100 rpm" 6 "250 rpm" 7 "500 rpm" ;
VAL_ 543 PTOStdbySpdCsStReq 0 "No Action" 1 "900 rpm" 2 "1000 rpm" 3 "1100 rpm" 4 "1200 rpm" 5 "1300 rpm" 6 "1400 rpm" 7 "1500 rpm" ;
VAL_ 543 PTOEngRnTmrCsStRq 0 "No Action" 1 "10 min" 2 "30 min" 3 "90 min" 4 "120 min" 5 "150 min" 6 "180 min" 7 "210 min" 8 "240 min" 9 "270 min" 10 "300 min" 11 "330 min" 12 "360 min" 13 "390 min" 14 "420 min" 15 "450 min" ;
VAL_ 543 PTOSet2SpdCsStReq 0 "No Action" 1 "1900 rpm" 2 "2000 rpm" 3 "2100 rpm" 4 "2200 rpm" 5 "2300 rpm" 6 "2400 rpm" 7 "2500 rpm" 8 "2600 rpm" 9 "2700 rpm" 10 "2800 rpm" 11 "2900 rpm" 12 "3000 rpm" 13 "3100 rpm" 14 "3200 rpm" 15 "3300 rpm" ;
VAL_ 543 PTOSet1SpdCsStReq 0 "No Action" 1 "1100 rpm" 2 "1200 rpm" 3 "1300 rpm" 4 "1400 rpm" 5 "1500 rpm" 6 "1600 rpm" 7 "1700 rpm" 8 "1800 rpm" 9 "1900 rpm" 10 "2000 rpm" 11 "2100 rpm" 12 "2200 rpm" 13 "2300 rpm" 14 "2400 rpm" 15 "2500 rpm" ;
VAL_ 544 PTOMobModTrnsInGrIO 1 "true" 0 "false" ;
VAL_ 544 PTOManTransInGrIO 1 "true" 0 "false" ;
VAL_ 544 PTOServIndOn 1 "true" 0 "false" ;
VAL_ 544 PTOEngUpnBrkRelIO 1 "true" 0 "false" ;
VAL_ 544 PTOAccelUpnBrkRelIO 1 "true" 0 "false" ;
VAL_ 544 PTOAudExtAlertReq 1 "true" 0 "false" ;
VAL_ 544 PTOTransInGearIO 1 "true" 0 "false" ;
VAL_ 544 PTOTpStpSpdCsStAvl 1 "true" 0 "false" ;
VAL_ 544 PTOTpStSpdCsCrStVal 0 "No Action" 1 "5 rpm" 2 "10 rpm" 3 "25 rpm" 4 "50 rpm" 5 "100 rpm" 6 "250 rpm" 7 "500 rpm" ;
VAL_ 544 PTOStdbySpdCsStAvl 1 "true" 0 "false" ;
VAL_ 544 PTOStdbSpdCsCrStVal 0 "No Action" 1 "900 rpm" 2 "1000 rpm" 3 "1100 rpm" 4 "1200 rpm" 5 "1300 rpm" 6 "1400 rpm" 7 "1500 rpm" ;
VAL_ 544 PTOSetPrkBrkIO 1 "true" 0 "false" ;
VAL_ 544 PTOSet2SpdCsStAvl 1 "true" 0 "false" ;
VAL_ 544 PTOSet2SpdCsCrStVal 0 "No Action" 1 "1900 rpm" 2 "2000 rpm" 3 "2100 rpm" 4 "2200 rpm" 5 "2300 rpm" 6 "2400 rpm" 7 "2500 rpm" 8 "2600 rpm" 9 "2700 rpm" 10 "2800 rpm" 11 "2900 rpm" 12 "3000 rpm" 13 "3100 rpm" 14 "3200 rpm" 15 "3300 rpm" ;
VAL_ 544 PTOSet1SpdCsStAvl 1 "true" 0 "false" ;
VAL_ 544 PTOSet1SpdCsCrStVal 0 "No Action" 1 "1100 rpm" 2 "1200 rpm" 3 "1300 rpm" 4 "1400 rpm" 5 "1500 rpm" 6 "1600 rpm" 7 "1700 rpm" 8 "1800 rpm" 9 "1900 rpm" 10 "2000 rpm" 11 "2100 rpm" 12 "2200 rpm" 13 "2300 rpm" 14 "2400 rpm" 15 "2500 rpm" ;
VAL_ 544 PTORelCltPedIO 1 "true" 0 "false" ;
VAL_ 544 PTORelBrkPedIO 1 "true" 0 "false" ;
VAL_ 544 PTORelAccPedIO 1 "true" 0 "false" ;
VAL_ 544 PTORedEngSpdIO 1 "true" 0 "false" ;
VAL_ 544 PTOPrsRelCltPedIO 1 "true" 0 "false" ;
VAL_ 544 PTOPrsRelBrkPedIO 1 "true" 0 "false" ;
VAL_ 544 PTOEngRnTmrCsStAvl 1 "true" 0 "false" ;
VAL_ 544 PTOEnRnTmCsCrStVal 0 "No Action" 1 "10 min" 2 "30 min" 3 "90 min" 4 "120 min" 5 "150 min" 6 "180 min" 7 "210 min" 8 "240 min" 9 "270 min" 10 "300 min" 11 "330 min" 12 "360 min" 13 "390 min" 14 "420 min" 15 "450 min" ;
VAL_ 544 PTOEngmntStatInd 0 "No Indication" 1 "Continuous Indication" 2 "Slow Flashing Indication" 3 "Fast Flashing Indication" ;
VAL_ 544 PTODisengCrsCntlIO 1 "true" 0 "false" ;
VAL_ 1032 RdTyp 0 "Town" 1 "Country Road" 2 "Motorway" 3 "Unused and Reserved 1" 4 "Unused and Reserved 2" 5 "Unused and Reserved 3" 6 "Unused and Reserved 4" 7 "Undefined" ;
VAL_ 1032 FwdCamSysOpStat 0 "Unknown" 1 "Initializing" 2 "Inactive" 3 "Active" 4 "Unused and Reserved 1" 5 "Unused and Reserved 2" 6 "Unused and Reserved 3" 7 "Failed" ;
VAL_ 1032 EnvIllum 0 "Unknown" 1 "Lit Environment During Night" 2 "Unlit Environment During Night" 3 "Daylight" ;
VAL_ 1032 AutoHgBmSts 0 "Not Available" 1 "Inactive" 2 "Active" ;
VAL_ 1031 GFHBFwVsnRelLaneTrk8 3 "Left Lane" 2 "Right Lane" 1 "Host Lane" 0 "Unknown" ;
VAL_ 1031 GFHBFwVsnCnfdncTrk8 3 "Confident" 2 "Speculative" 1 "Highly Speculative" 0 "Invalid" ;
VAL_ 1031 GFHBFVsnObjTypTrkRev8 12 "Cluster Object" 11 "Child Close to Danger Zone" 10 "Pedestrian Moving Out of Danger Zone" 9 "Pedestrian Moving Into Danger Zone" 8 "Pedestrian Standing Outside Danger Zone" 7 "No Object Present" 6 "Fixed Roadside Object" 5 "Fixed Overhead Object" 4 "Pedestrian" 3 "Motorcycle/ Bicycle" 2 "Large Vehicle (Semi)" 1 "4 Wheel Vehicle (Car)" 0 "Unknown" ;
VAL_ 1031 GFHBObjDirTrk8 1 "Ahead Traffic" 0 "Incoming Traffic" ;
VAL_ 1031 GFHBFwVsnMesStatTrk8 3 "Measured this cycle" 2 "Latent track not detected this cycle" 1 "New Object" 0 "No Object" ;
VAL_ 1030 GFHBFwVsnRelLaneTrk7 3 "Left Lane" 2 "Right Lane" 1 "Host Lane" 0 "Unknown" ;
VAL_ 1030 GFHBFwVsnCnfdncTrk7 3 "Confident" 2 "Speculative" 1 "Highly Speculative" 0 "Invalid" ;
VAL_ 1030 GFHBFVsnObjTypTrkRev7 12 "Cluster Object" 11 "Child Close to Danger Zone" 10 "Pedestrian Moving Out of Danger Zone" 9 "Pedestrian Moving Into Danger Zone" 8 "Pedestrian Standing Outside Danger Zone" 7 "No Object Present" 6 "Fixed Roadside Object" 5 "Fixed Overhead Object" 4 "Pedestrian" 3 "Motorcycle/ Bicycle" 2 "Large Vehicle (Semi)" 1 "4 Wheel Vehicle (Car)" 0 "Unknown" ;
VAL_ 1030 GFHBObjDirTrk7 1 "Ahead Traffic" 0 "Incoming Traffic" ;
VAL_ 1030 GFHBFwVsnMesStatTrk7 3 "Measured this cycle" 2 "Latent track not detected this cycle" 1 "New Object" 0 "No Object" ;
VAL_ 479 EngAutoStpNotProb 1 "true" 0 "false" ;
VAL_ 479 EASSI_UnsdRsrvd2 1 "true" 0 "false" ;
VAL_ 479 EASSI_StlDetd 1 "true" 0 "false" ;
VAL_ 479 EASSI_TrqDetd 1 "true" 0 "false" ;
VAL_ 479 EASSI_FuelReqOn 1 "true" 0 "false" ;
VAL_ 479 EASSI_StrtTyp 7 "Type G" 6 "Type F" 5 "Type E" 4 "Type D" 3 "Type C" 2 "Type B" 1 "Type A" 0 "No Start" ;
VAL_ 479 EASSI_StrtStpSt 3 "Engine Stopping" 2 "Engine Starting" 1 "Engine Running" 0 "Engine Off" ;
VAL_ 479 EASSI_TorqDetdIndet 1 "true" 0 "false" ;
VAL_ 479 ASIRI_Indication08 1 "true" 0 "false" ;
VAL_ 479 ASIRI_Indication07 1 "true" 0 "false" ;
VAL_ 479 ASIRI_Indication06 1 "true" 0 "false" ;
VAL_ 479 ASIRI_Indication05 1 "true" 0 "false" ;
VAL_ 479 ASIRI_Indication04 1 "true" 0 "false" ;
VAL_ 479 ASIRI_Indication03 1 "true" 0 "false" ;
VAL_ 479 ASIRI_Indication02 1 "true" 0 "false" ;
VAL_ 479 ASIRI_Indication01 1 "true" 0 "false" ;
VAL_ 479 PTWrmgWtToShftIO 1 "true" 0 "false" ;
VAL_ 479 PrplsnSysAtv 1 "true" 0 "false" ;
VAL_ 479 PTShftLvrLckRqd 1 "true" 0 "false" ;
VAL_ 211 ActAxleTrqV 1 "Invalid" 0 "Valid" ;
VAL_ 1020 OtsAirTmpEmsnsRelV 1 "Invalid" 0 "Valid" ;
VAL_ 1020 OATEmsnsRelCrValV 1 "Invalid" 0 "Valid" ;
VAL_ 1020 OATEmsnsRelCrValM 0 "Don't Use Data" 1 "Use Data" ;
VAL_ 1020 CatlystOutGasTempEstV 1 "Invalid" 0 "Valid" ;
VAL_ 1020 OtsAirTmpCrValMsk 0 "Don't Use Data" 1 "Use Data" ;
VAL_ 1020 OtsAirTmpV 1 "Invalid" 0 "Valid" ;
VAL_ 1020 OtsAirTmpCrValV 1 "Invalid" 0 "Valid" ;
VAL_ 1020 EngInltSpcfcHmdtyV 1 "Invalid" 0 "Valid" ;
VAL_ 1020 EngInltSpcfcHmdtyM 0 "Don't Use Data" 1 "Use Data" ;
VAL_ 567 ExtHlStrAssCsCrStVal 2 "Standard Hold" 1 "Extended Hold" 0 "No Action" ;
VAL_ 567 ExtHlStrAssCsStAvl 1 "true" 0 "false" ;
VAL_ 567 DrvStyPerfMdCsCrStVal 7 "Performance Mode 7" 6 "Performance Mode 6" 5 "Performance Mode 5" 4 "Performance Mode 4" 3 "Performance Mode 3" 2 "Performance Mode 2" 1 "Performance Mode 1" 0 "No Action" ;
VAL_ 567 DrvStyPerfMdCsStAvl 1 "true" 0 "false" ;
VAL_ 567 PsngStPerfMdCsCrStVal 7 "Auto" 6 "Performance Mode 6" 5 "Performance Mode 5" 4 "Performance Mode 4" 3 "Performance Mode 3" 2 "Performance Mode 2" 1 "Performance Mode 1" 0 "No Action" ;
VAL_ 567 PsngStPerfMdCsStAvl 1 "true" 0 "false" ;
VAL_ 567 DrvrStPerfMdCsCrStVal 7 "Auto" 6 "Performance Mode 6" 5 "Performance Mode 5" 4 "Performance Mode 4" 3 "Performance Mode 3" 2 "Performance Mode 2" 1 "Performance Mode 1" 0 "No Action" ;
VAL_ 567 DrvrStPerfMdCsStAvl 1 "true" 0 "false" ;
VAL_ 567 ACCPerfMdCsCrStVal 7 "Auto" 6 "Performance Mode 6" 5 "Performance Mode 5" 4 "Performance Mode 4" 3 "Performance Mode 3" 2 "Performance Mode 2" 1 "Performance Mode 1" 0 "No Action" ;
VAL_ 567 ACCPerfMdCsStAvl 1 "true" 0 "false" ;
VAL_ 1219 DslExhFldDiagWrnIdRq 0 "No Indication" 1 "Warning Level 1" 2 "Warning Level 2" 3 "Warning Level 3" 4 "Warning Level 4" 5 "Warning Level 5" 6 "Warning Level 6" 7 "Warning Level 7" ;
VAL_ 1219 DslEmnsOBDMrkt 0 "USEPA TIER 2 / CALIFORNIA LEV II" 1 "EURO5/6" ;
VAL_ 1219 DslExNxEmWrngIndRq 15 "Warning Level 15" 14 "Warning Level 14" 13 "Warning Level 13" 12 "Warning Level 12" 11 "Warning Level 11" 10 "Warning Level 10" 9 "Warning Level 9" 8 "Warning Level 8" 7 "Warning Level 7" 6 "Warning Level 6" 5 "Warning Level 5" 4 "Warning Level 4" 3 "Warning Level 3" 2 "Warning Level 2" 1 "Warning Level 1" 0 "No Indication" ;
VAL_ 1219 DslExFldTpWrngIndRq 15 "Warning Level 15" 14 "Warning Level 14" 13 "Warning Level 13" 12 "Warning Level 12" 11 "Warning Level 11" 10 "Warning Level 10" 9 "Warning Level 9" 8 "Warning Level 8" 7 "Warning Level 7" 6 "Warning Level 6" 5 "Warning Level 5" 4 "Warning Level 4" 3 "Warning Level 3" 2 "Warning Level 2" 1 "Warning Level 1" 0 "No Indication" ;
VAL_ 1219 DslExhFldQlyWrngIReq 15 "Warning Level 15" 14 "Warning Level 14" 13 "Warning Level 13" 12 "Warning Level 12" 11 "Warning Level 11" 10 "Warning Level 10" 9 "Warning Level 9" 8 "Warning Level 8" 7 "Warning Level 7" 6 "Warning Level 6" 5 "Warning Level 5" 4 "Warning Level 4" 3 "Warning Level 3" 2 "Warning Level 2" 1 "Warning Level 1" 0 "No Indication" ;
VAL_ 1219 DslExhFldWrngIdRqER 15 "Warning Level 15" 14 "Warning Level 14" 13 "Warning Level 13" 12 "Warning Level 12" 11 "Warning Level 11" 10 "Warning Level 10" 9 "Warning Level 9" 8 "Warning Level 8" 7 "Warning Level 7" 6 "Warning Level 6" 5 "Warning Level 5" 4 "Warning Level 4" 3 "Warning Level 3" 2 "Warning Level 2" 1 "Warning Level 1" 0 "No Indication" ;
VAL_ 1219 DslExFldCnWrngIndRq 15 "Warning Level 15" 14 "Warning Level 14" 13 "Warning Level 13" 12 "Warning Level 12" 11 "Warning Level 11" 10 "Warning Level 10" 9 "Warning Level 9" 8 "Warning Level 8" 7 "Warning Level 7" 6 "Warning Level 6" 5 "Warning Level 5" 4 "Warning Level 4" 3 "Warning Level 3" 2 "Warning Level 2" 1 "Warning Level 1" 0 "No Indication" ;
VAL_ 372 ARSFlrIO 1 "true" 0 "false" ;
VAL_ 528 BSABR_TrlBrkCntlIntRq 1 "true" 0 "false" ;
VAL_ 442 CrksftTqMinImCapV 1 "Invalid" 0 "Valid" ;
VAL_ 442 CrksftMaxTrqLmtV 1 "Invalid" 0 "Valid" ;
VAL_ 753 EBCMDS5_DTCStatus 0 "Not Supported" 1 "Critically Disabled" 2 "No Status to Report" 3 "Diagnostic Passed" 4 "Diagnostic Failed" ;
VAL_ 753 EBCMDS4_DTCStatus 0 "Not Supported" 1 "Critically Disabled" 2 "No Status to Report" 3 "Diagnostic Passed" 4 "Diagnostic Failed" ;
VAL_ 753 EBCMDS3_DTCStatus 0 "Not Supported" 1 "Critically Disabled" 2 "No Status to Report" 3 "Diagnostic Passed" 4 "Diagnostic Failed" ;
VAL_ 753 EBCMDS2_DTCStatus 0 "Not Supported" 1 "Critically Disabled" 2 "No Status to Report" 3 "Diagnostic Passed" 4 "Diagnostic Failed" ;
VAL_ 753 EBCMDS1_DTCStatus 0 "Not Supported" 1 "Critically Disabled" 2 "No Status to Report" 3 "Diagnostic Passed" 4 "Diagnostic Failed" ;
VAL_ 989 RdHVCntctrShdwnReq 0 "None" 1 "Emergency Shutdown" 2 "Controlled Shutdown" 3 "Emergency Crash Shutdown" ;
VAL_ 989 AuxClntHtrVlvStat 7 "Unused and Reserved 2" 6 "De-Aeration Routine Active" 5 "Diagnostic Override" 4 "Re-Calibration" 3 "Fault Active" 2 "Engine Link" 1 "Transition" 0 "Engine Bypass" ;
VAL_ 989 EngCoolFanOpEnbl 1 "true" 0 "false" ;
VAL_ 989 DiagFreeRunCntrV 1 "Invalid" 0 "Valid" ;
VAL_ 989 JmpStrtEnbld 1 "true" 0 "false" ;
VAL_ 989 MntnceMdStEngRq 1 "true" 0 "false" ;
VAL_ 989 ThrmlRefCompSpdV 1 "Invalid" 0 "Valid" ;
VAL_ 989 RdHVCntctrCmdStat 0 "Open" 1 "Precharge" 2 "Close" ;
VAL_ 550 ACCMCII_DatStat 0 "Cal ID Index Not Used" 1 "Cal Verification Number Uncalculated" 2 "Cal Verification Number Calculated" ;
VAL_ 988 EGHRInhbtRqstd 1 "true" 0 "false" ;
VAL_ 988 AccPwrModMinCoolRq 0 "None" 1 "Minimum" 2 "Low" 3 "Medium" 4 "High" ;
VAL_ 988 A6ERRAlrmReq 2 "Cancel Alarm" 1 "Set Alarm" 0 "No Action" ;
VAL_ 988 MntnceMdDsplyRq 15 "Unused and Reserved" 14 "Continue FM" 13 "Force FM" 12 "FM 1 Day Warning" 11 "FM 2 Day Warning" 10 "FM 3 Day Warning" 9 "FM 4 Day Warning" 8 "FM 5 Day Warning" 7 "Continue EM" 6 "Force EM" 5 "EM 1 Day Warning" 4 "EM 2 Day Warning" 3 "EM 3 Day Warning" 2 "EM 4 Day Warning" 1 "EM 5 Day Warning" 0 "No Request" ;
VAL_ 988 EngMntnceMdAct 1 "true" 0 "false" ;
VAL_ 988 HVPropChgrUnbl 1 "true" 0 "false" ;
VAL_ 988 EngHtrValvBpasCmd 0 "Bypass Commanded" 1 "Normal Operation Allowed" ;
SIG_GROUP_ 563 SusPerfMdCustAvl 1 : SPMCA_SusPrfMd6Avl SPMCA_SusPrfMd5Avl SPMCA_SusPrfMd4Avl SPMCA_SusPrfMd3Avl SPMCA_SusPrfMd2Avl SPMCA_SusPrfMd1Avl;
SIG_GROUP_ 563 StrPerfMdCustAvl 1 : SPMCA_StrPrfMd6Avl SPMCA_StrPrfMd5Avl SPMCA_StrPrfMd4Avl SPMCA_StrPrfMd3Avl SPMCA_StrPrfMd2Avl SPMCA_StrPrfMd1Avl;
SIG_GROUP_ 563 SndPerfMdCustAvl 1 : SPMCA_SndPrfMd6Avl SPMCA_SndPrfMd5Avl SPMCA_SndPrfMd4Avl SPMCA_SndPrfMd3Avl SPMCA_SndPrfMd2Avl SPMCA_SndPrfMd1Avl;
SIG_GROUP_ 563 DispPerfCustMdAvl 1 : DPMCA_DispPrfMd6Avl DPMCA_DispPrfMd5Avl DPMCA_DispPrfMd4Avl DPMCA_DispPrfMd3Avl DPMCA_DispPrfMd2Avl DPMCA_DispPrfMd1Avl;
SIG_GROUP_ 563 DrvlnPerfMdCustAvl 1 : DPMCA_DrvlPrfMd6Avl DPMCA_DrvlPrfMd5Avl DPMCA_DrvlPrfMd4Avl DPMCA_DrvlPrfMd3Avl DPMCA_DrvlPrfMd2Avl DPMCA_DrvlPrfMd1Avl;
SIG_GROUP_ 873 AdptCrsCtrlModRsp 1 : ACCMR_RptdChlng ACCMR_Answr;
SIG_GROUP_ 289 ADASISRawDatMplxd 1 : ARDM_RawData ARDM_MsgType;
SIG_GROUP_ 871 FrtCmModRsp 1 : FCMR_RptdChlng FCMR_Answr;
SIG_GROUP_ 800 FCACtrlBrkSysCmd 1 : FCACBSC_CtrlAcc FCACBSC_AutBrkRpRt FCACBSC_AutBrkRqTp FCACBSC_AutBrkRqd;
SIG_GROUP_ 384 LKATqOvrDltCmd 1 : LKATODC_TrqVl LKATODC_TrqRqAct;
SIG_GROUP_ 951 AltFuelRailPrs 1 : AFRP_RailPrs AFRP_SnsTyp;
SIG_GROUP_ 951 FuelInjCntrlModDiagSt3 1 : FICMDS3_DTCStatus FICMDS3_DTCIndx;
SIG_GROUP_ 951 FuelInjCntrlModDiagSt2 1 : FICMDS2_DTCStatus FICMDS2_DTCIndx;
SIG_GROUP_ 951 FuelInjCntrlModDiagSt1 1 : FICMDS1_DTCStatus FICMDS1_DTCIndx;
SIG_GROUP_ 479 EngAutoStrtStpInfo 1 : EASSI_UnsdRsrvd2 EASSI_StlDetd EASSI_TrqDetd EASSI_FuelReqOn EASSI_StrtTyp EASSI_StrtStpSt EASSI_TorqDetdIndet;
SIG_GROUP_ 479 AutoStpInhbtRsnInd 1 : ASIRI_Indication08 ASIRI_Indication07 ASIRI_Indication06 ASIRI_Indication05 ASIRI_Indication04 ASIRI_Indication03 ASIRI_Indication02 ASIRI_Indication01;
SIG_GROUP_ 1219 DslExFldWrngVSpdLmt 1 : DEFWVSL_S3SpdLmt DEFWVSL_S2SpdLmt DEFWVSL_S1SpdLmt;
SIG_GROUP_ 528 BrkSysAutBrkReq 1 : BSABR_TrlBrkRq BSABR_TrlBrkCntlIntRq;
SIG_GROUP_ 753 ElecBrkCntlMdlDiagSt5 1 : EBCMDS5_DTCStatus EBCMDS5_DTCIndex;
SIG_GROUP_ 753 ElecBrkCntlMdlDiagSt4 1 : EBCMDS4_DTCStatus EBCMDS4_DTCIndex;
SIG_GROUP_ 753 ElecBrkCntlMdlDiagSt3 1 : EBCMDS3_DTCStatus EBCMDS3_DTCIndex;
SIG_GROUP_ 753 ElecBrkCntlMdlDiagSt2 1 : EBCMDS2_DTCStatus EBCMDS2_DTCIndex;
SIG_GROUP_ 753 ElecBrkCntlMdlDiagSt1 1 : EBCMDS1_DTCStatus EBCMDS1_DTCIndex;
SIG_GROUP_ 550 ACCModCalIdInf 1 : ACCMCII_DtBtG ACCMCII_DtBtF ACCMCII_DtBtE ACCMCII_DtBtD ACCMCII_DtBtC ACCMCII_DtBtB ACCMCII_DtBtA ACCMCII_SeqNum ACCMCII_Index ACCMCII_DatStat;
SIG_GROUP_ 988 Alrm6ExtRngReq 1 : A6ERRAlrmTime A6ERRAlrmReq;
